VERSION "dbc-export 1 2026.26.6.5"

NS_ :

BS_:

BU_: ADSP APB APP APS APSB BB BMS CC CMP CMPD CP DAS DI DIF DIR DPB EPAS3P EPAS3S EPASTP EPASTS EPBL EPBR ESP EVSE FC GTW HCML HCMR HVP IBST ICR IDB LS OCS1P PARK PCS PCS2 PM PMF PMR PNCD PTC RADC RCM RCM2 RCM3 RCU SCCM SCM SCS SDCR TAS TCU TCU2 TPMS TRCM UI UIS UMC USM V2G VC VCBATT VCBATT0 VCBATT1 VCBATT2 VCCC VCFRONT VCFRONT1 VCFRONT2 VCLEFT VCRIGHT VCSEAT2L VCSEAT2R VCSEC VEH

BO_ 789 DIR_temperature: 8 DIR
 SG_ DIR_tempIndex M : 0|3@1+ (1,0) [0|7] "" Vector__XXX
 SG_ DIR_inverterTQF m0 : 3|2@1+ (1,0) [0|3] "" Vector__XXX
 SG_ DIR_pcbT m0 : 8|8@1+ (1,-40) [-40|215] "DegC" Vector__XXX
 SG_ DIR_inverterT m0 : 16|8@1+ (1,-40) [-40|215] "DegC" Vector__XXX
 SG_ DIR_statorT m0 : 24|8@1+ (1,-40) [-40|215] "DegC" Vector__XXX
 SG_ DIR_dcCapT m0 : 32|8@1+ (1,-40) [-40|215] "DegC" Vector__XXX
 SG_ DIR_heatsinkT m0 : 40|8@1+ (1,-40) [-40|215] "DegC" Vector__XXX
 SG_ DIR_inverterTpct m0 : 48|8@1+ (0.4,0) [0|100] "%" Vector__XXX
 SG_ DIR_statorTpct m0 : 56|8@1+ (0.4,0) [0|100] "%" Vector__XXX
 SG_ DIR_fluidInTemp m2 : 8|8@1+ (1,-40) [-40|215] "DegC" Vector__XXX
 SG_ DIR_normalFetBurnIn m2 : 16|16@1+ (0.00763,0) [0|500] "Hours" Vector__XXX
 SG_ DIR_additionalFetBurnIn m2 : 32|16@1+ (0.00763,0) [0|500] "Hours" Vector__XXX
 SG_ DIR_currentWeibullMiles m3 : 3|16@1+ (8,0) [0|500000] "miles" Vector__XXX
 SG_ DIR_endOfServiceWeibullMiles m3 : 19|16@1+ (8,0) [0|500000] "miles" Vector__XXX
 SG_ DIR_burnInDamageRatio m3 : 35|9@1+ (0.01,0) [0|5] "1" Vector__XXX
 SG_ DIR_inverterSensorEst m3 : 44|8@1+ (1,-40) [-40|120] "C" Vector__XXX
 SG_ DIR_inverterHS1Est m3 : 52|8@1+ (1,-40) [-40|120] "C" Vector__XXX
 SG_ DIR_initialBurnInVehicleOdometer m4 : 8|32@1+ (0.001,0) [0|4294967.294] "km" Vector__XXX
 SG_ DIR_inverterHS2Est m4 : 40|8@1+ (1,-40) [-40|120] "C" Vector__XXX
 SG_ DIR_inverterInletEst m4 : 48|8@1+ (1,-40) [-40|120] "C" Vector__XXX
 SG_ DIR_statorHousingTemp m4 : 56|8@1+ (1,-40) [-40|215] "DegC" Vector__XXX

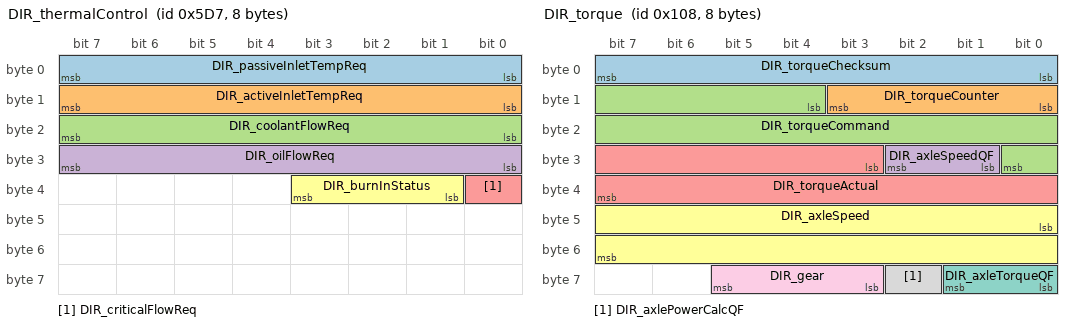
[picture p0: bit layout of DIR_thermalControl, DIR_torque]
BO_ 1495 DIR_thermalControl: 8 DIR
 SG_ DIR_passiveInletTempReq : 0|8@1+ (1,-40) [-40|215] "DegC" Vector__XXX
 SG_ DIR_activeInletTempReq : 8|8@1+ (1,-40) [-40|215] "DegC" Vector__XXX
 SG_ DIR_coolantFlowReq : 16|8@1+ (0.2,0) [0|50] "LPM" Vector__XXX
 SG_ DIR_oilFlowReq : 24|8@1+ (0.1,0) [0|25.4] "LPM" Vector__XXX
 SG_ DIR_criticalFlowReq : 32|1@1+ (1,0) [0|1] "" Vector__XXX
 SG_ DIR_burnInStatus : 33|3@1+ (1,0) [0|7] "" Vector__XXX

BO_ 264 DIR_torque: 8 DIR
 SG_ DIR_torqueChecksum : 0|8@1+ (1,0) [0|255] "" Vector__XXX
 SG_ DIR_torqueCounter : 8|4@1+ (1,0) [0|15] "" Vector__XXX
 SG_ DIR_torqueCommand : 12|13@1- (2,0) [-7500|7500] "Nm" Vector__XXX
 SG_ DIR_axleSpeedQF : 25|2@1+ (1,0) [0|3] "" Vector__XXX
 SG_ DIR_torqueActual : 27|13@1- (2,0) [-7500|7500] "Nm" Vector__XXX
 SG_ DIR_axleSpeed : 40|16@1- (0.1,0) [-2750|2750] "RPM" Vector__XXX
 SG_ DIR_axleTorqueQF : 56|2@1+ (1,0) [0|3] "" Vector__XXX
 SG_ DIR_axlePowerCalcQF : 58|1@1+ (1,0) [0|1] "" Vector__XXX
 SG_ DIR_gear : 59|3@1+ (1,0) [0|7] "" Vector__XXX

BO_ 1319 DI_alertLog: 8 DI
 SG_ DI_alertID M : 0|8@1+ (1,0) [0|255] "" Vector__XXX
 SG_ DI_alertState : 15|1@1+ (1,0) [0|1] "" Vector__XXX
 SG_ DI_a004_unavailableReason m4 : 16|5@1+ (1,0) [0|31] "" Vector__XXX
 SG_ DI_a007_button m7 : 16|2@1+ (1,0) [0|3] "" Vector__XXX
 SG_ DI_a007_buttonStuckTime m7 : 24|15@1+ (0.25,0) [0|8191.75] "" Vector__XXX
 SG_ DI_a010_sccReset m10 : 16|1@1+ (1,0) [0|1] "" Vector__XXX
 SG_ DI_a010_hibernate m10 : 17|1@1+ (1,0) [0|1] "" Vector__XXX
 SG_ DI_a010_hwBist m10 : 18|1@1+ (1,0) [0|1] "" Vector__XXX
 SG_ DI_a010_nmiWatchdog m10 : 19|1@1+ (1,0) [0|1] "" Vector__XXX
 SG_ DI_a010_watchdog m10 : 20|1@1+ (1,0) [0|1] "" Vector__XXX
 SG_ DI_a010_clockFailNmi m10 : 21|1@1+ (1,0) [0|1] "" Vector__XXX
 SG_ DI_a010_ramUncErrorNmi m10 : 22|1@1+ (1,0) [0|1] "" Vector__XXX
 SG_ DI_a010_flashUncErrorNmi m10 : 23|1@1+ (1,0) [0|1] "" Vector__XXX
 SG_ DI_a010_cpu1signMismatchNmi m10 : 24|1@1+ (1,0) [0|1] "" Vector__XXX
 SG_ DI_a010_cpu2signMismatchNmi m10 : 25|1@1+ (1,0) [0|1] "" Vector__XXX
 SG_ DI_a010_pieVectErrorNmi m10 : 26|1@1+ (1,0) [0|1] "" Vector__XXX
 SG_ DI_a010_sysDbgNmi m10 : 27|1@1+ (1,0) [0|1] "" Vector__XXX
 SG_ DI_a010_rlNmi m10 : 28|1@1+ (1,0) [0|1] "" Vector__XXX
 SG_ DI_a010_ovfNmi m10 : 29|1@1+ (1,0) [0|1] "" Vector__XXX
 SG_ DI_a010_wdtFlags m10 : 32|16@1+ (1,0) [0|65535] "" Vector__XXX
 SG_ DI_a012_accel1SupplyV m12 : 16|16@1+ (0.001,0) [0|65.535] "" Vector__XXX
 SG_ DI_a012_accel2SupplyV m12 : 32|16@1+ (0.001,0) [0|65.535] "" Vector__XXX
 SG_ DI_a013_address m13 : 16|32@1+ (1,0) [0|4294967295] "" Vector__XXX
 SG_ DI_a013_errorType m13 : 48|4@1+ (1,0) [0|15] "" Vector__XXX
 SG_ DI_a015_reason m15 : 16|1@1+ (1,0) [0|1] "" Vector__XXX
 SG_ DI_a020_difHvilStatus m20 : 16|2@1+ (1,0) [0|3] "" Vector__XXX
 SG_ DI_a020_difStatusValid m20 : 18|1@1+ (1,0) [0|1] "" Vector__XXX
 SG_ DI_a020_dirHvilStatus m20 : 19|2@1+ (1,0) [0|3] "" Vector__XXX
 SG_ DI_a020_dirStatusValid m20 : 21|1@1+ (1,0) [0|1] "" Vector__XXX
 SG_ DI_a020_vehiclePowerState m20 : 22|2@1+ (1,0) [0|3] "" Vector__XXX
 SG_ DI_a020_hvilSystemStatus m20 : 24|2@1+ (1,0) [0|3] "" Vector__XXX
 SG_ DI_a021_packVoltage m21 : 16|16@1+ (0.1,0) [0|6553.5] "" Vector__XXX
 SG_ DI_a021_maxBusVoltage m21 : 32|16@1+ (0.1,0) [0|6553.5] "" Vector__XXX
 SG_ DI_a024_pedalPos m24 : 16|8@1+ (0.4,0) [0|102] "" Vector__XXX
 SG_ DI_a024_brakePressed m24 : 24|1@1+ (1,0) [0|1] "" Vector__XXX
 SG_ DI_a024_currentGear m24 : 25|3@1+ (1,0) [0|7] "" Vector__XXX
 SG_ DI_a025_backfillState m25 : 16|2@1+ (1,0) [0|3] "" Vector__XXX
 SG_ DI_a025_bfillUnavailableReason m25 : 18|5@1+ (1,0) [0|31] "" Vector__XXX
 SG_ DI_a036_numFaultedUnits m36 : 16|4@1+ (1,0) [0|15] "" Vector__XXX
 SG_ DI_a036_numAvailableUnits m36 : 20|4@1+ (1,0) [0|15] "" Vector__XXX
 SG_ DI_a040_torque m40 : 16|1@1+ (1,0) [0|1] "" Vector__XXX
 SG_ DI_a040_capability m40 : 17|1@1+ (1,0) [0|1] "" Vector__XXX
 SG_ DI_a040_power m40 : 18|1@1+ (1,0) [0|1] "" Vector__XXX
 SG_ DI_a040_status m40 : 19|1@1+ (1,0) [0|1] "" Vector__XXX
 SG_ DI_a040_capability2 m40 : 20|1@1+ (1,0) [0|1] "" Vector__XXX
 SG_ DI_a040_hvStatus m40 : 21|1@1+ (1,0) [0|1] "" Vector__XXX
 SG_ DI_a040_temperature m40 : 22|1@1+ (1,0) [0|1] "" Vector__XXX
 SG_ DI_a042_state4 m42 : 16|1@1+ (1,0) [0|1] "" Vector__XXX
 SG_ DI_a043_state4 m43 : 16|1@1+ (1,0) [0|1] "" Vector__XXX
 SG_ DI_a051_dcCableCurrentEst m51 : 16|16@1- (0.1,0) [-3276.8|3276.7] "" Vector__XXX
 SG_ DI_a051_packCurrent m51 : 32|16@1- (0.1,0) [-3276.8|3276.7] "" Vector__XXX
 SG_ DI_a052_torque m52 : 16|1@1+ (1,0) [0|1] "" Vector__XXX
 SG_ DI_a052_capability m52 : 17|1@1+ (1,0) [0|1] "" Vector__XXX
 SG_ DI_a052_power m52 : 18|1@1+ (1,0) [0|1] "" Vector__XXX
 SG_ DI_a052_status m52 : 19|1@1+ (1,0) [0|1] "" Vector__XXX
 SG_ DI_a052_capability2 m52 : 20|1@1+ (1,0) [0|1] "" Vector__XXX
 SG_ DI_a052_hvStatus m52 : 21|1@1+ (1,0) [0|1] "" Vector__XXX
 SG_ DI_a052_temperature m52 : 22|1@1+ (1,0) [0|1] "" Vector__XXX
 SG_ DI_a062_limpReason m62 : 16|6@1+ (1,0) [0|63] "" Vector__XXX
 SG_ DI_a063_gpoReason m63 : 16|4@1+ (1,0) [0|15] "" Vector__XXX
 SG_ DI_a064_hvState m64 : 16|3@1+ (1,0) [0|7] "" Vector__XXX
 SG_ DI_a064_vehiclePowerState m64 : 19|2@1+ (1,0) [0|3] "" Vector__XXX
 SG_ DI_a064_vehicleSpeed m64 : 24|12@1+ (0.08,-40) [-40|287.6] "" Vector__XXX
 SG_ DI_a074_recoveredGear m74 : 16|3@1+ (1,0) [0|7] "" Vector__XXX
 SG_ DI_a074_vehicleSpeed m74 : 19|12@1+ (0.08,-40) [-40|287.6] "" Vector__XXX
 SG_ DI_a074_attemptCount m74 : 32|4@1+ (1,0) [0|15] "" Vector__XXX
 SG_ DI_a074_unit0Gear m74 : 36|3@1+ (1,0) [0|7] "" Vector__XXX
 SG_ DI_a074_unit1Gear m74 : 40|3@1+ (1,0) [0|7] "" Vector__XXX
 SG_ DI_a074_unit2Gear m74 : 43|3@1+ (1,0) [0|7] "" Vector__XXX
 SG_ DI_a074_failureReason m74 : 48|4@1+ (1,0) [0|15] "" Vector__XXX
 SG_ DI_a074_epbSystemStatus m74 : 52|4@1+ (1,0) [0|15] "" Vector__XXX
 SG_ DI_a076_lvSupplyV m76 : 16|16@1+ (0.001,0) [0|65.535] "" Vector__XXX
 SG_ DI_a077_lvSupplyV m77 : 16|16@1+ (0.001,0) [0|65.535] "" Vector__XXX
 SG_ DI_a078_adcRefChan m78 : 16|4@1+ (1,0) [0|15] "" Vector__XXX
 SG_ DI_a078_adcRefLowAvg m78 : 24|16@1+ (1,0) [0|65535] "" Vector__XXX
 SG_ DI_a079_adcRefChan m79 : 16|4@1+ (1,0) [0|15] "" Vector__XXX
 SG_ DI_a079_adcRefHighAvg m79 : 24|16@1+ (1,0) [0|65535] "" Vector__XXX
 SG_ DI_a083_brakeSwitchNO m83 : 16|1@1+ (1,0) [0|1] "" Vector__XXX
 SG_ DI_a083_brakeSwitchNC m83 : 17|1@1+ (1,0) [0|1] "" Vector__XXX
 SG_ DI_a083_brakeSwitchIrrationalNO m83 : 18|1@1+ (1,0) [0|1] "" Vector__XXX
 SG_ DI_a083_brakeSwitchIrrationalNC m83 : 19|1@1+ (1,0) [0|1] "" Vector__XXX
 SG_ DI_a086_DPB_actuator3 m86 : 16|1@1+ (1,0) [0|1] "" Vector__XXX
 SG_ DI_a086_DPB_redundantBrakingStat m86 : 17|1@1+ (1,0) [0|1] "" Vector__XXX
 SG_ DI_a087_gtwCarConfig m87 : 16|1@1+ (1,0) [0|1] "" Vector__XXX
 SG_ DI_a087_gtwTime m87 : 17|1@1+ (1,0) [0|1] "" Vector__XXX
 SG_ DI_a087_gtwUpdateStatus m87 : 18|1@1+ (1,0) [0|1] "" Vector__XXX
 SG_ DI_a087_gearControl m87 : 19|1@1+ (1,0) [0|1] "" Vector__XXX
 SG_ DI_a087_carState m87 : 20|1@1+ (1,0) [0|1] "" Vector__XXX
 SG_ DI_a089_SCCM_rightStalk m89 : 16|1@1+ (1,0) [0|1] "" Vector__XXX
 SG_ DI_a090_reason m90 : 16|1@1+ (1,0) [0|1] "" Vector__XXX
 SG_ DI_a090_systemState m90 : 17|1@1+ (1,0) [0|1] "" Vector__XXX
 SG_ DI_a090_state m90 : 18|1@1+ (1,0) [0|1] "" Vector__XXX
 SG_ DI_a090_locState m90 : 19|1@1+ (1,0) [0|1] "" Vector__XXX
 SG_ DI_a090_state2 m90 : 20|1@1+ (1,0) [0|1] "" Vector__XXX
 SG_ DI_a090_state4 m90 : 21|1@1+ (1,0) [0|1] "" Vector__XXX
 SG_ DI_a091_ESP_brakeTorque m91 : 16|1@1+ (1,0) [0|1] "" Vector__XXX
 SG_ DI_a091_ESP_wheelSpeeds m91 : 17|1@1+ (1,0) [0|1] "" Vector__XXX
 SG_ DI_a091_ESP_wheelRotation m91 : 18|1@1+ (1,0) [0|1] "" Vector__XXX
 SG_ DI_a091_ESP_motorLimits m91 : 19|1@1+ (1,0) [0|1] "" Vector__XXX
 SG_ DI_a091_ESP_offsets m91 : 20|1@1+ (1,0) [0|1] "" Vector__XXX
 SG_ DI_a091_ESP_status m91 : 21|1@1+ (1,0) [0|1] "" Vector__XXX
 SG_ DI_a091_ESP_party3 m91 : 22|1@1+ (1,0) [0|1] "" Vector__XXX
 SG_ DI_a091_ESP_redundantBrakingStat m91 : 23|1@1+ (1,0) [0|1] "" Vector__XXX
 SG_ DI_a092_bmsStatus m92 : 16|1@1+ (1,0) [0|1] "" Vector__XXX
 SG_ DI_a092_bmsDriveLimits m92 : 17|1@1+ (1,0) [0|1] "" Vector__XXX
 SG_ DI_a092_bmsHvBusStatus m92 : 18|1@1+ (1,0) [0|1] "" Vector__XXX
 SG_ DI_a092_bmsPowerAvailable m92 : 19|1@1+ (1,0) [0|1] "" Vector__XXX
 SG_ DI_a092_bmsBmbMinMax m92 : 20|1@1+ (1,0) [0|1] "" Vector__XXX
 SG_ DI_a092_bmsSocStatus m92 : 21|1@1+ (1,0) [0|1] "" Vector__XXX
 SG_ DI_a092_bmsThermalStatus m92 : 22|1@1+ (1,0) [0|1] "" Vector__XXX
 SG_ DI_a092_bmsCtrStatus m92 : 23|1@1+ (1,0) [0|1] "" Vector__XXX
 SG_ DI_a092_bmsVoltageRegGain m92 : 24|1@1+ (1,0) [0|1] "" Vector__XXX
 SG_ DI_a092_bmsPackConfig m92 : 25|1@1+ (1,0) [0|1] "" Vector__XXX
 SG_ DI_a092_bmsSystemStatus m92 : 26|1@1+ (1,0) [0|1] "" Vector__XXX
 SG_ DI_a096_const_fast m96 : 16|1@1+ (1,0) [0|1] "" Vector__XXX
 SG_ DI_a096_text_fast m96 : 17|1@1+ (1,0) [0|1] "" Vector__XXX
 SG_ DI_a096_text_flash m96 : 18|1@1+ (1,0) [0|1] "" Vector__XXX
 SG_ DI_a096_mem_data m96 : 19|1@1+ (1,0) [0|1] "" Vector__XXX
 SG_ DI_a096_mem_regs m96 : 20|1@1+ (1,0) [0|1] "" Vector__XXX
 SG_ DI_a096_boot_flash m96 : 21|1@1+ (1,0) [0|1] "" Vector__XXX
 SG_ DI_a096_word1 m96 : 24|16@1+ (1,0) [0|65535] "" Vector__XXX
 SG_ DI_a096_word2 m96 : 40|16@1+ (1,0) [0|65535] "" Vector__XXX
 SG_ DI_a097_errorType m97 : 16|3@1+ (1,0) [0|7] "" Vector__XXX
 SG_ DI_a097_lineNumber m97 : 24|16@1+ (1,0) [0|65535] "" Vector__XXX
 SG_ DI_a097_argument m97 : 40|16@1+ (1,0) [0|65535] "" Vector__XXX
 SG_ DI_a098_page0Counter m98 : 16|8@1+ (1,0) [0|255] "" Vector__XXX
 SG_ DI_a098_page1Counter m98 : 24|8@1+ (1,0) [0|255] "" Vector__XXX
 SG_ DI_a098_page2Counter m98 : 32|8@1+ (1,0) [0|255] "" Vector__XXX
 SG_ DI_a098_pageID m98 : 40|2@1+ (1,0) [0|3] "" Vector__XXX
 SG_ DI_a098_recordID m98 : 42|4@1+ (1,0) [0|15] "" Vector__XXX
 SG_ DI_a098_errorCode m98 : 48|4@1+ (1,0) [0|15] "" Vector__XXX
 SG_ DI_a103_BB_status m103 : 16|1@1+ (1,0) [0|1] "" Vector__XXX
 SG_ DI_a103_BB_brakeActuation m103 : 17|1@1+ (1,0) [0|1] "" Vector__XXX
 SG_ DI_a104_proxIrrationalReason m104 : 16|1@1+ (1,0) [0|1] "" Vector__XXX
 SG_ DI_a105_cpStatus m105 : 16|1@1+ (1,0) [0|1] "" Vector__XXX
 SG_ DI_a110_EPBL_status m110 : 16|1@1+ (1,0) [0|1] "" Vector__XXX
 SG_ DI_a110_EPBR_status m110 : 17|1@1+ (1,0) [0|1] "" Vector__XXX
 SG_ DI_a110_EPBL_autonomyHealth m110 : 18|1@1+ (1,0) [0|1] "" Vector__XXX
 SG_ DI_a110_EPBR_autonomyHealth m110 : 19|1@1+ (1,0) [0|1] "" Vector__XXX
 SG_ DI_a120_blendingState m120 : 16|2@1+ (1,0) [0|3] "" Vector__XXX
 SG_ DI_a120_blendingUnavailableReaso m120 : 18|5@1+ (1,0) [0|31] "" Vector__XXX
 SG_ DI_a124_undrivenWheelMPH m124 : 16|16@1+ (0.1,0) [0|6553.5] "" Vector__XXX
 SG_ DI_a124_cruiseFaultReason m124 : 32|5@1+ (1,0) [0|31] "" Vector__XXX
 SG_ DI_a124_cruiseFaultStack m124 : 37|3@1+ (1,0) [0|7] "" Vector__XXX
 SG_ DI_a125_maxDischargeCurrent m125 : 16|16@1- (0.1,0) [-3276.8|3276.7] "" Vector__XXX
 SG_ DI_a125_maxChargeCurrent m125 : 32|16@1- (0.1,0) [-3276.8|3276.7] "" Vector__XXX
 SG_ DI_a125_minBusVoltage m125 : 48|16@1+ (0.1,0) [0|6553.5] "" Vector__XXX
 SG_ DI_a130_aebFaultReason m130 : 16|4@1+ (1,0) [0|15] "" Vector__XXX
 SG_ DI_a130_aebSmState m130 : 20|3@1+ (1,0) [0|7] "" Vector__XXX
 SG_ DI_a130_dasAebEvent m130 : 24|2@1+ (1,0) [0|3] "" Vector__XXX
 SG_ DI_a130_aebBrakeTorqueCommand m130 : 26|13@1+ (3,0) [0|24573] "" Vector__XXX
 SG_ DI_a131_totalTimeRemaining m131 : 16|16@1+ (1,0) [0|65535] "" Vector__XXX
 SG_ DI_a131_warnSpeedLimit m131 : 32|16@1+ (1,0) [0|65535] "" Vector__XXX
 SG_ DI_a131_warnTimeRemaining m131 : 48|16@1+ (1,0) [0|65535] "" Vector__XXX
 SG_ DI_a133_vhldSmState m133 : 16|4@1+ (1,0) [0|15] "" Vector__XXX
 SG_ DI_a133_reverseGear m133 : 20|1@1+ (1,0) [0|1] "" Vector__XXX
 SG_ DI_a133_vhldGrade m133 : 24|8@1+ (0.01,-1) [-1|1.55] "" Vector__XXX
 SG_ DI_a134_wheelSpeedDiffFrL m134 : 16|12@1- (0.0625,0) [-128|127.9375] "" Vector__XXX
 SG_ DI_a134_wheelSpeedDiffFrR m134 : 28|12@1- (0.0625,0) [-128|127.9375] "" Vector__XXX
 SG_ DI_a134_wheelSpeedDiffReL m134 : 40|12@1- (0.0625,0) [-128|127.9375] "" Vector__XXX
 SG_ DI_a134_wheelSpeedDiffReR m134 : 52|12@1- (0.0625,0) [-128|127.9375] "" Vector__XXX
 SG_ DI_a135_vhldFaultReason m135 : 16|4@1+ (1,0) [0|15] "" Vector__XXX
 SG_ DI_a135_vhldSmState m135 : 20|4@1+ (1,0) [0|15] "" Vector__XXX
 SG_ DI_a135_vhldBrakeApply m135 : 24|1@1+ (1,0) [0|1] "" Vector__XXX
 SG_ DI_a135_vhldBrakeTorqueCommand m135 : 25|10@1+ (10,0) [0|10230] "" Vector__XXX
 SG_ DI_a135_vhldTotalBrakeTorque m135 : 35|10@1+ (10,0) [0|10230] "" Vector__XXX
 SG_ DI_a135_vhldPropulsiveTorque m135 : 45|10@1- (1,0) [-512|511] "" Vector__XXX
 SG_ DI_a135_vhldGrade m135 : 56|8@1+ (0.01,-1) [-1|1.55] "" Vector__XXX
 SG_ DI_a140_PTC_feedbackStatus m140 : 16|1@1+ (1,0) [0|1] "" Vector__XXX
 SG_ DI_a141_DAS_control m141 : 16|1@1+ (1,0) [0|1] "" Vector__XXX
 SG_ DI_a141_DAS_pmmControl m141 : 17|1@1+ (1,0) [0|1] "" Vector__XXX
 SG_ DI_a141_DAS_status m141 : 18|1@1+ (1,0) [0|1] "" Vector__XXX
 SG_ DI_a141_DAS_status2 m141 : 19|1@1+ (1,0) [0|1] "" Vector__XXX
 SG_ DI_a141_DAS_smartShift m141 : 20|1@1+ (1,0) [0|1] "" Vector__XXX
 SG_ DI_a141_DAS_longControl m141 : 21|1@1+ (1,0) [0|1] "" Vector__XXX
 SG_ DI_a141_DAS_longControlTuningPar m141 : 22|1@1+ (1,0) [0|1] "" Vector__XXX
 SG_ DI_a141_DAS_autonomyControl m141 : 23|1@1+ (1,0) [0|1] "" Vector__XXX
 SG_ DI_a141_DAS_redundantBrakingCont m141 : 24|1@1+ (1,0) [0|1] "" Vector__XXX
 SG_ DI_a143_mechPowerLimit m143 : 16|1@1+ (1,0) [0|1] "" Vector__XXX
 SG_ DI_a143_systemTorqueLimit m143 : 17|1@1+ (1,0) [0|1] "" Vector__XXX
 SG_ DI_a144_autopilot m144 : 16|1@1+ (1,0) [0|1] "" Vector__XXX
 SG_ DI_a144_chassisType m144 : 17|1@1+ (1,0) [0|1] "" Vector__XXX
 SG_ DI_a144_drivetrainType m144 : 18|1@1+ (1,0) [0|1] "" Vector__XXX
 SG_ DI_a144_packEnergy m144 : 19|1@1+ (1,0) [0|1] "" Vector__XXX
 SG_ DI_a144_packPerformanceDeviation m144 : 20|1@1+ (1,0) [0|1] "" Vector__XXX
 SG_ DI_a144_performancePackage m144 : 21|1@1+ (1,0) [0|1] "" Vector__XXX
 SG_ DI_a144_vdcType m144 : 22|1@1+ (1,0) [0|1] "" Vector__XXX
 SG_ DI_a144_brakeHWType m144 : 23|1@1+ (1,0) [0|1] "" Vector__XXX
 SG_ DI_a144_inverterHardware m144 : 24|1@1+ (1,0) [0|1] "" Vector__XXX
 SG_ DI_a144_cabinPTCHeaterType m144 : 25|1@1+ (1,0) [0|1] "" Vector__XXX
 SG_ DI_a144_frunkLatchType m144 : 26|1@1+ (1,0) [0|1] "" Vector__XXX
 SG_ DI_a144_platformMaxBusVoltage m144 : 27|1@1+ (1,0) [0|1] "" Vector__XXX
 SG_ DI_a144_oilPump1HwType m144 : 28|1@1+ (1,0) [0|1] "" Vector__XXX
 SG_ DI_a144_oilPump2HwType m144 : 29|1@1+ (1,0) [0|1] "" Vector__XXX
 SG_ DI_a144_heatsinkType m144 : 30|1@1+ (1,0) [0|1] "" Vector__XXX
 SG_ DI_a144_softPerformanceLimit m144 : 31|1@1+ (1,0) [0|1] "" Vector__XXX
 SG_ DI_a144_brakeActuationType m144 : 32|1@1+ (1,0) [0|1] "" Vector__XXX
 SG_ DI_a144_dasHw m144 : 33|1@1+ (1,0) [0|1] "" Vector__XXX
 SG_ DI_a144_powerLiftgateType m144 : 34|1@1+ (1,0) [0|1] "" Vector__XXX
 SG_ DI_a144_chassisSubType m144 : 35|1@1+ (1,0) [0|1] "" Vector__XXX
 SG_ DI_a144_autonomyFeatureType m144 : 36|1@1+ (1,0) [0|1] "" Vector__XXX
 SG_ DI_a146_panicReason m146 : 16|3@1+ (1,0) [0|7] "" Vector__XXX
 SG_ DI_a155_sensors m155 : 16|1@1+ (1,0) [0|1] "" Vector__XXX
 SG_ DI_a155_coolant m155 : 17|1@1+ (1,0) [0|1] "" Vector__XXX
 SG_ DI_a155_LVPowerState m155 : 18|1@1+ (1,0) [0|1] "" Vector__XXX
 SG_ DI_a155_vehicleStatus m155 : 19|1@1+ (1,0) [0|1] "" Vector__XXX
 SG_ DI_a155_status m155 : 20|1@1+ (1,0) [0|1] "" Vector__XXX
 SG_ DI_a155_leftDoorStatus m155 : 21|1@1+ (1,0) [0|1] "" Vector__XXX
 SG_ DI_a155_rightDoorStatus m155 : 22|1@1+ (1,0) [0|1] "" Vector__XXX
 SG_ DI_a155_vcleftSwitchStatus m155 : 23|1@1+ (1,0) [0|1] "" Vector__XXX
 SG_ DI_a155_restraintStatus m155 : 24|1@1+ (1,0) [0|1] "" Vector__XXX
 SG_ DI_a155_systemStatus m155 : 25|1@1+ (1,0) [0|1] "" Vector__XXX
 SG_ DI_a155_prndStatus m155 : 26|1@1+ (1,0) [0|1] "" Vector__XXX
 SG_ DI_a155_liftgateStatus m155 : 27|1@1+ (1,0) [0|1] "" Vector__XXX
 SG_ DI_a157_RCM_inertial1 m157 : 16|1@1+ (1,0) [0|1] "" Vector__XXX
 SG_ DI_a157_RCM_inertial2 m157 : 17|1@1+ (1,0) [0|1] "" Vector__XXX
 SG_ DI_a158_IBST_party1 m158 : 16|1@1+ (1,0) [0|1] "" Vector__XXX
 SG_ DI_a158_BUS1_IBST_status m158 : 17|1@1+ (1,0) [0|1] "" Vector__XXX
 SG_ DI_a158_BUS2_IBST_status m158 : 18|1@1+ (1,0) [0|1] "" Vector__XXX
 SG_ DI_a158_IBST_redundantBrakingSta m158 : 19|1@1+ (1,0) [0|1] "" Vector__XXX
 SG_ DI_a160_kTire m160 : 16|7@1+ (0.001,0.008) [0.008|0.135] "" Vector__XXX
 SG_ DI_a160_tireFitment m160 : 24|2@1+ (1,0) [0|3] "" Vector__XXX
 SG_ DI_a160_wearFactorFrL m160 : 26|6@1+ (0.00125,0.96) [0.96|1.03875] "" Vector__XXX
 SG_ DI_a160_wearFactorFrR m160 : 32|6@1+ (0.00125,0.96) [0.96|1.03875] "" Vector__XXX
 SG_ DI_a160_wearFactorReL m160 : 40|6@1+ (0.00125,0.96) [0.96|1.03875] "" Vector__XXX
 SG_ DI_a160_distanceSinceLastTireCon m160 : 48|12@1+ (0.01,0) [0|40.95] "" Vector__XXX
 SG_ DI_a161_EPAS3P_sysStatus m161 : 16|1@1+ (1,0) [0|1] "" Vector__XXX
 SG_ DI_a161_EPAS3P_angleCalib m161 : 17|1@1+ (1,0) [0|1] "" Vector__XXX
 SG_ DI_a162_shiftDeniedReason m162 : 16|4@1+ (1,0) [0|15] "" Vector__XXX
 SG_ DI_a162_motorSpeed m162 : 20|10@1- (0.2,0) [-102.4|102.2] "" Vector__XXX
 SG_ DI_a162_essContClosed m162 : 30|1@1+ (1,0) [0|1] "" Vector__XXX
 SG_ DI_a162_autonomyBehavior m162 : 31|2@1+ (1,0) [0|3] "" Vector__XXX
 SG_ DI_a162_pedalPos m162 : 33|7@1+ (0.8,0) [0|101.6] "" Vector__XXX
 SG_ DI_a162_currentGear m162 : 40|3@1+ (1,0) [0|7] "" Vector__XXX
 SG_ DI_a162_requestedGear m162 : 43|3@1+ (1,0) [0|7] "" Vector__XXX
 SG_ DI_a162_requestSource m162 : 46|4@1+ (1,0) [0|15] "" Vector__XXX
 SG_ DI_a162_timeSinceCruiseCancel m162 : 50|7@1+ (0.5,0) [0|63.5] "" Vector__XXX
 SG_ DI_a162_chargeCableConnected m162 : 57|1@1+ (1,0) [0|1] "" Vector__XXX
 SG_ DI_a162_frunkOpen m162 : 58|1@1+ (1,0) [0|1] "" Vector__XXX
 SG_ DI_a162_sysStateExitCondition m162 : 59|5@1+ (1,0) [0|31] "" Vector__XXX
 SG_ DI_a163_motorSpeed m163 : 16|16@1- (0.01,0) [-327.68|327.67] "" Vector__XXX
 SG_ DI_a163_currentGear m163 : 32|3@1+ (1,0) [0|7] "" Vector__XXX
 SG_ DI_a163_requestedGear m163 : 35|3@1+ (1,0) [0|7] "" Vector__XXX
 SG_ DI_a163_requestSource m163 : 40|4@1+ (1,0) [0|15] "" Vector__XXX
 SG_ DI_a164_motorSpeed m164 : 16|16@1- (0.01,0) [-327.68|327.67] "" Vector__XXX
 SG_ DI_a164_pedalPos m164 : 32|8@1+ (0.4,0) [0|102] "" Vector__XXX
 SG_ DI_a164_torqueDriver m164 : 40|14@1- (0.2,0) [-1638.4|1638.2] "" Vector__XXX
 SG_ DI_a170_tireSeasonSelected m170 : 16|1@1+ (1,0) [0|1] "" Vector__XXX
 SG_ DI_a170_kTire m170 : 17|7@1+ (0.001,0.008) [0.008|0.135] "" Vector__XXX
 SG_ DI_a170_tireFitment m170 : 24|2@1+ (1,0) [0|3] "" Vector__XXX
 SG_ DI_a170_wearFactorFrL m170 : 26|6@1+ (0.00125,0.96) [0.96|1.03875] "" Vector__XXX
 SG_ DI_a170_wearFactorFrR m170 : 32|6@1+ (0.00125,0.96) [0.96|1.03875] "" Vector__XXX
 SG_ DI_a170_wearFactorReL m170 : 38|6@1+ (0.00125,0.96) [0.96|1.03875] "" Vector__XXX
 SG_ DI_a170_odometer m170 : 44|12@1+ (500,0) [0|2047500] "" Vector__XXX
 SG_ DI_a170_distanceSinceLastTireCon m170 : 56|6@1+ (500,0) [0|31500] "" Vector__XXX
 SG_ DI_a170_treadDepthAlertSet m170 : 62|1@1+ (1,0) [0|1] "" Vector__XXX
 SG_ DI_a172_motorSpeed m172 : 16|16@1- (0.01,0) [-327.68|327.67] "" Vector__XXX
 SG_ DI_a172_pedalPos m172 : 32|8@1+ (0.4,0) [0|102] "" Vector__XXX
 SG_ DI_a172_currentGear m172 : 40|3@1+ (1,0) [0|7] "" Vector__XXX
 SG_ DI_a172_timeSinceCruiseCancel m172 : 48|7@1+ (0.5,0) [0|63.5] "" Vector__XXX
 SG_ DI_a173_brakeApply m173 : 16|16@1- (0.01,0) [-327.68|327.67] "" Vector__XXX
 SG_ DI_a173_pedalPos m173 : 32|8@1+ (0.4,0) [0|102] "" Vector__XXX
 SG_ DI_a175_crsNotAvailableReason m175 : 16|6@1+ (1,0) [0|63] "" Vector__XXX
 SG_ DI_a175_crsNotAvailableStack m175 : 24|3@1+ (1,0) [0|7] "" Vector__XXX
 SG_ DI_a177_newFitment m177 : 16|2@1+ (1,0) [0|3] "" Vector__XXX
 SG_ DI_a178_offsetValue m178 : 16|8@1- (0.16,0) [-20.48|20.32] "" Vector__XXX
 SG_ DI_a180_crsNotAvailableReason m180 : 16|6@1+ (1,0) [0|63] "" Vector__XXX
 SG_ DI_a184_apcCancelReason m184 : 16|5@1+ (1,0) [0|31] "" Vector__XXX
 SG_ DI_a184_apcUnavailableReason m184 : 24|4@1+ (1,0) [0|15] "" Vector__XXX
 SG_ DI_a184_autoparkInternalState m184 : 32|5@1+ (1,0) [0|31] "" Vector__XXX
 SG_ DI_a185_summonActive m185 : 16|1@1+ (1,0) [0|1] "" Vector__XXX
 SG_ DI_a185_apcCancelReason m185 : 17|5@1+ (1,0) [0|31] "" Vector__XXX
 SG_ DI_a185_apcUnavailableReason m185 : 24|4@1+ (1,0) [0|15] "" Vector__XXX
 SG_ DI_a185_crsNotAvailableReason m185 : 32|6@1+ (1,0) [0|63] "" Vector__XXX
 SG_ DI_a185_crsFaultReason m185 : 40|5@1+ (1,0) [0|31] "" Vector__XXX
 SG_ DI_a185_autoparkInternalState m185 : 48|5@1+ (1,0) [0|31] "" Vector__XXX
 SG_ DI_a187_filteredAccel m187 : 16|16@1- (0.01,0) [-327.68|327.67] "" Vector__XXX
 SG_ DI_a187_rawPedal m187 : 32|8@1+ (0.4,0) [0|102] "" Vector__XXX
 SG_ DI_a187_systemTorqueCommand m187 : 40|16@1- (1,0) [-32768|32767] "" Vector__XXX
 SG_ DI_a189_accelPedal m189 : 16|5@1+ (3.125,0) [0|96.875] "" Vector__XXX
 SG_ DI_a189_grade m189 : 24|4@1- (4,0) [-32|28] "" Vector__XXX
 SG_ DI_a189_brakePressed m189 : 28|1@1+ (1,0) [0|1] "" Vector__XXX
 SG_ DI_a189_systemTorque m189 : 32|8@1- (10,0) [-1280|1270] "" Vector__XXX
 SG_ DI_a189_motorSpeed m189 : 40|5@1- (0.5,0) [-8|7.5] "" Vector__XXX
 SG_ DI_a190_relativeTireTreadDepth m190 : 16|6@1+ (0.2,0) [0|12.6] "" Vector__XXX
 SG_ DI_a190_treadWearFactorFrL m190 : 24|6@1+ (0.001,0.969) [0.969|1.032] "" Vector__XXX
 SG_ DI_a190_treadWearFactorFrR m190 : 32|6@1+ (0.001,0.969) [0.969|1.032] "" Vector__XXX
 SG_ DI_a190_treadWearFactorReL m190 : 40|6@1+ (0.001,0.969) [0.969|1.032] "" Vector__XXX
 SG_ DI_a190_treadWearFactorAvgConfid m190 : 48|5@1+ (0.05,0) [0|1.55] "" Vector__XXX
 SG_ DI_a190_tireFitment m190 : 53|2@1+ (1,0) [0|3] "" Vector__XXX
 SG_ DI_a191_motorSpeed m191 : 16|16@1- (0.01,0) [-327.68|327.67] "" Vector__XXX
 SG_ DI_a191_reverseDeniedAfterCruise m191 : 32|1@1+ (1,0) [0|1] "" Vector__XXX
 SG_ DI_a191_currentGear m191 : 33|3@1+ (1,0) [0|7] "" Vector__XXX
 SG_ DI_a191_requestedGear m191 : 36|3@1+ (1,0) [0|7] "" Vector__XXX
 SG_ DI_a191_requestSource m191 : 40|4@1+ (1,0) [0|15] "" Vector__XXX
 SG_ DI_a191_timeSinceCruiseCancel m191 : 48|7@1+ (0.5,0) [0|63.5] "" Vector__XXX
 SG_ DI_a193_brakeTorqueFrL m193 : 16|3@1+ (1,0) [0|7] "" Vector__XXX
 SG_ DI_a193_brakeTorqueFrLLastVal m193 : 19|10@1+ (12,0) [0|12276] "" Vector__XXX
 SG_ DI_a193_brakeTorqueFrLCurrVal m193 : 29|10@1+ (12,0) [0|12276] "" Vector__XXX
 SG_ DI_a193_brakeTorqueFrR m193 : 40|3@1+ (1,0) [0|7] "" Vector__XXX
 SG_ DI_a193_brakeTorqueFrRLastVal m193 : 43|10@1+ (12,0) [0|12276] "" Vector__XXX
 SG_ DI_a193_brakeTorqueFrRCurrVal m193 : 53|10@1+ (12,0) [0|12276] "" Vector__XXX
 SG_ DI_a194_brakeTorqueReL m194 : 16|3@1+ (1,0) [0|7] "" Vector__XXX
 SG_ DI_a194_brakeTorqueReLLastVal m194 : 19|10@1+ (12,0) [0|12276] "" Vector__XXX
 SG_ DI_a194_brakeTorqueReLCurrVal m194 : 29|10@1+ (12,0) [0|12276] "" Vector__XXX
 SG_ DI_a194_brakeTorqueReR m194 : 40|3@1+ (1,0) [0|7] "" Vector__XXX
 SG_ DI_a194_brakeTorqueReRLastVal m194 : 43|10@1+ (12,0) [0|12276] "" Vector__XXX
 SG_ DI_a194_brakeTorqueReRCurrVal m194 : 53|10@1+ (12,0) [0|12276] "" Vector__XXX
 SG_ DI_a198_MCPressure m198 : 16|3@1+ (1,0) [0|7] "" Vector__XXX
 SG_ DI_a198_MCPressureLastValue m198 : 19|10@1- (0.3,123.6) [-30|276.9] "" Vector__XXX
 SG_ DI_a198_MCPressCurrValue m198 : 29|10@1- (0.3,123.6) [-30|276.9] "" Vector__XXX
 SG_ DI_a198_steeringAngle m198 : 40|3@1+ (1,0) [0|7] "" Vector__XXX
 SG_ DI_a198_steeringAngleLastVal m198 : 43|10@1- (1.6,0) [-819.2|817.6] "" Vector__XXX
 SG_ DI_a198_steeringAngleCurrVal m198 : 53|10@1- (1.6,0) [-819.2|817.6] "" Vector__XXX
 SG_ DI_a199_muVehicleLearnDown m199 : 16|5@1+ (0.05,0) [0|1.55] "" Vector__XXX
 SG_ DI_a199_muVehicleDecFilt m199 : 21|5@1+ (0.05,0) [0|1.55] "" Vector__XXX
 SG_ DI_a199_bankAngle m199 : 26|6@1- (0.016,0) [-0.512|0.496] "" Vector__XXX
 SG_ DI_a199_lateralAccelFilt m199 : 32|6@1- (0.5,0) [-16|15.5] "" Vector__XXX
 SG_ DI_a199_driverIntendedYawRate m199 : 38|7@1- (0.024,0) [-1.536|1.512] "" Vector__XXX
 SG_ DI_a199_vehicleVelocity m199 : 45|5@1+ (2,0) [0|62] "" Vector__XXX
 SG_ DI_a199_sensorYawRate m199 : 50|7@1- (0.024,0) [-1.536|1.512] "" Vector__XXX
 SG_ DI_a199_preControlActive m199 : 57|1@1+ (1,0) [0|1] "" Vector__XXX
 SG_ DI_a199_oversteerdMzActive m199 : 58|1@1+ (1,0) [0|1] "" Vector__XXX
 SG_ DI_a199_decelControlActive m199 : 59|1@1+ (1,0) [0|1] "" Vector__XXX
 SG_ DI_a199_understeerdMzActive m199 : 60|1@1+ (1,0) [0|1] "" Vector__XXX
 SG_ DI_a199_vdcMode m199 : 61|2@1+ (1,0) [0|3] "" Vector__XXX
 SG_ DI_a200_MBPCheckStatus m200 : 16|1@1+ (1,0) [0|1] "" Vector__XXX
 SG_ DI_a200_MBPFailedCase m200 : 17|6@1+ (1,0) [0|63] "" Vector__XXX
 SG_ DI_a200_MBPFaultProbability m200 : 24|10@1+ (0.008,0) [0|8.184] "" Vector__XXX
 SG_ DI_a202_reason m202 : 16|4@1+ (1,0) [0|15] "" Vector__XXX
 SG_ DI_a202_movement m202 : 20|9@1+ (0.005,0) [0|2.555] "" Vector__XXX
 SG_ DI_a202_sysStateExitCondition m202 : 32|5@1+ (1,0) [0|31] "" Vector__XXX
 SG_ DI_a203_ptcStateLocal m203 : 16|3@1+ (1,0) [0|7] "" Vector__XXX
 SG_ DI_a203_btcState m203 : 19|1@1+ (1,0) [0|1] "" Vector__XXX
 SG_ DI_a204_longAccel m204 : 16|3@1+ (1,0) [0|7] "" Vector__XXX
 SG_ DI_a204_longAccelLastVal m204 : 19|10@1- (0.08,0) [-40.96|40.88] "" Vector__XXX
 SG_ DI_a204_longAccelCurrVal m204 : 29|10@1- (0.08,0) [-40.96|40.88] "" Vector__XXX
 SG_ DI_a204_rollRate m204 : 40|3@1+ (1,0) [0|7] "" Vector__XXX
 SG_ DI_a204_rollRateLastVal m204 : 43|10@1- (0.006,0) [-3.072|3.066] "" Vector__XXX
 SG_ DI_a204_rollRateCurrVal m204 : 53|10@1- (0.006,0) [-3.072|3.066] "" Vector__XXX
 SG_ DI_a205_latAccel m205 : 16|3@1+ (1,0) [0|7] "" Vector__XXX
 SG_ DI_a205_latAccelLastVal m205 : 19|10@1- (0.08,0) [-40.96|40.88] "" Vector__XXX
 SG_ DI_a205_latAccelCurrVal m205 : 29|10@1- (0.08,0) [-40.96|40.88] "" Vector__XXX
 SG_ DI_a205_pitchRate m205 : 40|3@1+ (1,0) [0|7] "" Vector__XXX
 SG_ DI_a205_pitchRateLastVal m205 : 43|10@1- (0.006,0) [-3.072|3.066] "" Vector__XXX
 SG_ DI_a205_pitchRateCurrVal m205 : 53|10@1- (0.006,0) [-3.072|3.066] "" Vector__XXX
 SG_ DI_a206_verticalAccel m206 : 16|3@1+ (1,0) [0|7] "" Vector__XXX
 SG_ DI_a206_verticalAccelLastVal m206 : 19|10@1- (0.08,0) [-40.96|40.88] "" Vector__XXX
 SG_ DI_a206_verticalAccelCurrVal m206 : 29|10@1- (0.08,0) [-40.96|40.88] "" Vector__XXX
 SG_ DI_a206_yawRate m206 : 40|3@1+ (1,0) [0|7] "" Vector__XXX
 SG_ DI_a206_yawRateLastVal m206 : 43|10@1- (0.006,0) [-3.072|3.066] "" Vector__XXX
 SG_ DI_a206_yawRateCurrVal m206 : 53|10@1- (0.006,0) [-3.072|3.066] "" Vector__XXX
 SG_ DI_a210_ptcStateGlobal m210 : 16|2@1+ (1,0) [0|3] "" Vector__XXX
 SG_ DI_a210_espActuatorState m210 : 18|2@1+ (1,0) [0|3] "" Vector__XXX
 SG_ DI_a210_brakeTmpEstStateFaulted m210 : 20|1@1+ (1,0) [0|1] "" Vector__XXX
 SG_ DI_a210_secondaryBrakeActuatorIs m210 : 21|1@1+ (1,0) [0|1] "" Vector__XXX
 SG_ DI_a223_ptcStateLocal m223 : 16|3@1+ (1,0) [0|7] "" Vector__XXX
 SG_ DI_a223_btcState m223 : 19|1@1+ (1,0) [0|1] "" Vector__XXX
 SG_ DI_a223_velocityEstimatorState m223 : 20|3@1+ (1,0) [0|7] "" Vector__XXX
 SG_ DI_a223_addState_dir m223 : 24|2@1+ (1,0) [0|3] "" Vector__XXX
 SG_ DI_a223_addState_dif m223 : 26|2@1+ (1,0) [0|3] "" Vector__XXX
 SG_ DI_a223_DI_tractionControlMode m223 : 28|3@1+ (1,0) [0|7] "" Vector__XXX
 SG_ DI_a223_UI_tractionControlMode m223 : 32|3@1+ (1,0) [0|7] "" Vector__XXX
 SG_ DI_a223_vehicleVelocity m223 : 40|7@1- (1,48) [-16|111] "" Vector__XXX
 SG_ DI_a223_musurf m223 : 48|4@1+ (0.1,0) [0|1.5] "" Vector__XXX
 SG_ DI_a223_musurfHigh m223 : 52|4@1+ (0.1,0) [0|1.5] "" Vector__XXX
 SG_ DI_a223_driveTCActive m223 : 56|1@1+ (1,0) [0|1] "" Vector__XXX
 SG_ DI_a223_regenTCActive m223 : 57|1@1+ (1,0) [0|1] "" Vector__XXX
 SG_ DI_a223_surfaceUtility m223 : 58|3@1+ (15,0) [0|105] "" Vector__XXX
 SG_ DI_a224_brakeFLTemp m224 : 16|10@1- (1,300) [-212|811] "" Vector__XXX
 SG_ DI_a224_brakeFRTemp m224 : 26|10@1- (1,300) [-212|811] "" Vector__XXX
 SG_ DI_a224_brakeRLTemp m224 : 36|10@1- (1,300) [-212|811] "" Vector__XXX
 SG_ DI_a224_brakeRRTemp m224 : 46|10@1- (1,300) [-212|811] "" Vector__XXX
 SG_ DI_a227_hvState m227 : 16|3@1+ (1,0) [0|7] "" Vector__XXX
 SG_ DI_a227_vehiclePowerState m227 : 19|2@1+ (1,0) [0|3] "" Vector__XXX
 SG_ DI_a230_CMP_HVStatus m230 : 16|1@1+ (1,0) [0|1] "" Vector__XXX
 SG_ DI_a230_CMPD_state m230 : 17|1@1+ (1,0) [0|1] "" Vector__XXX
 SG_ DI_a232_velocityEstimatorState m232 : 16|3@1+ (1,0) [0|7] "" Vector__XXX
 SG_ DI_a232_UI_tractionControlMode m232 : 19|3@1+ (1,0) [0|7] "" Vector__XXX
 SG_ DI_a232_vehicleVelocity m232 : 24|6@1+ (1,0) [0|63] "" Vector__XXX
 SG_ DI_a232_musurf m232 : 32|3@1+ (0.15,0.15) [0.15|1.2] "" Vector__XXX
 SG_ DI_a232_musurfHigh m232 : 35|3@1+ (0.15,0.15) [0.15|1.2] "" Vector__XXX
 SG_ DI_a232_allWhlSpeedRotationAvail m232 : 38|1@1+ (1,0) [0|1] "" Vector__XXX
 SG_ DI_a232_BrakeMasterCylPressValid m232 : 39|1@1+ (1,0) [0|1] "" Vector__XXX
 SG_ DI_a232_WheelBrakeTorquesValid m232 : 40|1@1+ (1,0) [0|1] "" Vector__XXX
 SG_ DI_a232_AbsBrakeEventActiveValid m232 : 41|1@1+ (1,0) [0|1] "" Vector__XXX
 SG_ DI_a232_UndersteerActiveValid m232 : 42|1@1+ (1,0) [0|1] "" Vector__XXX
 SG_ DI_a232_OversteerActiveValid m232 : 43|1@1+ (1,0) [0|1] "" Vector__XXX
 SG_ DI_a232_allMotorTorquesValid m232 : 44|1@1+ (1,0) [0|1] "" Vector__XXX
 SG_ DI_a232_lateralAccelValid m232 : 45|1@1+ (1,0) [0|1] "" Vector__XXX
 SG_ DI_a232_longitudinalAccelValid m232 : 46|1@1+ (1,0) [0|1] "" Vector__XXX
 SG_ DI_a232_yawRateValid m232 : 47|1@1+ (1,0) [0|1] "" Vector__XXX
 SG_ DI_a232_steerAngleValid m232 : 48|1@1+ (1,0) [0|1] "" Vector__XXX
 SG_ DI_a236_states m236 : 16|1@1+ (1,0) [0|1] "" Vector__XXX
 SG_ DI_a237_lateralAccel m237 : 16|8@1- (0.25,0) [-32|31.75] "" Vector__XXX
 SG_ DI_a237_verticalAccel m237 : 24|8@1- (0.25,0) [-32|31.75] "" Vector__XXX
 SG_ DI_a237_longitudinalAccel m237 : 32|8@1- (0.25,0) [-32|31.75] "" Vector__XXX
 SG_ DI_a237_vehicleSpeed m237 : 40|6@1+ (1,0) [0|63] "" Vector__XXX
 SG_ DI_a239_numRequests m239 : 16|16@1+ (1,0) [0|65535] "" Vector__XXX
 SG_ DI_a243_RCU_status m243 : 16|1@1+ (1,0) [0|1] "" Vector__XXX
 SG_ DI_a243_RCU_actuation m243 : 17|1@1+ (1,0) [0|1] "" Vector__XXX
 SG_ DI_a245_ebrStatus m245 : 16|2@1+ (1,0) [0|3] "" Vector__XXX
 SG_ DI_a245_vehicleHoldState m245 : 18|3@1+ (1,0) [0|7] "" Vector__XXX
 SG_ DI_a246_onePedalDrivingState m246 : 16|4@1+ (1,0) [0|15] "" Vector__XXX
 SG_ DI_a246_opdUnavailableReason m246 : 24|5@1+ (1,0) [0|31] "" Vector__XXX
 SG_ DI_a249_learning_DIF m249 : 16|1@1+ (1,0) [0|1] "" Vector__XXX
 SG_ DI_a249_learning_DIR m249 : 17|1@1+ (1,0) [0|1] "" Vector__XXX
 SG_ DI_a250_tasRequest m250 : 16|1@1+ (1,0) [0|1] "" Vector__XXX
 SG_ DI_a250_tasMIA m250 : 17|1@1+ (1,0) [0|1] "" Vector__XXX

BO_ 871 DI_alertMatrix: 8 DI
 SG_ DI_matrixIndex M : 0|4@1+ (1,0) [0|15] "" Vector__XXX
 SG_ DI_a001_frunkSpeedLimitActive m0 : 4|1@1+ (1,0) [0|1] "" Vector__XXX
 SG_ DI_a002_parkButtonDuringStalkReq m0 : 5|1@1+ (1,0) [0|1] "" Vector__XXX
 SG_ DI_a003_suggestedGearOverride m0 : 6|1@1+ (1,0) [0|1] "" Vector__XXX
 SG_ DI_a004_smartShiftUnavailable m0 : 7|1@1+ (1,0) [0|1] "" Vector__XXX
 SG_ DI_a005_stalkPanicked m0 : 8|1@1+ (1,0) [0|1] "" Vector__XXX
 SG_ DI_a006_shifterUnavailable m0 : 9|1@1+ (1,0) [0|1] "" Vector__XXX
 SG_ DI_a007_secGearSelButtonStuck m0 : 10|1@1+ (1,0) [0|1] "" Vector__XXX
 SG_ DI_a010_unintendedReset m0 : 13|1@1+ (1,0) [0|1] "" Vector__XXX
 SG_ DI_a012_accel5VSupply m0 : 15|1@1+ (1,0) [0|1] "" Vector__XXX
 SG_ DI_a013_eccError m0 : 16|1@1+ (1,0) [0|1] "" Vector__XXX
 SG_ DI_a014_secGearSelActivated m0 : 17|1@1+ (1,0) [0|1] "" Vector__XXX
 SG_ DI_a015_immobilizer m0 : 18|1@1+ (1,0) [0|1] "" Vector__XXX
 SG_ DI_a016_parkRequestByPM m0 : 19|1@1+ (1,0) [0|1] "" Vector__XXX
 SG_ DI_a017_hwPedalMonitor m0 : 20|1@1+ (1,0) [0|1] "" Vector__XXX
 SG_ DI_a018_hwLVSupplyUV m0 : 21|1@1+ (1,0) [0|1] "" Vector__XXX
 SG_ DI_a019_hwAccelPedalPower m0 : 22|1@1+ (1,0) [0|1] "" Vector__XXX
 SG_ DI_a020_systemHvilNotClosed m0 : 23|1@1+ (1,0) [0|1] "" Vector__XXX
 SG_ DI_a021_packOvervoltage m0 : 24|1@1+ (1,0) [0|1] "" Vector__XXX
 SG_ DI_a022_hw5vSupplyUV m0 : 25|1@1+ (1,0) [0|1] "" Vector__XXX
 SG_ DI_a023_carNotParked m0 : 26|1@1+ (1,0) [0|1] "" Vector__XXX
 SG_ DI_a024_holdNForNeutral m0 : 27|1@1+ (1,0) [0|1] "" Vector__XXX
 SG_ DI_a025_regenBackfillUnavailable m0 : 28|1@1+ (1,0) [0|1] "" Vector__XXX
 SG_ DI_a026_parkPressedWithHighAPeda m0 : 29|1@1+ (1,0) [0|1] "" Vector__XXX
 SG_ DI_a027_steeringAngleOffsetServi m0 : 30|1@1+ (1,0) [0|1] "" Vector__XXX
 SG_ DI_a028_secondaryShifterMuted m0 : 31|1@1+ (1,0) [0|1] "" Vector__XXX
 SG_ DI_a031_closureAccelerationLimit m0 : 34|1@1+ (1,0) [0|1] "" Vector__XXX
 SG_ DI_a036_sysStandbyUnitLimitedWai m0 : 39|1@1+ (1,0) [0|1] "" Vector__XXX
 SG_ DI_a039_exceptionUndefinedInstru m0 : 42|1@1+ (1,0) [0|1] "" Vector__XXX
 SG_ DI_a040_difMIA m0 : 43|1@1+ (1,0) [0|1] "" Vector__XXX
 SG_ DI_a041_driverBrakeApplyStuck m0 : 44|1@1+ (1,0) [0|1] "" Vector__XXX
 SG_ DI_a042_pmfMIA m0 : 45|1@1+ (1,0) [0|1] "" Vector__XXX
 SG_ DI_a043_pmrMIA m0 : 46|1@1+ (1,0) [0|1] "" Vector__XXX
 SG_ DI_d047_interfacePowerSupplyIssu m0 : 50|1@1+ (1,0) [0|1] "" Vector__XXX
 SG_ DI_a048_ecuLogAvailable m0 : 51|1@1+ (1,0) [0|1] "" Vector__XXX
 SG_ DI_d049_invalidOdometerReading m0 : 52|1@1+ (1,0) [0|1] "" Vector__XXX
 SG_ DI_d050_interfaceUnitCommunicati m0 : 53|1@1+ (1,0) [0|1] "" Vector__XXX
 SG_ DI_a051_batteryOvercurrent m0 : 54|1@1+ (1,0) [0|1] "" Vector__XXX
 SG_ DI_a052_dirMIA m0 : 55|1@1+ (1,0) [0|1] "" Vector__XXX
 SG_ DI_a053_canDataBusC m0 : 56|1@1+ (1,0) [0|1] "" Vector__XXX
 SG_ DI_a054_canOverrunBusC m0 : 57|1@1+ (1,0) [0|1] "" Vector__XXX
 SG_ DI_a055_canHardwareBusC m0 : 58|1@1+ (1,0) [0|1] "" Vector__XXX
 SG_ DI_a056_canDataBusD m0 : 59|1@1+ (1,0) [0|1] "" Vector__XXX
 SG_ DI_a057_canOverrunBusD m0 : 60|1@1+ (1,0) [0|1] "" Vector__XXX
 SG_ DI_a058_canHardwareBusD m0 : 61|1@1+ (1,0) [0|1] "" Vector__XXX
 SG_ DI_a059_canDataBusE m0 : 62|1@1+ (1,0) [0|1] "" Vector__XXX
 SG_ DI_a060_canOverrunBusE m0 : 63|1@1+ (1,0) [0|1] "" Vector__XXX
 SG_ DI_a061_canHardwareBusE m1 : 4|1@1+ (1,0) [0|1] "" Vector__XXX
 SG_ DI_a062_systemLimpMode m1 : 5|1@1+ (1,0) [0|1] "" Vector__XXX
 SG_ DI_a063_systemGracefulPowerOff m1 : 6|1@1+ (1,0) [0|1] "" Vector__XXX
 SG_ DI_a064_pmsrmUnitMiaWithHvDown m1 : 7|1@1+ (1,0) [0|1] "" Vector__XXX
 SG_ DI_a065_canHardwareBusB m1 : 8|1@1+ (1,0) [0|1] "" Vector__XXX
 SG_ DI_a066_canDataBusB m1 : 9|1@1+ (1,0) [0|1] "" Vector__XXX
 SG_ DI_a067_canOverrunBusB m1 : 10|1@1+ (1,0) [0|1] "" Vector__XXX
 SG_ DI_a068_secondaryWheelSpeedIrrat m1 : 11|1@1+ (1,0) [0|1] "" Vector__XXX
 SG_ DI_a070_udsTransactionInitiated m1 : 13|1@1+ (1,0) [0|1] "" Vector__XXX
 SG_ DI_d072_accelPedalSensorIssue m1 : 15|1@1+ (1,0) [0|1] "" Vector__XXX
 SG_ DI_d073_accelPedalVoltSupplyIssu m1 : 16|1@1+ (1,0) [0|1] "" Vector__XXX
 SG_ DI_a074_unintendedResetAutoshift m1 : 17|1@1+ (1,0) [0|1] "" Vector__XXX
 SG_ DI_d075_incorrectImmobilizerKey m1 : 18|1@1+ (1,0) [0|1] "" Vector__XXX
 SG_ DI_a076_lvSupplyOV m1 : 19|1@1+ (1,0) [0|1] "" Vector__XXX
 SG_ DI_a077_lvSupplyUV m1 : 20|1@1+ (1,0) [0|1] "" Vector__XXX
 SG_ DI_a078_adcRefLow m1 : 21|1@1+ (1,0) [0|1] "" Vector__XXX
 SG_ DI_a079_adcRefHigh m1 : 22|1@1+ (1,0) [0|1] "" Vector__XXX
 SG_ DI_a080_accelSynch m1 : 23|1@1+ (1,0) [0|1] "" Vector__XXX
 SG_ DI_a081_accelTrack1 m1 : 24|1@1+ (1,0) [0|1] "" Vector__XXX
 SG_ DI_a082_accelTrack2 m1 : 25|1@1+ (1,0) [0|1] "" Vector__XXX
 SG_ DI_a083_brakePedalSensor m1 : 26|1@1+ (1,0) [0|1] "" Vector__XXX
 SG_ DI_a084_eccTestData0 m1 : 27|1@1+ (1,0) [0|1] "" Vector__XXX
 SG_ DI_a085_proximityInEnable m1 : 28|1@1+ (1,0) [0|1] "" Vector__XXX
 SG_ DI_a086_dpbMIA m1 : 29|1@1+ (1,0) [0|1] "" Vector__XXX
 SG_ DI_a087_gtwMIA m1 : 30|1@1+ (1,0) [0|1] "" Vector__XXX
 SG_ DI_a088_uiMIA m1 : 31|1@1+ (1,0) [0|1] "" Vector__XXX
 SG_ DI_a089_sccmMIA m1 : 32|1@1+ (1,0) [0|1] "" Vector__XXX
 SG_ DI_a090_pmMIA m1 : 33|1@1+ (1,0) [0|1] "" Vector__XXX
 SG_ DI_a091_espMIA m1 : 34|1@1+ (1,0) [0|1] "" Vector__XXX
 SG_ DI_a092_bmsMIA m1 : 35|1@1+ (1,0) [0|1] "" Vector__XXX
 SG_ DI_a093_canHardwareBusA m1 : 36|1@1+ (1,0) [0|1] "" Vector__XXX
 SG_ DI_a094_canDataBusA m1 : 37|1@1+ (1,0) [0|1] "" Vector__XXX
 SG_ DI_a095_canOverrunBusA m1 : 38|1@1+ (1,0) [0|1] "" Vector__XXX
 SG_ DI_a096_memoryError m1 : 39|1@1+ (1,0) [0|1] "" Vector__XXX
 SG_ DI_a097_eepromError m1 : 40|1@1+ (1,0) [0|1] "" Vector__XXX
 SG_ DI_a098_eepromManagerError m1 : 41|1@1+ (1,0) [0|1] "" Vector__XXX
 SG_ DI_a099_threadOverrun m1 : 42|1@1+ (1,0) [0|1] "" Vector__XXX
 SG_ DI_a100_nvramError m1 : 43|1@1+ (1,0) [0|1] "" Vector__XXX
 SG_ DI_a101_eccTestData1 m1 : 44|1@1+ (1,0) [0|1] "" Vector__XXX
 SG_ DI_a102_exceptionPrefetchAbort m1 : 45|1@1+ (1,0) [0|1] "" Vector__XXX
 SG_ DI_a103_bbMIA m1 : 46|1@1+ (1,0) [0|1] "" Vector__XXX
 SG_ DI_a104_proximityIrrational m1 : 47|1@1+ (1,0) [0|1] "" Vector__XXX
 SG_ DI_a105_cpMIA m1 : 48|1@1+ (1,0) [0|1] "" Vector__XXX
 SG_ DI_a106_idleTaskStarving m1 : 49|1@1+ (1,0) [0|1] "" Vector__XXX
 SG_ DI_a107_idbBrakeCircuitPressureO m1 : 50|1@1+ (1,0) [0|1] "" Vector__XXX
 SG_ DI_a108_appMIA m1 : 51|1@1+ (1,0) [0|1] "" Vector__XXX
 SG_ DI_a109_ahbWriteError m1 : 52|1@1+ (1,0) [0|1] "" Vector__XXX
 SG_ DI_a110_brakeMIA m1 : 53|1@1+ (1,0) [0|1] "" Vector__XXX
 SG_ DI_a111_idbMIA m1 : 54|1@1+ (1,0) [0|1] "" Vector__XXX
 SG_ DI_a112_accelTrack1Incons m1 : 55|1@1+ (1,0) [0|1] "" Vector__XXX
 SG_ DI_a113_lowBrakeMCPressure m1 : 56|1@1+ (1,0) [0|1] "" Vector__XXX
 SG_ DI_a114_exceptionDataAbort m1 : 57|1@1+ (1,0) [0|1] "" Vector__XXX
 SG_ DI_a115_exceptionDataAbort2 m1 : 58|1@1+ (1,0) [0|1] "" Vector__XXX
 SG_ DI_a116_motorRecovered m1 : 59|1@1+ (1,0) [0|1] "" Vector__XXX
 SG_ DI_a117_latentFaultCheckTripped m1 : 60|1@1+ (1,0) [0|1] "" Vector__XXX
 SG_ DI_a118_diImmobilizedForFactoryF m1 : 61|1@1+ (1,0) [0|1] "" Vector__XXX
 SG_ DI_a119_latentFaultCheckFailedOn m1 : 62|1@1+ (1,0) [0|1] "" Vector__XXX
 SG_ DI_a120_regenBlendingUnavailable m1 : 63|1@1+ (1,0) [0|1] "" Vector__XXX
 SG_ DI_a121_qualifiedBrakeEventMitig m2 : 4|1@1+ (1,0) [0|1] "" Vector__XXX
 SG_ DI_a122_highStackUsage m2 : 5|1@1+ (1,0) [0|1] "" Vector__XXX
 SG_ DI_a124_cruiseFault m2 : 7|1@1+ (1,0) [0|1] "" Vector__XXX
 SG_ DI_a125_noBatteryPower m2 : 8|1@1+ (1,0) [0|1] "" Vector__XXX
 SG_ DI_a129_epbNotApplied m2 : 12|1@1+ (1,0) [0|1] "" Vector__XXX
 SG_ DI_a130_aebFault m2 : 13|1@1+ (1,0) [0|1] "" Vector__XXX
 SG_ DI_a131_highSpeedWearLimit m2 : 14|1@1+ (1,0) [0|1] "" Vector__XXX
 SG_ DI_a133_vehicleHoldTimedOut m2 : 16|1@1+ (1,0) [0|1] "" Vector__XXX
 SG_ DI_a134_wheelSpeedIrrational m2 : 17|1@1+ (1,0) [0|1] "" Vector__XXX
 SG_ DI_a135_vehicleHoldFault m2 : 18|1@1+ (1,0) [0|1] "" Vector__XXX
 SG_ DI_a137_noCapableDriveUnits m2 : 20|1@1+ (1,0) [0|1] "" Vector__XXX
 SG_ DI_a138_frontUnitDisabled m2 : 21|1@1+ (1,0) [0|1] "" Vector__XXX
 SG_ DI_a139_rearUnitDisabled m2 : 22|1@1+ (1,0) [0|1] "" Vector__XXX
 SG_ DI_a140_ptcMIA m2 : 23|1@1+ (1,0) [0|1] "" Vector__XXX
 SG_ DI_a141_dasMIA m2 : 24|1@1+ (1,0) [0|1] "" Vector__XXX
 SG_ DI_a142_potholeDetected m2 : 25|1@1+ (1,0) [0|1] "" Vector__XXX
 SG_ DI_a143_mcuLimitActive m2 : 26|1@1+ (1,0) [0|1] "" Vector__XXX
 SG_ DI_a144_configMismatch m2 : 27|1@1+ (1,0) [0|1] "" Vector__XXX
 SG_ DI_a146_pbrkPanicEpbFault m2 : 29|1@1+ (1,0) [0|1] "" Vector__XXX
 SG_ DI_a154_vdcRearSteering m2 : 37|1@1+ (1,0) [0|1] "" Vector__XXX
 SG_ DI_a155_vcfrontMIA m2 : 38|1@1+ (1,0) [0|1] "" Vector__XXX
 SG_ DI_a157_rcmMIA m2 : 40|1@1+ (1,0) [0|1] "" Vector__XXX
 SG_ DI_a158_ibstMIA m2 : 41|1@1+ (1,0) [0|1] "" Vector__XXX
 SG_ DI_a159_cruiseSelfCheck m2 : 42|1@1+ (1,0) [0|1] "" Vector__XXX
 SG_ DI_a160_fastLearnComplete m2 : 43|1@1+ (1,0) [0|1] "" Vector__XXX
 SG_ DI_a161_epas3pMIA m2 : 44|1@1+ (1,0) [0|1] "" Vector__XXX
 SG_ DI_a162_shiftDenied m2 : 45|1@1+ (1,0) [0|1] "" Vector__XXX
 SG_ DI_a163_shiftMotorSpeed m2 : 46|1@1+ (1,0) [0|1] "" Vector__XXX
 SG_ DI_a164_brakeOverride m2 : 47|1@1+ (1,0) [0|1] "" Vector__XXX
 SG_ DI_a165_cruiseCancelled m2 : 48|1@1+ (1,0) [0|1] "" Vector__XXX
 SG_ DI_a166_driverLeft m2 : 49|1@1+ (1,0) [0|1] "" Vector__XXX
 SG_ DI_a167_keyNotAuthenticated m2 : 50|1@1+ (1,0) [0|1] "" Vector__XXX
 SG_ DI_a168_proximityDriveDenial m2 : 51|1@1+ (1,0) [0|1] "" Vector__XXX
 SG_ DI_a169_regenOffOverride m2 : 52|1@1+ (1,0) [0|1] "" Vector__XXX
 SG_ DI_a170_tireConfigUpdated m2 : 53|1@1+ (1,0) [0|1] "" Vector__XXX
 SG_ DI_a171_driveRailNotRequested m2 : 54|1@1+ (1,0) [0|1] "" Vector__XXX
 SG_ DI_a172_accelPressedInNP m2 : 55|1@1+ (1,0) [0|1] "" Vector__XXX
 SG_ DI_a173_bothPedalsPressed m2 : 56|1@1+ (1,0) [0|1] "" Vector__XXX
 SG_ DI_a174_notOkToStartDrive m2 : 57|1@1+ (1,0) [0|1] "" Vector__XXX
 SG_ DI_a175_crsNotAvailable m2 : 58|1@1+ (1,0) [0|1] "" Vector__XXX
 SG_ DI_a176_EBRreleased m2 : 59|1@1+ (1,0) [0|1] "" Vector__XXX
 SG_ DI_a177_tireFitmentChanged m2 : 60|1@1+ (1,0) [0|1] "" Vector__XXX
 SG_ DI_a178_steeringAngleOffsetFault m2 : 61|1@1+ (1,0) [0|1] "" Vector__XXX
 SG_ DI_a179_steeringAngleOffsetWarni m2 : 62|1@1+ (1,0) [0|1] "" Vector__XXX
 SG_ DI_a180_crsSeatbeltUnbuckled m2 : 63|1@1+ (1,0) [0|1] "" Vector__XXX
 SG_ DI_a181_rearMotorMode m3 : 4|1@1+ (1,0) [0|1] "" Vector__XXX
 SG_ DI_a182_frontMotorMode m3 : 5|1@1+ (1,0) [0|1] "" Vector__XXX
 SG_ DI_a183_holdReleaseRqrd m3 : 6|1@1+ (1,0) [0|1] "" Vector__XXX
 SG_ DI_a184_autoparkCanceled m3 : 7|1@1+ (1,0) [0|1] "" Vector__XXX
 SG_ DI_a185_autoparkAborted m3 : 8|1@1+ (1,0) [0|1] "" Vector__XXX
 SG_ DI_a186_brakeStand m3 : 9|1@1+ (1,0) [0|1] "" Vector__XXX
 SG_ DI_a187_pedalMisapplication m3 : 10|1@1+ (1,0) [0|1] "" Vector__XXX
 SG_ DI_a188_tireRotationRecommendedG m3 : 11|1@1+ (1,0) [0|1] "" Vector__XXX
 SG_ DI_a189_garageShiftWithPedal m3 : 12|1@1+ (1,0) [0|1] "" Vector__XXX
 SG_ DI_a190_tireRotationRecommended m3 : 13|1@1+ (1,0) [0|1] "" Vector__XXX
 SG_ DI_a191_brakeShiftReq m3 : 14|1@1+ (1,0) [0|1] "" Vector__XXX
 SG_ DI_a192_invalidOdometer m3 : 15|1@1+ (1,0) [0|1] "" Vector__XXX
 SG_ DI_a193_vdcBrakeTorqueFr m3 : 16|1@1+ (1,0) [0|1] "" Vector__XXX
 SG_ DI_a194_vdcBrakeTorqueRe m3 : 17|1@1+ (1,0) [0|1] "" Vector__XXX
 SG_ DI_a195_vdcEspSlipFr m3 : 18|1@1+ (1,0) [0|1] "" Vector__XXX
 SG_ DI_a196_vdcEspSlipRe m3 : 19|1@1+ (1,0) [0|1] "" Vector__XXX
 SG_ DI_a197_vdcEspWheelSaturations m3 : 20|1@1+ (1,0) [0|1] "" Vector__XXX
 SG_ DI_a198_vdcEspMCPressAndSteering m3 : 21|1@1+ (1,0) [0|1] "" Vector__XXX
 SG_ DI_a199_vdcFaulted m3 : 22|1@1+ (1,0) [0|1] "" Vector__XXX
 SG_ DI_a200_vdcModelBasedPlausibilit m3 : 23|1@1+ (1,0) [0|1] "" Vector__XXX
 SG_ DI_a201_decelTorqueLimited m3 : 24|1@1+ (1,0) [0|1] "" Vector__XXX
 SG_ DI_a202_excessHeatUnavailable m3 : 25|1@1+ (1,0) [0|1] "" Vector__XXX
 SG_ DI_a203_TCReducedByADD m3 : 26|1@1+ (1,0) [0|1] "" Vector__XXX
 SG_ DI_a204_vdcRcmLongitudinal m3 : 27|1@1+ (1,0) [0|1] "" Vector__XXX
 SG_ DI_a205_vdcRcmLateral m3 : 28|1@1+ (1,0) [0|1] "" Vector__XXX
 SG_ DI_a206_vdcRcmVertical m3 : 29|1@1+ (1,0) [0|1] "" Vector__XXX
 SG_ DI_a207_vdcPowertrainTorque_dif m3 : 30|1@1+ (1,0) [0|1] "" Vector__XXX
 SG_ DI_a208_vdcPowertrainTorque_dir m3 : 31|1@1+ (1,0) [0|1] "" Vector__XXX
 SG_ DI_a210_vdcOtherControllerStates m3 : 33|1@1+ (1,0) [0|1] "" Vector__XXX
 SG_ DI_a211_vdcMotorSpeed_dif m3 : 34|1@1+ (1,0) [0|1] "" Vector__XXX
 SG_ DI_a212_vdcWheelRotations m3 : 35|1@1+ (1,0) [0|1] "" Vector__XXX
 SG_ DI_a213_lowMuProbabilityChange m3 : 36|1@1+ (1,0) [0|1] "" Vector__XXX
 SG_ DI_a214_vdcWheelSpeedFr m3 : 37|1@1+ (1,0) [0|1] "" Vector__XXX
 SG_ DI_a215_vdcWheelSpeedRe m3 : 38|1@1+ (1,0) [0|1] "" Vector__XXX
 SG_ DI_a216_vdcMBPAlmostTripped m3 : 39|1@1+ (1,0) [0|1] "" Vector__XXX
 SG_ DI_a217_vdcOutputIrrational m3 : 40|1@1+ (1,0) [0|1] "" Vector__XXX
 SG_ DI_a218_vdcOSPreControlActive m3 : 41|1@1+ (1,0) [0|1] "" Vector__XXX
 SG_ DI_a219_vdcOversteerdMzActive m3 : 42|1@1+ (1,0) [0|1] "" Vector__XXX
 SG_ DI_a220_vdcUndersteerDecelActive m3 : 43|1@1+ (1,0) [0|1] "" Vector__XXX
 SG_ DI_a221_vdcUndersteerdMzActive m3 : 44|1@1+ (1,0) [0|1] "" Vector__XXX
 SG_ DI_a222_vdcDisabled m3 : 45|1@1+ (1,0) [0|1] "" Vector__XXX
 SG_ DI_a223_tractionControlDisabled m3 : 46|1@1+ (1,0) [0|1] "" Vector__XXX
 SG_ DI_a224_brakeOverTemp m3 : 47|1@1+ (1,0) [0|1] "" Vector__XXX
 SG_ DI_a225_vyEstimatorDegradedDebug m3 : 48|1@1+ (1,0) [0|1] "" Vector__XXX
 SG_ DI_a226_sysStartConditionNotMet m3 : 49|1@1+ (1,0) [0|1] "" Vector__XXX
 SG_ DI_a227_contactorsNotClosed m3 : 50|1@1+ (1,0) [0|1] "" Vector__XXX
 SG_ DI_a228_brakeTempEstUnavailable m3 : 51|1@1+ (1,0) [0|1] "" Vector__XXX
 SG_ DI_a230_cmpMIA m3 : 53|1@1+ (1,0) [0|1] "" Vector__XXX
 SG_ DI_a231_softSystemLimpMode m3 : 54|1@1+ (1,0) [0|1] "" Vector__XXX
 SG_ DI_a232_velocityEstimatorDegrade m3 : 55|1@1+ (1,0) [0|1] "" Vector__XXX
 SG_ DI_a233_frontWheelImpactDetected m3 : 56|1@1+ (1,0) [0|1] "" Vector__XXX
 SG_ DI_a235_trackModeActive m3 : 58|1@1+ (1,0) [0|1] "" Vector__XXX
 SG_ DI_a236_tasMIA m3 : 59|1@1+ (1,0) [0|1] "" Vector__XXX
 SG_ DI_a237_undersideAbuse m3 : 60|1@1+ (1,0) [0|1] "" Vector__XXX
 SG_ DI_a238_secondaryCollisionMitiga m3 : 61|1@1+ (1,0) [0|1] "" Vector__XXX
 SG_ DI_a239_neutralRequestByPM m3 : 62|1@1+ (1,0) [0|1] "" Vector__XXX
 SG_ DI_a240_torqueSplitStuck m3 : 63|1@1+ (1,0) [0|1] "" Vector__XXX
 SG_ DI_a241_vdcMotorSpeed_dir m4 : 4|1@1+ (1,0) [0|1] "" Vector__XXX
 SG_ DI_a242_vdcTrailerSwayDetected m4 : 5|1@1+ (1,0) [0|1] "" Vector__XXX
 SG_ DI_a243_rcuMIA m4 : 6|1@1+ (1,0) [0|1] "" Vector__XXX
 SG_ DI_a244_vseRLSMassMismatch m4 : 7|1@1+ (1,0) [0|1] "" Vector__XXX
 SG_ DI_a245_opdReducedWithoutEbr m4 : 8|1@1+ (1,0) [0|1] "" Vector__XXX
 SG_ DI_a246_opdUnavailable m4 : 9|1@1+ (1,0) [0|1] "" Vector__XXX
 SG_ DI_a248_vdcPreControlHighDynamic m4 : 11|1@1+ (1,0) [0|1] "" Vector__XXX
 SG_ DI_a249_spinDownLearningInProgre m4 : 12|1@1+ (1,0) [0|1] "" Vector__XXX
 SG_ DI_a250_tasSpeedLimitActive m4 : 13|1@1+ (1,0) [0|1] "" Vector__XXX
 SG_ DI_a251_diPowerOnStateMismatch m4 : 14|1@1+ (1,0) [0|1] "" Vector__XXX
 SG_ DI_a253_accelSynchWarn m4 : 16|1@1+ (1,0) [0|1] "" Vector__XXX
 SG_ DI_a254_vehicleStuckDetected m4 : 17|1@1+ (1,0) [0|1] "" Vector__XXX
 SG_ DI_a255_manualRecoveryMode m4 : 18|1@1+ (1,0) [0|1] "" Vector__XXX

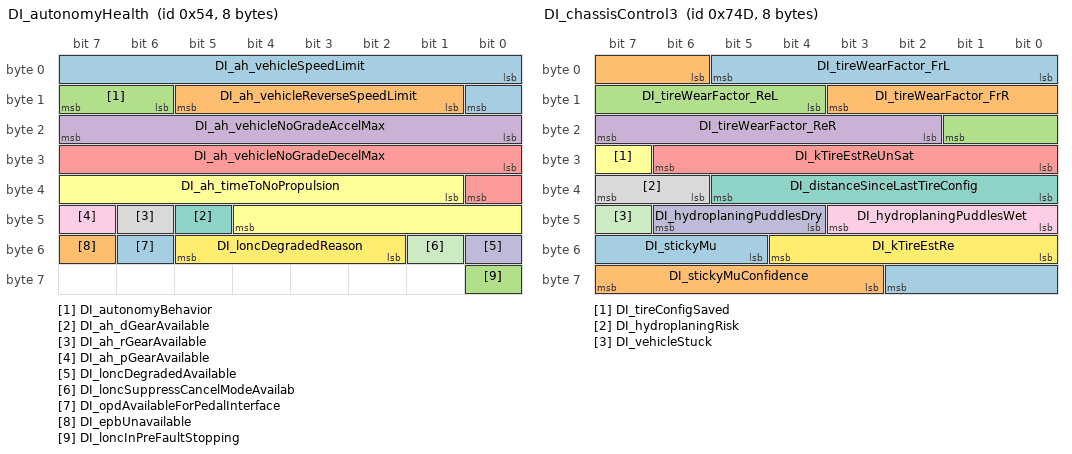
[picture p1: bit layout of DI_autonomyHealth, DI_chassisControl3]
BO_ 84 DI_autonomyHealth: 8 DI
 SG_ DI_ah_vehicleSpeedLimit : 0|9@1+ (1,0) [0|300] "kph" Vector__XXX
 SG_ DI_ah_vehicleReverseSpeedLimit : 9|5@1+ (1,0) [0|31] "kph" Vector__XXX
 SG_ DI_autonomyBehavior : 14|2@1+ (1,0) [0|3] "" Vector__XXX
 SG_ DI_ah_vehicleNoGradeAccelMax : 16|8@1+ (0.04,0) [0|10] "m/s^2" Vector__XXX
 SG_ DI_ah_vehicleNoGradeDecelMax : 24|9@1+ (0.04,0) [0|15] "m/s^2" Vector__XXX
 SG_ DI_ah_timeToNoPropulsion : 33|12@1+ (1,0) [0|4094] "s" Vector__XXX
 SG_ DI_ah_dGearAvailable : 45|1@1+ (1,0) [0|1] "" Vector__XXX
 SG_ DI_ah_rGearAvailable : 46|1@1+ (1,0) [0|1] "" Vector__XXX
 SG_ DI_ah_pGearAvailable : 47|1@1+ (1,0) [0|1] "" Vector__XXX
 SG_ DI_loncDegradedAvailable : 48|1@1+ (1,0) [0|1] "" Vector__XXX
 SG_ DI_loncSuppressCancelModeAvailab : 49|1@1+ (1,0) [0|1] "" Vector__XXX
 SG_ DI_loncDegradedReason : 50|4@1+ (1,0) [0|15] "" Vector__XXX
 SG_ DI_opdAvailableForPedalInterface : 54|1@1+ (1,0) [0|1] "" Vector__XXX
 SG_ DI_epbUnavailable : 55|1@1+ (1,0) [0|1] "" Vector__XXX
 SG_ DI_loncInPreFaultStopping : 56|1@1+ (1,0) [0|1] "" Vector__XXX

BO_ 328 DI_chassisControl: 8 DI
 SG_ DI_chassisControlChecksum : 0|8@1+ (1,0) [0|255] "" Vector__XXX
 SG_ DI_chassisControlCounter : 8|4@1+ (1,0) [0|15] "" Vector__XXX
 SG_ DI_imuOffsetLearnRequest : 12|2@1+ (1,0) [0|3] "" Vector__XXX
 SG_ DI_brakeCommandType : 14|1@1+ (1,0) [0|1] "" Vector__XXX
 SG_ DI_brakeTorqueRequestActive : 15|1@1+ (1,0) [0|1] "" Vector__XXX
 SG_ DI_brakeTorqueCommand : 16|13@1+ (3,0) [0|24573] "Nm" Vector__XXX
 SG_ DI_ptcStateGlobal : 29|2@1+ (1,0) [0|3] "" Vector__XXX
 SG_ DI_ptcActive : 31|1@1+ (1,0) [0|1] "" Vector__XXX
 SG_ DI_vdcState : 32|2@1+ (1,0) [0|3] "" Vector__XXX
 SG_ DI_isAnyVdcControlActive : 34|2@1+ (1,0) [0|3] "" Vector__XXX
 SG_ DI_vdcMode : 36|2@1+ (1,0) [0|3] "" Vector__XXX
 SG_ DI_pedalAssistCurveSelect : 38|4@1+ (1,0) [0|15] "" Vector__XXX
 SG_ DI_isAnyTcActive : 42|1@1+ (1,0) [0|1] "" Vector__XXX
 SG_ DI_VehicleMuConfidence : 43|6@1+ (0.02,0) [0|1.26] "-" Vector__XXX
 SG_ DI_VehicleMu : 49|6@1+ (0.024,0) [0|1.512] "-" Vector__XXX
 SG_ DI_trailerSwayIndex : 55|5@1+ (0.035,0) [0|1] "-" Vector__XXX
 SG_ DI_vdcControlActive : 60|3@1+ (1,0) [0|7] "" Vector__XXX
 SG_ DI_treadDepthAlertSet : 63|1@1+ (1,0) [0|1] "" Vector__XXX

BO_ 1861 DI_chassisControl2: 8 DI
 SG_ DI_gradeAngle : 0|6@1- (0.01,0) [-0.3125|0.31] "rad" Vector__XXX
 SG_ DI_bankAngle : 6|6@1- (0.01,0) [-0.3125|0.31] "rad" Vector__XXX
 SG_ DI_chassisControlVideoRequest : 12|4@1+ (1,0) [0|15] "" Vector__XXX
 SG_ DI_eepDeliveryBitStatus : 16|1@1+ (1,0) [0|1] "" Vector__XXX
 SG_ DI_tireUtilizationRatioFrL : 17|5@1+ (0.0625,0) [0|1.9375] "-" Vector__XXX
 SG_ DI_tireUtilizationRatioFrR : 22|5@1+ (0.0625,0) [0|1.9375] "-" Vector__XXX
 SG_ DI_tireUtilizationRatioReL : 27|5@1+ (0.0625,0) [0|1.9375] "-" Vector__XXX
 SG_ DI_tireUtilizationRatioReR : 32|5@1+ (0.0625,0) [0|1.9375] "-" Vector__XXX
 SG_ DI_counterSteerTarget : 37|2@1+ (1,0) [0|3] "" Vector__XXX
 SG_ DI_splitMuProbability : 39|2@1+ (0.334,0) [0|1] "-" Vector__XXX
 SG_ DI_mzError : 41|2@1+ (1667,0) [0|5000] "Nm" Vector__XXX
 SG_ DI_slipDifferenceFrontRear : 43|3@1- (0.133,0) [-0.52|0.399] "rad" Vector__XXX
 SG_ DI_highFreqYawRate : 46|2@1+ (0.334,0) [0|1] "-" Vector__XXX
 SG_ DI_turnDirection : 48|1@1+ (1,0) [0|1] "" Vector__XXX
 SG_ DI_absolutePreControlRequest : 49|2@1+ (5000,0) [0|15000] "Nm" Vector__XXX
 SG_ DI_oppositeBuildDirFrontAxle : 51|1@1+ (1,0) [0|1] "" Vector__XXX
 SG_ DI_oppositeBuildDirRearAxle : 52|1@1+ (1,0) [0|1] "" Vector__XXX
 SG_ DI_saturatedEffectiveness : 53|1@1+ (1,0) [0|1] "" Vector__XXX
 SG_ DI_driverPanicIndex : 54|2@1+ (0.334,0) [0|1] "-" Vector__XXX
 SG_ DI_learnDownMu : 56|2@1+ (0.334,0) [0|1] "mu" Vector__XXX
 SG_ DI_preControlOpposingTurnDir : 58|1@1+ (1,0) [0|1] "" Vector__XXX
 SG_ DI_driverFxError : 59|2@1+ (1000,0) [0|3000] "N" Vector__XXX
 SG_ DI_targetSaturation : 61|3@1+ (0.572,0) [0|4] "G" Vector__XXX

BO_ 1869 DI_chassisControl3: 8 DI
 SG_ DI_tireWearFactor_FrL : 0|6@1+ (0.00125,0.96) [0.96|1.03875] "ratio" Vector__XXX
 SG_ DI_tireWearFactor_FrR : 6|6@1+ (0.00125,0.96) [0.96|1.03875] "ratio" Vector__XXX
 SG_ DI_tireWearFactor_ReL : 12|6@1+ (0.00125,0.96) [0.96|1.03875] "ratio" Vector__XXX
 SG_ DI_tireWearFactor_ReR : 18|6@1+ (0.00125,0.96) [0.96|1.03875] "ratio" Vector__XXX
 SG_ DI_kTireEstReUnSat : 24|7@1+ (0.001,0.008) [0.008|0.075] "-" Vector__XXX
 SG_ DI_tireConfigSaved : 31|1@1+ (1,0) [0|1] "" Vector__XXX
 SG_ DI_distanceSinceLastTireConfig : 32|6@1+ (500,0) [0|31000] "km" Vector__XXX
 SG_ DI_hydroplaningRisk : 38|2@1+ (0.333333343267,0) [0|1] "-" Vector__XXX
 SG_ DI_hydroplaningPuddlesWet : 40|4@1+ (1,0) [0|15] "-" Vector__XXX
 SG_ DI_hydroplaningPuddlesDry : 44|3@1+ (1,0) [0|7] "-" Vector__XXX
 SG_ DI_vehicleStuck : 47|1@1+ (1,0) [0|1] "" Vector__XXX
 SG_ DI_kTireEstRe : 48|5@1+ (0.001,0.03) [0.03|0.06] "-" Vector__XXX
 SG_ DI_stickyMu : 53|6@1+ (0.025,0) [0|1.575] "-" Vector__XXX
 SG_ DI_stickyMuConfidence : 59|5@1+ (0.1,0) [0|3] "probability" Vector__XXX

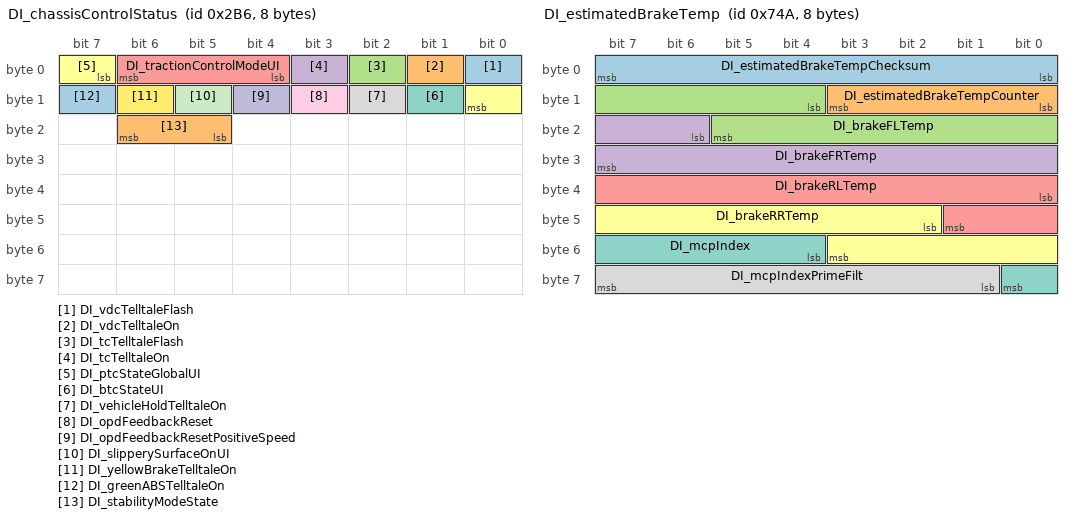
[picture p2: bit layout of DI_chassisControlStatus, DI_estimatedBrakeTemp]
BO_ 694 DI_chassisControlStatus: 8 DI
 SG_ DI_vdcTelltaleFlash : 0|1@1+ (1,0) [0|1] "" Vector__XXX
 SG_ DI_vdcTelltaleOn : 1|1@1+ (1,0) [0|1] "" Vector__XXX
 SG_ DI_tcTelltaleFlash : 2|1@1+ (1,0) [0|1] "" Vector__XXX
 SG_ DI_tcTelltaleOn : 3|1@1+ (1,0) [0|1] "" Vector__XXX
 SG_ DI_tractionControlModeUI : 4|3@1+ (1,0) [0|7] "" Vector__XXX
 SG_ DI_ptcStateGlobalUI : 7|2@1+ (1,0) [0|3] "" Vector__XXX
 SG_ DI_btcStateUI : 9|1@1+ (1,0) [0|1] "" Vector__XXX
 SG_ DI_vehicleHoldTelltaleOn : 10|1@1+ (1,0) [0|1] "" Vector__XXX
 SG_ DI_opdFeedbackReset : 11|1@1+ (1,0) [0|1] "" Vector__XXX
 SG_ DI_opdFeedbackResetPositiveSpeed : 12|1@1+ (1,0) [0|1] "" Vector__XXX
 SG_ DI_slipperySurfaceOnUI : 13|1@1+ (1,0) [0|1] "" Vector__XXX
 SG_ DI_yellowBrakeTelltaleOn : 14|1@1+ (1,0) [0|1] "" Vector__XXX
 SG_ DI_greenABSTelltaleOn : 15|1@1+ (1,0) [0|1] "" Vector__XXX
 SG_ DI_stabilityModeState : 21|2@1+ (1,0) [0|3] "" Vector__XXX

BO_ 2007 DI_debug: 8 DI
 SG_ DI_debugSelector M : 0|8@1+ (1,0) [0|255] "" Vector__XXX
 SG_ DI_regenBackfillCmd m39 : 8|13@1+ (2,0) [0|16382] "Nm" Vector__XXX
 SG_ DI_regenBackfillUnavailableReaso m39 : 21|5@1+ (1,0) [0|31] "" Vector__XXX
 SG_ DI_regenBackfillAbsSatState m39 : 26|2@1+ (1,0) [0|3] "" Vector__XXX
 SG_ DI_sysHeatPowerOptimal m50 : 8|8@1+ (0.08,0) [0|20] "kW" Vector__XXX
 SG_ DI_sysPostPedalMinTorque m53 : 8|15@1+ (0.5,-13000) [-13000|0] "Nm" Vector__XXX
 SG_ DI_sysPostPedalMaxTorque m53 : 24|15@1+ (0.5,0) [0|13000] "Nm" Vector__XXX
 SG_ DI_systemTorqueCommand m53 : 40|16@1- (0.5,0) [-13000|13000] "Nm" Vector__XXX

BO_ 1866 DI_estimatedBrakeTemp: 8 DI
 SG_ DI_estimatedBrakeTempChecksum : 0|8@1+ (1,0) [0|255] "" Vector__XXX
 SG_ DI_estimatedBrakeTempCounter : 8|4@1+ (1,0) [0|15] "" Vector__XXX
 SG_ DI_brakeFLTemp : 12|10@1+ (1,-40) [-40|982] "DegC" Vector__XXX
 SG_ DI_brakeFRTemp : 22|10@1+ (1,-40) [-40|982] "DegC" Vector__XXX
 SG_ DI_brakeRLTemp : 32|10@1+ (1,-40) [-40|982] "DegC" Vector__XXX
 SG_ DI_brakeRRTemp : 42|10@1+ (1,-40) [-40|982] "DegC" Vector__XXX
 SG_ DI_mcpIndex : 52|5@1- (0.05,0.75) [-0.05|1.5] "ratio" Vector__XXX
 SG_ DI_mcpIndexPrimeFilt : 57|7@1- (0.015,0.9) [-0.05|1.84] "ratio" Vector__XXX

BO_ 1623 DI_info: 8 DI
 SG_ DI_infoIndex M : 0|8@1+ (1,0) [0|255] "" Vector__XXX
 SG_ DI_buildType m10 : 8|3@1+ (1,0) [0|7] "" Vector__XXX
 SG_ DI_buildConfigurationId m10 : 16|16@1+ (1,0) [0|65535] "" Vector__XXX
 SG_ DI_hardwareId m10 : 32|8@1+ (1,0) [0|252] "" Vector__XXX
 SG_ DI_componentId m10 : 48|16@1+ (1,0) [0|65535] "" Vector__XXX
 SG_ DI_pcbaId m11 : 16|8@1+ (1,0) [0|255] "" Vector__XXX
 SG_ DI_assemblyId m11 : 24|8@1+ (1,0) [0|255] "" Vector__XXX
 SG_ DI_usageId m11 : 32|16@1+ (1,0) [0|65535] "" Vector__XXX
 SG_ DI_subUsageId m11 : 48|16@1+ (1,0) [0|65535] "" Vector__XXX
 SG_ DI_applicationCrc m13 : 32|32@1+ (1,0) [0|4294967295] "" Vector__XXX
 SG_ DI_appGitHash m17 : 8|56@1+ (1,0) [0|7.20575940379e+16] "" Vector__XXX
 SG_ DI_bootGitHash m18 : 8|56@1+ (1,0) [0|7.20575940379e+16] "" Vector__XXX

BO_ 646 DI_locStatus: 8 DI
 SG_ DI_locStatusChecksum : 0|8@1+ (1,0) [0|255] "" Vector__XXX
 SG_ DI_locStatusCounter : 8|4@1+ (1,0) [0|15] "" Vector__XXX
 SG_ DI_cruiseState : 12|3@1+ (1,0) [0|7] "" Vector__XXX
 SG_ DI_cruiseSetSpeed : 15|9@1+ (0.5,0) [0|255.5] "speed" Vector__XXX
 SG_ DI_cruiseSetSpeedUnits : 24|1@1+ (1,0) [0|1] "" Vector__XXX
 SG_ DI_autoparkState : 25|4@1+ (1,0) [0|15] "" Vector__XXX
 SG_ DI_parkBrakeState : 29|4@1+ (1,0) [0|15] "" Vector__XXX
 SG_ DI_aebState : 33|3@1+ (1,0) [0|7] "" Vector__XXX
 SG_ DI_loncDeactivationReason : 36|2@1+ (1,0) [0|3] "" Vector__XXX
 SG_ DI_vehicleHoldState : 38|3@1+ (1,0) [0|7] "" Vector__XXX
 SG_ DI_summonInPanic : 41|1@1+ (1,0) [0|1] "" Vector__XXX
 SG_ DI_onePedalDrivingState : 42|4@1+ (1,0) [0|15] "" Vector__XXX
 SG_ DI_brakeStandActive : 46|1@1+ (1,0) [0|1] "" Vector__XXX
 SG_ DI_regenBackfillState : 47|2@1+ (1,0) [0|3] "" Vector__XXX
 SG_ DI_cruiseNotAvailableReason : 49|6@1+ (1,0) [0|63] "" Vector__XXX
 SG_ DI_cruiseFaultReason : 55|5@1+ (1,0) [0|31] "" Vector__XXX
 SG_ DI_cruiseCancelReason : 60|4@1+ (1,0) [0|15] "" Vector__XXX

BO_ 1270 DI_locStatus2: 8 DI
 SG_ DI_locStatus2Checksum : 0|8@1+ (1,0) [0|255] "" Vector__XXX
 SG_ DI_locStatus2Counter : 8|4@1+ (1,0) [0|15] "" Vector__XXX
 SG_ DI_doublePedalState : 12|4@1+ (1,0) [0|15] "" Vector__XXX
 SG_ DI_autopilotRequest : 16|1@1+ (1,0) [0|1] "" Vector__XXX
 SG_ DI_rollPreventionState : 17|3@1+ (1,0) [0|7] "" Vector__XXX
 SG_ DI_locIntegratorSaturated : 20|1@1+ (1,0) [0|1] "" Vector__XXX
 SG_ DI_temporaryOpdActiveAfterLoncCa : 21|1@1+ (1,0) [0|1] "" Vector__XXX
 SG_ DI_reapplyOnParkRequest : 22|1@1+ (1,0) [0|1] "" Vector__XXX
 SG_ DI_veDegradedAtStandstill : 23|1@1+ (1,0) [0|1] "" Vector__XXX
 SG_ DI_brakeCpScale : 25|11@1+ (0.005,0) [0|10] "N/N" Vector__XXX
 SG_ DI_rollbackDistance : 36|8@1+ (0.005,0) [0|1.275] "m" Vector__XXX
 SG_ DI_lowMuProbabilityConfidence : 44|4@1+ (0.06666667,0) [0|1] "-" Vector__XXX
 SG_ DI_pedalAssistCurveSelectForSX : 48|4@1+ (1,0) [0|15] "" Vector__XXX
 SG_ DI_longitudinalControlStack : 52|3@1+ (1,0) [0|7] "" Vector__XXX
 SG_ DI_useDasFallbackBrakeCommands : 55|1@1+ (1,0) [0|1] "" Vector__XXX
 SG_ DI_regenBlendingState : 56|2@1+ (1,0) [0|3] "" Vector__XXX
 SG_ DI_executeBatLocStatus2 : 58|1@1+ (1,0) [0|1] "" Vector__XXX

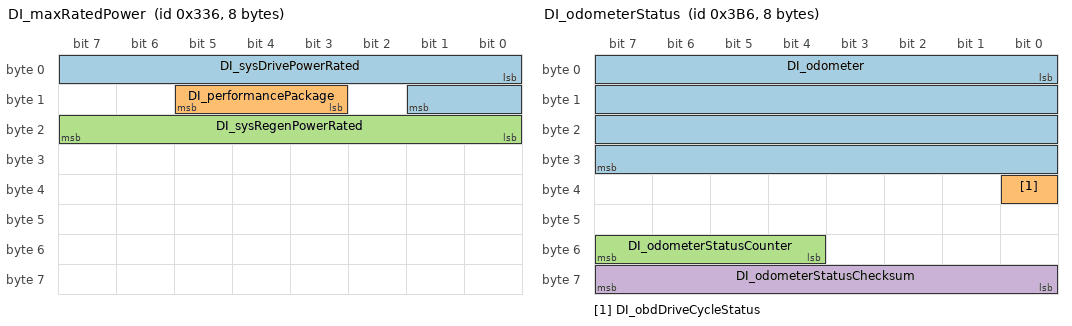
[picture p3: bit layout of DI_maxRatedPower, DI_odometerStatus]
BO_ 822 DI_maxRatedPower: 8 DI
 SG_ DI_sysDrivePowerRated : 0|10@1+ (1,0) [0|1023] "kW" Vector__XXX
 SG_ DI_performancePackage : 11|3@1+ (1,0) [0|7] "" Vector__XXX
 SG_ DI_sysRegenPowerRated : 16|8@1+ (1,-100) [-100|0] "kW" Vector__XXX

BO_ 950 DI_odometerStatus: 8 DI
 SG_ DI_odometer : 0|32@1+ (0.001,0) [0|4294967.294] "km" Vector__XXX
 SG_ DI_obdDriveCycleStatus : 32|1@1+ (1,0) [0|1] "" Vector__XXX
 SG_ DI_odometerStatusCounter : 52|4@1+ (1,0) [0|15] "" Vector__XXX
 SG_ DI_odometerStatusChecksum : 56|8@1+ (1,0) [0|255] "" Vector__XXX

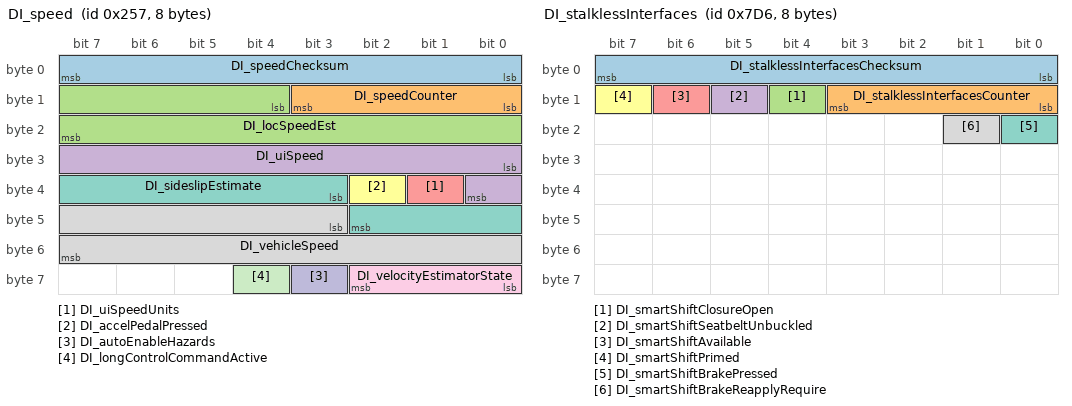
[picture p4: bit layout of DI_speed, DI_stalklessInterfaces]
BO_ 599 DI_speed: 8 DI
 SG_ DI_speedChecksum : 0|8@1+ (1,0) [0|255] "" Vector__XXX
 SG_ DI_speedCounter : 8|4@1+ (1,0) [0|15] "" Vector__XXX
 SG_ DI_locSpeedEst : 12|12@1+ (0.08,-40) [-40|285] "kph" Vector__XXX
 SG_ DI_uiSpeed : 24|9@1+ (1,0) [0|510] "" Vector__XXX
 SG_ DI_uiSpeedUnits : 33|1@1+ (1,0) [0|1] "" Vector__XXX
 SG_ DI_accelPedalPressed : 34|1@1+ (1,0) [0|1] "" Vector__XXX
 SG_ DI_sideslipEstimate : 35|8@1- (0.0025,0) [-0.32|0.3175] "rad" Vector__XXX
 SG_ DI_vehicleSpeed : 43|13@1+ (0.08,-40) [-40|480] "kph" Vector__XXX
 SG_ DI_velocityEstimatorState : 56|3@1+ (1,0) [0|7] "" Vector__XXX
 SG_ DI_autoEnableHazards : 59|1@1+ (1,0) [0|1] "" Vector__XXX
 SG_ DI_longControlCommandActive : 60|1@1+ (1,0) [0|1] "" Vector__XXX

BO_ 2006 DI_stalklessInterfaces: 8 DI
 SG_ DI_stalklessInterfacesChecksum : 0|8@1+ (1,0) [0|255] "" Vector__XXX
 SG_ DI_stalklessInterfacesCounter : 8|4@1+ (1,0) [0|15] "" Vector__XXX
 SG_ DI_smartShiftClosureOpen : 12|1@1+ (1,0) [0|1] "" Vector__XXX
 SG_ DI_smartShiftSeatbeltUnbuckled : 13|1@1+ (1,0) [0|1] "" Vector__XXX
 SG_ DI_smartShiftAvailable : 14|1@1+ (1,0) [0|1] "" Vector__XXX
 SG_ DI_smartShiftPrimed : 15|1@1+ (1,0) [0|1] "" Vector__XXX
 SG_ DI_smartShiftBrakePressed : 16|1@1+ (1,0) [0|1] "" Vector__XXX
 SG_ DI_smartShiftBrakeReapplyRequire : 17|1@1+ (1,0) [0|1] "" Vector__XXX

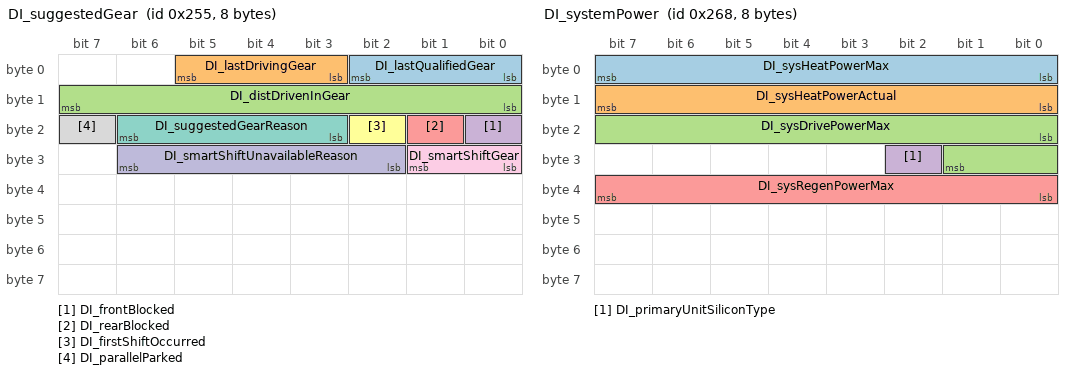
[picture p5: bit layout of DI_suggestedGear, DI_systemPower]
BO_ 597 DI_suggestedGear: 8 DI
 SG_ DI_lastQualifiedGear : 0|3@1+ (1,0) [0|7] "" Vector__XXX
 SG_ DI_lastDrivingGear : 3|3@1+ (1,0) [0|7] "" Vector__XXX
 SG_ DI_distDrivenInGear : 8|8@1+ (0.0235294122249,0) [0|6] "m" Vector__XXX
 SG_ DI_frontBlocked : 16|1@1+ (1,0) [0|1] "" Vector__XXX
 SG_ DI_rearBlocked : 17|1@1+ (1,0) [0|1] "" Vector__XXX
 SG_ DI_firstShiftOccurred : 18|1@1+ (1,0) [0|1] "" Vector__XXX
 SG_ DI_suggestedGearReason : 19|4@1+ (1,0) [0|15] "" Vector__XXX
 SG_ DI_parallelParked : 23|1@1+ (1,0) [0|1] "" Vector__XXX
 SG_ DI_smartShiftGear : 24|2@1+ (1,0) [0|3] "" Vector__XXX
 SG_ DI_smartShiftUnavailableReason : 26|5@1+ (1,0) [0|31] "" Vector__XXX

BO_ 296 DI_systemLimits: 8 DI
 SG_ DI_limitRegenPower : 0|1@1+ (1,0) [0|1] "" Vector__XXX
 SG_ DI_limitIBat : 1|1@1+ (1,0) [0|1] "" Vector__XXX
 SG_ DI_limitVBatLow : 2|1@1+ (1,0) [0|1] "" Vector__XXX
 SG_ DI_limitVBatHigh : 3|1@1+ (1,0) [0|1] "" Vector__XXX
 SG_ DI_limitObstacleDetection : 4|1@1+ (1,0) [0|1] "" Vector__XXX
 SG_ DI_limitSystemLimp : 5|1@1+ (1,0) [0|1] "" Vector__XXX
 SG_ DI_limitSystemGPO : 6|1@1+ (1,0) [0|1] "" Vector__XXX
 SG_ DI_limitShift : 7|1@1+ (1,0) [0|1] "" Vector__XXX
 SG_ DI_limitDriveTorque : 8|1@1+ (1,0) [0|1] "" Vector__XXX
 SG_ DI_limitRegenTorque : 9|1@1+ (1,0) [0|1] "" Vector__XXX
 SG_ DI_limitVehicleSpeed : 10|1@1+ (1,0) [0|1] "" Vector__XXX
 SG_ DI_limitBmsMiaFreeze : 11|1@1+ (1,0) [0|1] "" Vector__XXX
 SG_ DI_limitSystemSpinDownLearning : 12|1@1+ (1,0) [0|1] "" Vector__XXX
 SG_ DI_limitCdp : 13|1@1+ (1,0) [0|1] "" Vector__XXX
 SG_ DI_vehicleSpeedLimitType : 14|2@1+ (1,0) [0|3] "" Vector__XXX
 SG_ DI_vehicleSpeedLimit : 16|9@1+ (1,0) [0|510] "kph" Vector__XXX
 SG_ DI_vehicleSpeedLimitReason : 25|5@1+ (1,0) [0|31] "" Vector__XXX
 SG_ DI_proximity : 30|1@1+ (1,0) [0|1] "" Vector__XXX
 SG_ DI_limitClosureNotClosed : 31|1@1+ (1,0) [0|1] "" Vector__XXX
 SG_ DI_undersideAbuse : 32|1@1+ (1,0) [0|1] "" Vector__XXX
 SG_ DI_immobilizerAuthLevel : 33|2@1+ (1,0) [0|3] "" Vector__XXX
 SG_ DI_manualRecoveryDistanceRemaini : 40|7@1+ (5,0) [0|500] "m" Vector__XXX
 SG_ DI_restrictedDrivingMode : 47|1@1+ (1,0) [0|1] "" Vector__XXX

BO_ 616 DI_systemPower: 8 DI
 SG_ DI_sysHeatPowerMax : 0|8@1+ (0.08,0) [0|20] "kW" Vector__XXX
 SG_ DI_sysHeatPowerActual : 8|8@1+ (0.08,0) [0|20] "kW" Vector__XXX
 SG_ DI_sysDrivePowerMax : 16|10@1+ (1,0) [0|1023] "kW" Vector__XXX
 SG_ DI_primaryUnitSiliconType : 26|1@1+ (1,0) [0|1] "" Vector__XXX
 SG_ DI_sysRegenPowerMax : 32|8@1+ (1,-100) [-100|0] "kW" Vector__XXX

BO_ 280 DI_systemStatus: 8 DI
 SG_ DI_systemStatusChecksum : 0|8@1+ (1,0) [0|255] "" Vector__XXX
 SG_ DI_systemStatusCounter : 8|4@1+ (1,0) [0|15] "" Vector__XXX
 SG_ DI_secondaryGearControlStatus : 12|1@1+ (1,0) [0|1] "" Vector__XXX
 SG_ DI_immobilizerState : 13|3@1+ (1,0) [0|7] "" Vector__XXX
 SG_ DI_systemState : 16|3@1+ (1,0) [0|7] "" Vector__XXX
 SG_ DI_brakePedalState : 19|2@1+ (1,0) [0|3] "" Vector__XXX
 SG_ DI_gear : 21|3@1+ (1,0) [0|7] "" Vector__XXX
 SG_ DI_driveBlocked : 24|3@1+ (1,0) [0|7] "" Vector__XXX
 SG_ DI_hvilSystemStatus : 27|2@1+ (1,0) [0|3] "" Vector__XXX
 SG_ DI_driveModeState : 29|1@1+ (1,0) [0|1] "" Vector__XXX
 SG_ DI_shiftRequestType : 30|2@1+ (1,0) [0|3] "" Vector__XXX
 SG_ DI_accelPedalPos : 32|8@1+ (0.4,0) [0|100] "%" Vector__XXX
 SG_ DI_tractionControlMode : 40|3@1+ (1,0) [0|7] "" Vector__XXX
 SG_ DI_dynoModeAvailable : 43|1@1+ (1,0) [0|1] "" Vector__XXX
 SG_ DI_epbRequest : 44|2@1+ (1,0) [0|3] "" Vector__XXX
 SG_ DI_brakeSource : 46|1@1+ (1,0) [0|1] "" Vector__XXX
 SG_ DI_keepDrivePowerStateRequest : 47|1@1+ (1,0) [0|1] "" Vector__XXX
 SG_ DI_trackModeState : 48|2@1+ (1,0) [0|3] "" Vector__XXX
 SG_ DI_autonomyControlActive : 50|1@1+ (1,0) [0|1] "" Vector__XXX
 SG_ DI_regenLight : 51|1@1+ (1,0) [0|1] "" Vector__XXX
 SG_ DI_vehicleAcceleration : 52|12@1- (0.01,0) [-20.47|20.47] "m/s^2" Vector__XXX

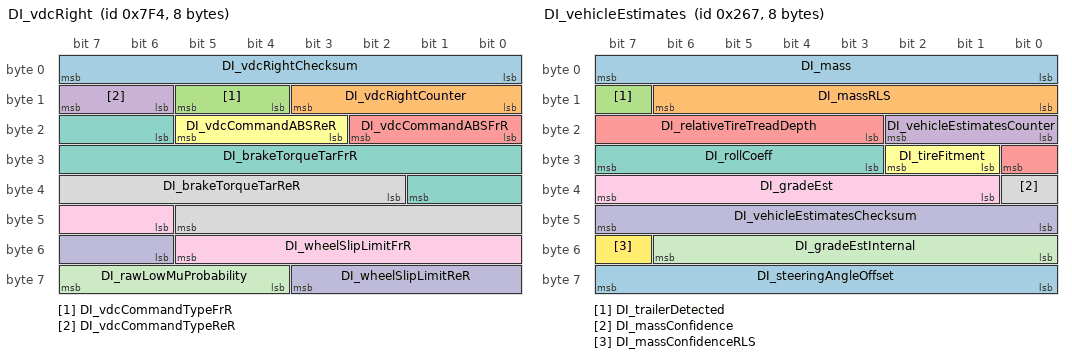
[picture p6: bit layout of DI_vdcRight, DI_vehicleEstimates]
BO_ 2036 DI_vdcRight: 8 DI
 SG_ DI_vdcRightChecksum : 0|8@1+ (1,0) [0|255] "" Vector__XXX
 SG_ DI_vdcRightCounter : 8|4@1+ (1,0) [0|15] "" Vector__XXX
 SG_ DI_vdcCommandTypeFrR : 12|2@1+ (1,0) [0|3] "" Vector__XXX
 SG_ DI_vdcCommandTypeReR : 14|2@1+ (1,0) [0|3] "" Vector__XXX
 SG_ DI_vdcCommandABSFrR : 16|3@1+ (1,0) [0|7] "" Vector__XXX
 SG_ DI_vdcCommandABSReR : 19|3@1+ (1,0) [0|7] "" Vector__XXX
 SG_ DI_brakeTorqueTarFrR : 22|12@1+ (3,-3) [-3|12282] "Nm" Vector__XXX
 SG_ DI_brakeTorqueTarReR : 34|12@1+ (3,-3) [-3|12282] "Nm" Vector__XXX
 SG_ DI_wheelSlipLimitFrR : 46|8@1+ (0.004,-0.004) [-0.004|1] "1" Vector__XXX
 SG_ DI_wheelSlipLimitReR : 54|6@1+ (0.004,-0.004) [-0.004|0.248] "1" Vector__XXX
 SG_ DI_rawLowMuProbability : 60|4@1+ (0.06666667,0) [0|1] "-" Vector__XXX

BO_ 615 DI_vehicleEstimates: 8 DI
 SG_ DI_mass : 0|8@1+ (25,1500) [1500|7850] "kg" Vector__XXX
 SG_ DI_massRLS : 8|7@1+ (45,1500) [1500|7170] "kg" Vector__XXX
 SG_ DI_trailerDetected : 15|1@1+ (1,0) [0|1] "" Vector__XXX
 SG_ DI_vehicleEstimatesCounter : 16|3@1+ (1,0) [0|7] "" Vector__XXX
 SG_ DI_relativeTireTreadDepth : 19|6@1- (0.4,0) [-12.4|12.4] "mm" Vector__XXX
 SG_ DI_tireFitment : 25|2@1+ (1,0) [0|3] "" Vector__XXX
 SG_ DI_rollCoeff : 27|5@1+ (0.001,0) [0|0.03] "g" Vector__XXX
 SG_ DI_massConfidence : 32|1@1+ (1,0) [0|1] "" Vector__XXX
 SG_ DI_gradeEst : 33|7@1- (1,0) [-40|40] "%" Vector__XXX
 SG_ DI_vehicleEstimatesChecksum : 40|8@1+ (1,0) [0|255] "" Vector__XXX
 SG_ DI_gradeEstInternal : 48|7@1- (1,0) [-40|40] "%" Vector__XXX
 SG_ DI_massConfidenceRLS : 55|1@1+ (1,0) [0|1] "" Vector__XXX
 SG_ DI_steeringAngleOffset : 56|8@1- (0.2,0) [-25.6|25.4] "Deg" Vector__XXX

BO_ 1237 DPB_alertLog: 8 DPB
 SG_ DPB_alertID : 0|9@1+ (1,0) [0|511] "" Vector__XXX
 SG_ DPB_alertState : 15|1@1+ (1,0) [0|1] "" Vector__XXX

CM_ BO_ 789 "Rear drive inverter message: temperature";
CM_ SG_ 789 DIR_tempIndex "Rear drive inverter: temp index";
CM_ SG_ 789 DIR_inverterTQF "Detects the Drive Inverter (DI) outlet temperature qualifier.";
CM_ SG_ 789 DIR_pcbT "Rear drive inverter: pcb t";
CM_ SG_ 789 DIR_inverterT "Drive Inverter measured outlet temperature";
CM_ SG_ 789 DIR_statorT "Drive Inverter measured stator temperature.";
CM_ SG_ 789 DIR_dcCapT "Rear drive inverter: dc cap t";
CM_ SG_ 789 DIR_heatsinkT "Drive Inverter measured heatsink temperature";
CM_ SG_ 789 DIR_inverterTpct "Rear drive inverter: inverter tpct";
CM_ SG_ 789 DIR_statorTpct "Rear drive inverter: stator tpct";
CM_ SG_ 789 DIR_fluidInTemp "Inlet fluid temperature";
CM_ SG_ 789 DIR_normalFetBurnIn "Rear drive inverter: normal fet burn in";
CM_ SG_ 789 DIR_additionalFetBurnIn "Rear drive inverter: additional fet burn in";
CM_ SG_ 789 DIR_currentWeibullMiles "Rear drive inverter: current weibull miles";
CM_ SG_ 789 DIR_endOfServiceWeibullMiles "Rear drive inverter: end of service weibull miles";
CM_ SG_ 789 DIR_burnInDamageRatio "Rear drive inverter: burn in damage ratio";
CM_ SG_ 789 DIR_inverterSensorEst "Rear drive inverter: inverter sensor est";
CM_ SG_ 789 DIR_inverterHS1Est "Rear drive inverter: inverter HS1 est";
CM_ SG_ 789 DIR_initialBurnInVehicleOdometer "Rear drive inverter: initial burn in vehicle odometer";
CM_ SG_ 789 DIR_inverterHS2Est "Rear drive inverter: inverter HS2 est";
CM_ SG_ 789 DIR_inverterInletEst "Rear drive inverter: inverter inlet est";
CM_ SG_ 789 DIR_statorHousingTemp "Rear drive inverter: stator housing temp";
CM_ BO_ 1495 "Rear drive inverter message: thermal control";
CM_ SG_ 1495 DIR_passiveInletTempReq "Rear drive inverter: passive inlet temp req";
CM_ SG_ 1495 DIR_activeInletTempReq "Rear drive inverter: active inlet temp req";
CM_ SG_ 1495 DIR_coolantFlowReq "Coolant flow requested";
CM_ SG_ 1495 DIR_oilFlowReq "Rear drive inverter: oil flow req";
CM_ SG_ 1495 DIR_criticalFlowReq "Rear drive inverter: critical flow req";
CM_ SG_ 1495 DIR_burnInStatus "Rear drive inverter: burn in status";
CM_ BO_ 264 "Rear drive inverter message: torque";
CM_ SG_ 264 DIR_torqueChecksum "Rear drive inverter: torque checksum";
CM_ SG_ 264 DIR_torqueCounter "Rear drive inverter: torque counter";
CM_ SG_ 264 DIR_torqueCommand "Torque commanded to the drive unit, referred to the axle/wheel";
CM_ SG_ 264 DIR_axleSpeedQF "Rear drive inverter: axle speed QF";
CM_ SG_ 264 DIR_torqueActual "Actual torque the drive unit is controlling to referred to the axle/wheel";
CM_ SG_ 264 DIR_axleSpeed "Drive Inverter motor speed normalized at axle level";
CM_ SG_ 264 DIR_axleTorqueQF "Rear drive inverter: axle torque QF";
CM_ SG_ 264 DIR_axlePowerCalcQF "Rear drive inverter: axle power calc QF";
CM_ SG_ 264 DIR_gear "Rear drive inverter: gear";
CM_ BO_ 1319 "Drive inverter message: alert log";
CM_ SG_ 1319 DI_alertID "Drive inverter: alert ID";
CM_ SG_ 1319 DI_alertState "Drive inverter: alert state";
CM_ SG_ 1319 DI_a004_unavailableReason "Drive inverter: a004 unavailable reason";
CM_ SG_ 1319 DI_a007_button "Drive inverter: a007 button";
CM_ SG_ 1319 DI_a007_buttonStuckTime "Drive inverter: a007 button stuck time";
CM_ SG_ 1319 DI_a010_sccReset "Drive inverter: a010 scc reset";
CM_ SG_ 1319 DI_a010_hibernate "Drive inverter: a010 hibernate";
CM_ SG_ 1319 DI_a010_hwBist "Drive inverter: a010 hw bist";
CM_ SG_ 1319 DI_a010_nmiWatchdog "Drive inverter: a010 nmi watchdog";
CM_ SG_ 1319 DI_a010_watchdog "Drive inverter: a010 watchdog";
CM_ SG_ 1319 DI_a010_clockFailNmi "Drive inverter: a010 clock fail nmi";
CM_ SG_ 1319 DI_a010_ramUncErrorNmi "Drive inverter: a010 ram unc error nmi";
CM_ SG_ 1319 DI_a010_flashUncErrorNmi "Drive inverter: a010 flash unc error nmi";
CM_ SG_ 1319 DI_a010_cpu1signMismatchNmi "Drive inverter: a010 cpu1sign mismatch nmi";
CM_ SG_ 1319 DI_a010_cpu2signMismatchNmi "Drive inverter: a010 cpu2sign mismatch nmi";
CM_ SG_ 1319 DI_a010_pieVectErrorNmi "Drive inverter: a010 pie vect error nmi";
CM_ SG_ 1319 DI_a010_sysDbgNmi "Drive inverter: a010 sys dbg nmi";
CM_ SG_ 1319 DI_a010_rlNmi "Drive inverter: a010 rl nmi";
CM_ SG_ 1319 DI_a010_ovfNmi "Drive inverter: a010 ovf nmi";
CM_ SG_ 1319 DI_a010_wdtFlags "Drive inverter: a010 wdt flags";
CM_ SG_ 1319 DI_a012_accel1SupplyV "Drive inverter: a012 accel1 supply v";
CM_ SG_ 1319 DI_a012_accel2SupplyV "Drive inverter: a012 accel2 supply v";
CM_ SG_ 1319 DI_a013_address "Drive inverter: a013 address";
CM_ SG_ 1319 DI_a013_errorType "Drive inverter: a013 error type";
CM_ SG_ 1319 DI_a015_reason "Drive inverter: a015 reason";
CM_ SG_ 1319 DI_a020_difHvilStatus "Drive inverter: a020 dif hvil status";
CM_ SG_ 1319 DI_a020_difStatusValid "Drive inverter: a020 dif status valid";
CM_ SG_ 1319 DI_a020_dirHvilStatus "Drive inverter: a020 dir hvil status";
CM_ SG_ 1319 DI_a020_dirStatusValid "Drive inverter: a020 dir status valid";
CM_ SG_ 1319 DI_a020_vehiclePowerState "Drive inverter: a020 vehicle power state";
CM_ SG_ 1319 DI_a020_hvilSystemStatus "Drive inverter: a020 hvil system status";
CM_ SG_ 1319 DI_a021_packVoltage "Drive inverter: a021 pack voltage";
CM_ SG_ 1319 DI_a021_maxBusVoltage "Drive inverter: a021 max bus voltage";
CM_ SG_ 1319 DI_a024_pedalPos "Drive inverter: a024 pedal pos";
CM_ SG_ 1319 DI_a024_brakePressed "Drive inverter: a024 brake pressed";
CM_ SG_ 1319 DI_a024_currentGear "Drive inverter: a024 current gear";
CM_ SG_ 1319 DI_a025_backfillState "Drive inverter: a025 backfill state";
CM_ SG_ 1319 DI_a025_bfillUnavailableReason "Drive inverter: a025 bfill unavailable reason";
CM_ SG_ 1319 DI_a036_numFaultedUnits "Drive inverter: a036 num faulted units";
CM_ SG_ 1319 DI_a036_numAvailableUnits "Drive inverter: a036 num available units";
CM_ SG_ 1319 DI_a040_torque "Drive inverter: a040 torque";
CM_ SG_ 1319 DI_a040_capability "Drive inverter: a040 capability";
CM_ SG_ 1319 DI_a040_power "Drive inverter: a040 power";
CM_ SG_ 1319 DI_a040_status "Drive inverter: a040 status";
CM_ SG_ 1319 DI_a040_capability2 "Drive inverter: a040 capability2";
CM_ SG_ 1319 DI_a040_hvStatus "Drive inverter: a040 hv status";
CM_ SG_ 1319 DI_a040_temperature "Drive inverter: a040 temperature";
CM_ SG_ 1319 DI_a042_state4 "Drive inverter: a042 state4";
CM_ SG_ 1319 DI_a043_state4 "Drive inverter: a043 state4";
CM_ SG_ 1319 DI_a051_dcCableCurrentEst "Drive inverter: a051 dc cable current est";
CM_ SG_ 1319 DI_a051_packCurrent "Drive inverter: a051 pack current";
CM_ SG_ 1319 DI_a052_torque "Drive inverter: a052 torque";
CM_ SG_ 1319 DI_a052_capability "Drive inverter: a052 capability";
CM_ SG_ 1319 DI_a052_power "Drive inverter: a052 power";
CM_ SG_ 1319 DI_a052_status "Drive inverter: a052 status";
CM_ SG_ 1319 DI_a052_capability2 "Drive inverter: a052 capability2";
CM_ SG_ 1319 DI_a052_hvStatus "Drive inverter: a052 hv status";
CM_ SG_ 1319 DI_a052_temperature "Drive inverter: a052 temperature";
CM_ SG_ 1319 DI_a062_limpReason "Drive inverter: a062 limp reason";
CM_ SG_ 1319 DI_a063_gpoReason "Drive inverter: a063 gpo reason";
CM_ SG_ 1319 DI_a064_hvState "Drive inverter: a064 hv state";
CM_ SG_ 1319 DI_a064_vehiclePowerState "Drive inverter: a064 vehicle power state";
CM_ SG_ 1319 DI_a064_vehicleSpeed "Drive inverter: a064 vehicle speed";
CM_ SG_ 1319 DI_a074_recoveredGear "Drive inverter: a074 recovered gear";
CM_ SG_ 1319 DI_a074_vehicleSpeed "Drive inverter: a074 vehicle speed";
CM_ SG_ 1319 DI_a074_attemptCount "Drive inverter: a074 attempt count";
CM_ SG_ 1319 DI_a074_unit0Gear "Drive inverter: a074 unit0 gear";
CM_ SG_ 1319 DI_a074_unit1Gear "Drive inverter: a074 unit1 gear";
CM_ SG_ 1319 DI_a074_unit2Gear "Drive inverter: a074 unit2 gear";
CM_ SG_ 1319 DI_a074_failureReason "Drive inverter: a074 failure reason";
CM_ SG_ 1319 DI_a074_epbSystemStatus "Drive inverter: a074 epb system status";
CM_ SG_ 1319 DI_a076_lvSupplyV "Drive inverter: a076 lv supply v";
CM_ SG_ 1319 DI_a077_lvSupplyV "Drive inverter: a077 lv supply v";
CM_ SG_ 1319 DI_a078_adcRefChan "Drive inverter: a078 adc ref chan";
CM_ SG_ 1319 DI_a078_adcRefLowAvg "Drive inverter: a078 adc ref low avg";
CM_ SG_ 1319 DI_a079_adcRefChan "Drive inverter: a079 adc ref chan";
CM_ SG_ 1319 DI_a079_adcRefHighAvg "Drive inverter: a079 adc ref high avg";
CM_ SG_ 1319 DI_a083_brakeSwitchNO "Drive inverter: a083 brake switch NO";
CM_ SG_ 1319 DI_a083_brakeSwitchNC "Drive inverter: a083 brake switch NC";
CM_ SG_ 1319 DI_a083_brakeSwitchIrrationalNO "Drive inverter: a083 brake switch irrational NO";
CM_ SG_ 1319 DI_a083_brakeSwitchIrrationalNC "Drive inverter: a083 brake switch irrational NC";
CM_ SG_ 1319 DI_a086_DPB_actuator3 "Drive inverter: a086 DPB actuator3";
CM_ SG_ 1319 DI_a086_DPB_redundantBrakingStat "Drive inverter: a086 DPB redundant braking status";
CM_ SG_ 1319 DI_a087_gtwCarConfig "Drive inverter: a087 gtw car config";
CM_ SG_ 1319 DI_a087_gtwTime "Drive inverter: a087 gtw time";
CM_ SG_ 1319 DI_a087_gtwUpdateStatus "Drive inverter: a087 gtw update status";
CM_ SG_ 1319 DI_a087_gearControl "Drive inverter: a087 gear control";
CM_ SG_ 1319 DI_a087_carState "Drive inverter: a087 car state";
CM_ SG_ 1319 DI_a089_SCCM_rightStalk "Drive inverter: a089 SCCM right stalk";
CM_ SG_ 1319 DI_a090_reason "Drive inverter: a090 reason";
CM_ SG_ 1319 DI_a090_systemState "Drive inverter: a090 system state";
CM_ SG_ 1319 DI_a090_state "Drive inverter: a090 state";
CM_ SG_ 1319 DI_a090_locState "Drive inverter: a090 loc state";
CM_ SG_ 1319 DI_a090_state2 "Drive inverter: a090 state2";
CM_ SG_ 1319 DI_a090_state4 "Drive inverter: a090 state4";
CM_ SG_ 1319 DI_a091_ESP_brakeTorque "Drive inverter: a091 ESP brake torque";
CM_ SG_ 1319 DI_a091_ESP_wheelSpeeds "Drive inverter: a091 ESP wheel speeds";
CM_ SG_ 1319 DI_a091_ESP_wheelRotation "Drive inverter: a091 ESP wheel rotation";
CM_ SG_ 1319 DI_a091_ESP_motorLimits "Drive inverter: a091 ESP motor limits";
CM_ SG_ 1319 DI_a091_ESP_offsets "Drive inverter: a091 ESP offsets";
CM_ SG_ 1319 DI_a091_ESP_status "Drive inverter: a091 ESP status";
CM_ SG_ 1319 DI_a091_ESP_party3 "Drive inverter: a091 ESP party3";
CM_ SG_ 1319 DI_a091_ESP_redundantBrakingStat "Drive inverter: a091 ESP redundant braking status";
CM_ SG_ 1319 DI_a092_bmsStatus "Drive inverter: a092 bms status";
CM_ SG_ 1319 DI_a092_bmsDriveLimits "Drive inverter: a092 bms drive limits";
CM_ SG_ 1319 DI_a092_bmsHvBusStatus "Drive inverter: a092 bms hv bus status";
CM_ SG_ 1319 DI_a092_bmsPowerAvailable "Drive inverter: a092 bms power available";
CM_ SG_ 1319 DI_a092_bmsBmbMinMax "Drive inverter: a092 bms bmb min max";
CM_ SG_ 1319 DI_a092_bmsSocStatus "Drive inverter: a092 bms soc status";
CM_ SG_ 1319 DI_a092_bmsThermalStatus "Drive inverter: a092 bms thermal status";
CM_ SG_ 1319 DI_a092_bmsCtrStatus "Drive inverter: a092 bms ctr status";
CM_ SG_ 1319 DI_a092_bmsVoltageRegGain "Drive inverter: a092 bms voltage reg gain";
CM_ SG_ 1319 DI_a092_bmsPackConfig "Drive inverter: a092 bms pack config";
CM_ SG_ 1319 DI_a092_bmsSystemStatus "Drive inverter: a092 bms system status";
CM_ SG_ 1319 DI_a096_const_fast "Drive inverter: a096 const fast";
CM_ SG_ 1319 DI_a096_text_fast "Drive inverter: a096 text fast";
CM_ SG_ 1319 DI_a096_text_flash "Drive inverter: a096 text flash";
CM_ SG_ 1319 DI_a096_mem_data "Drive inverter: a096 mem data";
CM_ SG_ 1319 DI_a096_mem_regs "Drive inverter: a096 mem regs";
CM_ SG_ 1319 DI_a096_boot_flash "Drive inverter: a096 boot flash";
CM_ SG_ 1319 DI_a096_word1 "Drive inverter: a096 word1";
CM_ SG_ 1319 DI_a096_word2 "Drive inverter: a096 word2";
CM_ SG_ 1319 DI_a097_errorType "Drive inverter: a097 error type";
CM_ SG_ 1319 DI_a097_lineNumber "Drive inverter: a097 line number";
CM_ SG_ 1319 DI_a097_argument "Drive inverter: a097 argument";
CM_ SG_ 1319 DI_a098_page0Counter "Drive inverter: a098 page0 counter";
CM_ SG_ 1319 DI_a098_page1Counter "Drive inverter: a098 page1 counter";
CM_ SG_ 1319 DI_a098_page2Counter "Drive inverter: a098 page2 counter";
CM_ SG_ 1319 DI_a098_pageID "Drive inverter: a098 page ID";
CM_ SG_ 1319 DI_a098_recordID "Drive inverter: a098 record ID";
CM_ SG_ 1319 DI_a098_errorCode "Drive inverter: a098 error code";
CM_ SG_ 1319 DI_a103_BB_status "Drive inverter: a103 BB status";
CM_ SG_ 1319 DI_a103_BB_brakeActuation "Drive inverter: a103 BB brake actuation";
CM_ SG_ 1319 DI_a104_proxIrrationalReason "Drive inverter: a104 prox irrational reason";
CM_ SG_ 1319 DI_a105_cpStatus "Drive inverter: a105 cp status";
CM_ SG_ 1319 DI_a110_EPBL_status "Drive inverter: a110 EPBL status";
CM_ SG_ 1319 DI_a110_EPBR_status "Drive inverter: a110 EPBR status";
CM_ SG_ 1319 DI_a110_EPBL_autonomyHealth "Drive inverter: a110 EPBL autonomy health";
CM_ SG_ 1319 DI_a110_EPBR_autonomyHealth "Drive inverter: a110 EPBR autonomy health";
CM_ SG_ 1319 DI_a120_blendingState "Drive inverter: a120 blending state";
CM_ SG_ 1319 DI_a120_blendingUnavailableReaso "Drive inverter: a120 blending unavailable reason";
CM_ SG_ 1319 DI_a124_undrivenWheelMPH "Drive inverter: a124 undriven wheel MPH";
CM_ SG_ 1319 DI_a124_cruiseFaultReason "Drive inverter: a124 cruise fault reason";
CM_ SG_ 1319 DI_a124_cruiseFaultStack "Drive inverter: a124 cruise fault stack";
CM_ SG_ 1319 DI_a125_maxDischargeCurrent "Drive inverter: a125 max discharge current";
CM_ SG_ 1319 DI_a125_maxChargeCurrent "Drive inverter: a125 max charge current";
CM_ SG_ 1319 DI_a125_minBusVoltage "Drive inverter: a125 min bus voltage";
CM_ SG_ 1319 DI_a130_aebFaultReason "Drive inverter: a130 aeb fault reason";
CM_ SG_ 1319 DI_a130_aebSmState "Drive inverter: a130 aeb sm state";
CM_ SG_ 1319 DI_a130_dasAebEvent "Drive inverter: a130 das aeb event";
CM_ SG_ 1319 DI_a130_aebBrakeTorqueCommand "Drive inverter: a130 aeb brake torque command";
CM_ SG_ 1319 DI_a131_totalTimeRemaining "Drive inverter: a131 total time remaining";
CM_ SG_ 1319 DI_a131_warnSpeedLimit "Drive inverter: a131 warn speed limit";
CM_ SG_ 1319 DI_a131_warnTimeRemaining "Drive inverter: a131 warn time remaining";
CM_ SG_ 1319 DI_a133_vhldSmState "Drive inverter: a133 vhld sm state";
CM_ SG_ 1319 DI_a133_reverseGear "Drive inverter: a133 reverse gear";
CM_ SG_ 1319 DI_a133_vhldGrade "Drive inverter: a133 vhld grade";
CM_ SG_ 1319 DI_a134_wheelSpeedDiffFrL "Drive inverter: a134 wheel speed diff fr l";
CM_ SG_ 1319 DI_a134_wheelSpeedDiffFrR "Drive inverter: a134 wheel speed diff fr r";
CM_ SG_ 1319 DI_a134_wheelSpeedDiffReL "Drive inverter: a134 wheel speed diff re l";
CM_ SG_ 1319 DI_a134_wheelSpeedDiffReR "Drive inverter: a134 wheel speed diff re r";
CM_ SG_ 1319 DI_a135_vhldFaultReason "Drive inverter: a135 vhld fault reason";
CM_ SG_ 1319 DI_a135_vhldSmState "Drive inverter: a135 vhld sm state";
CM_ SG_ 1319 DI_a135_vhldBrakeApply "Drive inverter: a135 vhld brake apply";
CM_ SG_ 1319 DI_a135_vhldBrakeTorqueCommand "Drive inverter: a135 vhld brake torque command";
CM_ SG_ 1319 DI_a135_vhldTotalBrakeTorque "Drive inverter: a135 vhld total brake torque";
CM_ SG_ 1319 DI_a135_vhldPropulsiveTorque "Drive inverter: a135 vhld propulsive torque";
CM_ SG_ 1319 DI_a135_vhldGrade "Drive inverter: a135 vhld grade";
CM_ SG_ 1319 DI_a140_PTC_feedbackStatus "Drive inverter: a140 PTC feedback status";
CM_ SG_ 1319 DI_a141_DAS_control "Drive inverter: a141 DAS control";
CM_ SG_ 1319 DI_a141_DAS_pmmControl "Drive inverter: a141 DAS pmm control";
CM_ SG_ 1319 DI_a141_DAS_status "Drive inverter: a141 DAS status";
CM_ SG_ 1319 DI_a141_DAS_status2 "Drive inverter: a141 DAS status2";
CM_ SG_ 1319 DI_a141_DAS_smartShift "Drive inverter: a141 DAS smart shift";
CM_ SG_ 1319 DI_a141_DAS_longControl "Drive inverter: a141 DAS long control";
CM_ SG_ 1319 DI_a141_DAS_longControlTuningPar "Drive inverter: a141 DAS long control tuning parameters";
CM_ SG_ 1319 DI_a141_DAS_autonomyControl "Drive inverter: a141 DAS autonomy control";
CM_ SG_ 1319 DI_a141_DAS_redundantBrakingCont "Drive inverter: a141 DAS redundant braking control";
CM_ SG_ 1319 DI_a143_mechPowerLimit "Drive inverter: a143 mech power limit";
CM_ SG_ 1319 DI_a143_systemTorqueLimit "Drive inverter: a143 system torque limit";
CM_ SG_ 1319 DI_a144_autopilot "Drive inverter: a144 autopilot";
CM_ SG_ 1319 DI_a144_chassisType "Drive inverter: a144 chassis type";
CM_ SG_ 1319 DI_a144_drivetrainType "Drive inverter: a144 drivetrain type";
CM_ SG_ 1319 DI_a144_packEnergy "Drive inverter: a144 pack energy";
CM_ SG_ 1319 DI_a144_packPerformanceDeviation "Drive inverter: a144 pack performance deviation";
CM_ SG_ 1319 DI_a144_performancePackage "Drive inverter: a144 performance package";
CM_ SG_ 1319 DI_a144_vdcType "Drive inverter: a144 vdc type";
CM_ SG_ 1319 DI_a144_brakeHWType "Drive inverter: a144 brake HW type";
CM_ SG_ 1319 DI_a144_inverterHardware "Drive inverter: a144 inverter hardware";
CM_ SG_ 1319 DI_a144_cabinPTCHeaterType "Drive inverter: a144 cabin PTC heater type";
CM_ SG_ 1319 DI_a144_frunkLatchType "Drive inverter: a144 frunk latch type";
CM_ SG_ 1319 DI_a144_platformMaxBusVoltage "Drive inverter: a144 platform max bus voltage";
CM_ SG_ 1319 DI_a144_oilPump1HwType "Drive inverter: a144 oil pump1 hw type";
CM_ SG_ 1319 DI_a144_oilPump2HwType "Drive inverter: a144 oil pump2 hw type";
CM_ SG_ 1319 DI_a144_heatsinkType "Drive inverter: a144 heatsink type";
CM_ SG_ 1319 DI_a144_softPerformanceLimit "Drive inverter: a144 soft performance limit";
CM_ SG_ 1319 DI_a144_brakeActuationType "Drive inverter: a144 brake actuation type";
CM_ SG_ 1319 DI_a144_dasHw "Drive inverter: a144 das hw";
CM_ SG_ 1319 DI_a144_powerLiftgateType "Drive inverter: a144 power liftgate type";
CM_ SG_ 1319 DI_a144_chassisSubType "Drive inverter: a144 chassis sub type";
CM_ SG_ 1319 DI_a144_autonomyFeatureType "Drive inverter: a144 autonomy feature type";
CM_ SG_ 1319 DI_a146_panicReason "Drive inverter: a146 panic reason";
CM_ SG_ 1319 DI_a155_sensors "Drive inverter: a155 sensors";
CM_ SG_ 1319 DI_a155_coolant "Drive inverter: a155 coolant";
CM_ SG_ 1319 DI_a155_LVPowerState "Drive inverter: a155 LV power state";
CM_ SG_ 1319 DI_a155_vehicleStatus "Drive inverter: a155 vehicle status";
CM_ SG_ 1319 DI_a155_status "Drive inverter: a155 status";
CM_ SG_ 1319 DI_a155_leftDoorStatus "Drive inverter: a155 left door status";
CM_ SG_ 1319 DI_a155_rightDoorStatus "Drive inverter: a155 right door status";
CM_ SG_ 1319 DI_a155_vcleftSwitchStatus "Drive inverter: a155 vcleft switch status";
CM_ SG_ 1319 DI_a155_restraintStatus "Drive inverter: a155 restraint status";
CM_ SG_ 1319 DI_a155_systemStatus "Drive inverter: a155 system status";
CM_ SG_ 1319 DI_a155_prndStatus "Drive inverter: a155 prnd status";
CM_ SG_ 1319 DI_a155_liftgateStatus "Drive inverter: a155 liftgate status";
CM_ SG_ 1319 DI_a157_RCM_inertial1 "Drive inverter: a157 RCM inertial1";
CM_ SG_ 1319 DI_a157_RCM_inertial2 "Drive inverter: a157 RCM inertial2";
CM_ SG_ 1319 DI_a158_IBST_party1 "Drive inverter: a158 IBST party1";
CM_ SG_ 1319 DI_a158_BUS1_IBST_status "Drive inverter: a158 BUS1 IBST status";
CM_ SG_ 1319 DI_a158_BUS2_IBST_status "Drive inverter: a158 BUS2 IBST status";
CM_ SG_ 1319 DI_a158_IBST_redundantBrakingSta "Drive inverter: a158 IBST redundant braking status";
CM_ SG_ 1319 DI_a160_kTire "Drive inverter: a160 k tire";
CM_ SG_ 1319 DI_a160_tireFitment "Drive inverter: a160 tire fitment";
CM_ SG_ 1319 DI_a160_wearFactorFrL "Drive inverter: a160 wear factor fr l";
CM_ SG_ 1319 DI_a160_wearFactorFrR "Drive inverter: a160 wear factor fr r";
CM_ SG_ 1319 DI_a160_wearFactorReL "Drive inverter: a160 wear factor re l";
CM_ SG_ 1319 DI_a160_distanceSinceLastTireCon "Drive inverter: a160 distance since last tire config";
CM_ SG_ 1319 DI_a161_EPAS3P_sysStatus "Drive inverter: a161 EPAS3 p sys status";
CM_ SG_ 1319 DI_a161_EPAS3P_angleCalib "Drive inverter: a161 EPAS3 p angle calib";
CM_ SG_ 1319 DI_a162_shiftDeniedReason "Drive inverter: a162 shift denied reason";
CM_ SG_ 1319 DI_a162_motorSpeed "Drive inverter: a162 motor speed";
CM_ SG_ 1319 DI_a162_essContClosed "Drive inverter: a162 ess cont closed";
CM_ SG_ 1319 DI_a162_autonomyBehavior "Drive inverter: a162 autonomy behavior";
CM_ SG_ 1319 DI_a162_pedalPos "Drive inverter: a162 pedal pos";
CM_ SG_ 1319 DI_a162_currentGear "Drive inverter: a162 current gear";
CM_ SG_ 1319 DI_a162_requestedGear "Drive inverter: a162 requested gear";
CM_ SG_ 1319 DI_a162_requestSource "Drive inverter: a162 request source";
CM_ SG_ 1319 DI_a162_timeSinceCruiseCancel "Drive inverter: a162 time since cruise cancel";
CM_ SG_ 1319 DI_a162_chargeCableConnected "Drive inverter: a162 charge cable connected";
CM_ SG_ 1319 DI_a162_frunkOpen "Drive inverter: a162 frunk open";
CM_ SG_ 1319 DI_a162_sysStateExitCondition "Drive inverter: a162 sys state exit condition";
CM_ SG_ 1319 DI_a163_motorSpeed "Drive inverter: a163 motor speed";
CM_ SG_ 1319 DI_a163_currentGear "Drive inverter: a163 current gear";
CM_ SG_ 1319 DI_a163_requestedGear "Drive inverter: a163 requested gear";
CM_ SG_ 1319 DI_a163_requestSource "Drive inverter: a163 request source";
CM_ SG_ 1319 DI_a164_motorSpeed "Drive inverter: a164 motor speed";
CM_ SG_ 1319 DI_a164_pedalPos "Drive inverter: a164 pedal pos";
CM_ SG_ 1319 DI_a164_torqueDriver "Drive inverter: a164 torque driver";
CM_ SG_ 1319 DI_a170_tireSeasonSelected "Drive inverter: a170 tire season selected";
CM_ SG_ 1319 DI_a170_kTire "Drive inverter: a170 k tire";
CM_ SG_ 1319 DI_a170_tireFitment "Drive inverter: a170 tire fitment";
CM_ SG_ 1319 DI_a170_wearFactorFrL "Drive inverter: a170 wear factor fr l";
CM_ SG_ 1319 DI_a170_wearFactorFrR "Drive inverter: a170 wear factor fr r";
CM_ SG_ 1319 DI_a170_wearFactorReL "Drive inverter: a170 wear factor re l";
CM_ SG_ 1319 DI_a170_odometer "Drive inverter: a170 odometer";
CM_ SG_ 1319 DI_a170_distanceSinceLastTireCon "Drive inverter: a170 distance since last tire config";
CM_ SG_ 1319 DI_a170_treadDepthAlertSet "Drive inverter: a170 tread depth alert set";
CM_ SG_ 1319 DI_a172_motorSpeed "Drive inverter: a172 motor speed";
CM_ SG_ 1319 DI_a172_pedalPos "Drive inverter: a172 pedal pos";
CM_ SG_ 1319 DI_a172_currentGear "Drive inverter: a172 current gear";
CM_ SG_ 1319 DI_a172_timeSinceCruiseCancel "Drive inverter: a172 time since cruise cancel";
CM_ SG_ 1319 DI_a173_brakeApply "Drive inverter: a173 brake apply";
CM_ SG_ 1319 DI_a173_pedalPos "Drive inverter: a173 pedal pos";
CM_ SG_ 1319 DI_a175_crsNotAvailableReason "Drive inverter: a175 crs not available reason";
CM_ SG_ 1319 DI_a175_crsNotAvailableStack "Drive inverter: a175 crs not available stack";
CM_ SG_ 1319 DI_a177_newFitment "Drive inverter: a177 new fitment";
CM_ SG_ 1319 DI_a178_offsetValue "Drive inverter: a178 offset value";
CM_ SG_ 1319 DI_a180_crsNotAvailableReason "Drive inverter: a180 crs not available reason";
CM_ SG_ 1319 DI_a184_apcCancelReason "Drive inverter: a184 apc cancel reason";
CM_ SG_ 1319 DI_a184_apcUnavailableReason "Drive inverter: a184 apc unavailable reason";
CM_ SG_ 1319 DI_a184_autoparkInternalState "Drive inverter: a184 autopark internal state";
CM_ SG_ 1319 DI_a185_summonActive "Drive inverter: a185 summon active";
CM_ SG_ 1319 DI_a185_apcCancelReason "Drive inverter: a185 apc cancel reason";
CM_ SG_ 1319 DI_a185_apcUnavailableReason "Drive inverter: a185 apc unavailable reason";
CM_ SG_ 1319 DI_a185_crsNotAvailableReason "Drive inverter: a185 crs not available reason";
CM_ SG_ 1319 DI_a185_crsFaultReason "Drive inverter: a185 crs fault reason";
CM_ SG_ 1319 DI_a185_autoparkInternalState "Drive inverter: a185 autopark internal state";
CM_ SG_ 1319 DI_a187_filteredAccel "Drive inverter: a187 filtered accel";
CM_ SG_ 1319 DI_a187_rawPedal "Drive inverter: a187 raw pedal";
CM_ SG_ 1319 DI_a187_systemTorqueCommand "Drive inverter: a187 system torque command";
CM_ SG_ 1319 DI_a189_accelPedal "Drive inverter: a189 accel pedal";
CM_ SG_ 1319 DI_a189_grade "Drive inverter: a189 grade";
CM_ SG_ 1319 DI_a189_brakePressed "Drive inverter: a189 brake pressed";
CM_ SG_ 1319 DI_a189_systemTorque "Drive inverter: a189 system torque";
CM_ SG_ 1319 DI_a189_motorSpeed "Drive inverter: a189 motor speed";
CM_ SG_ 1319 DI_a190_relativeTireTreadDepth "Drive inverter: a190 relative tire tread depth";
CM_ SG_ 1319 DI_a190_treadWearFactorFrL "Drive inverter: a190 tread wear factor fr l";
CM_ SG_ 1319 DI_a190_treadWearFactorFrR "Drive inverter: a190 tread wear factor fr r";
CM_ SG_ 1319 DI_a190_treadWearFactorReL "Drive inverter: a190 tread wear factor re l";
CM_ SG_ 1319 DI_a190_treadWearFactorAvgConfid "Drive inverter: a190 tread wear factor avg confidence";
CM_ SG_ 1319 DI_a190_tireFitment "Drive inverter: a190 tire fitment";
CM_ SG_ 1319 DI_a191_motorSpeed "Drive inverter: a191 motor speed";
CM_ SG_ 1319 DI_a191_reverseDeniedAfterCruise "Drive inverter: a191 reverse denied after cruise";
CM_ SG_ 1319 DI_a191_currentGear "Drive inverter: a191 current gear";
CM_ SG_ 1319 DI_a191_requestedGear "Drive inverter: a191 requested gear";
CM_ SG_ 1319 DI_a191_requestSource "Drive inverter: a191 request source";
CM_ SG_ 1319 DI_a191_timeSinceCruiseCancel "Drive inverter: a191 time since cruise cancel";
CM_ SG_ 1319 DI_a193_brakeTorqueFrL "Drive inverter: a193 brake torque fr l";
CM_ SG_ 1319 DI_a193_brakeTorqueFrLLastVal "Drive inverter: a193 brake torque fr l last val";
CM_ SG_ 1319 DI_a193_brakeTorqueFrLCurrVal "Drive inverter: a193 brake torque fr l curr val";
CM_ SG_ 1319 DI_a193_brakeTorqueFrR "Drive inverter: a193 brake torque fr r";
CM_ SG_ 1319 DI_a193_brakeTorqueFrRLastVal "Drive inverter: a193 brake torque fr r last val";
CM_ SG_ 1319 DI_a193_brakeTorqueFrRCurrVal "Drive inverter: a193 brake torque fr r curr val";
CM_ SG_ 1319 DI_a194_brakeTorqueReL "Drive inverter: a194 brake torque re l";
CM_ SG_ 1319 DI_a194_brakeTorqueReLLastVal "Drive inverter: a194 brake torque re l last val";
CM_ SG_ 1319 DI_a194_brakeTorqueReLCurrVal "Drive inverter: a194 brake torque re l curr val";
CM_ SG_ 1319 DI_a194_brakeTorqueReR "Drive inverter: a194 brake torque re r";
CM_ SG_ 1319 DI_a194_brakeTorqueReRLastVal "Drive inverter: a194 brake torque re r last val";
CM_ SG_ 1319 DI_a194_brakeTorqueReRCurrVal "Drive inverter: a194 brake torque re r curr val";
CM_ SG_ 1319 DI_a198_MCPressure "Drive inverter: a198 MC pressure";
CM_ SG_ 1319 DI_a198_MCPressureLastValue "Drive inverter: a198 MC pressure last value";
CM_ SG_ 1319 DI_a198_MCPressCurrValue "Drive inverter: a198 MC press curr value";
CM_ SG_ 1319 DI_a198_steeringAngle "Drive inverter: a198 steering angle";
CM_ SG_ 1319 DI_a198_steeringAngleLastVal "Drive inverter: a198 steering angle last val";
CM_ SG_ 1319 DI_a198_steeringAngleCurrVal "Drive inverter: a198 steering angle curr val";
CM_ SG_ 1319 DI_a199_muVehicleLearnDown "Drive inverter: a199 mu vehicle learn down";
CM_ SG_ 1319 DI_a199_muVehicleDecFilt "Drive inverter: a199 mu vehicle dec filt";
CM_ SG_ 1319 DI_a199_bankAngle "Drive inverter: a199 bank angle";
CM_ SG_ 1319 DI_a199_lateralAccelFilt "Drive inverter: a199 lateral accel filt";
CM_ SG_ 1319 DI_a199_driverIntendedYawRate "Drive inverter: a199 driver intended yaw rate";
CM_ SG_ 1319 DI_a199_vehicleVelocity "Drive inverter: a199 vehicle velocity";
CM_ SG_ 1319 DI_a199_sensorYawRate "Drive inverter: a199 sensor yaw rate";
CM_ SG_ 1319 DI_a199_preControlActive "Drive inverter: a199 pre control active";
CM_ SG_ 1319 DI_a199_oversteerdMzActive "Drive inverter: a199 oversteerd mz active";
CM_ SG_ 1319 DI_a199_decelControlActive "Drive inverter: a199 decel control active";
CM_ SG_ 1319 DI_a199_understeerdMzActive "Drive inverter: a199 understeerd mz active";
CM_ SG_ 1319 DI_a199_vdcMode "Drive inverter: a199 vdc mode";
CM_ SG_ 1319 DI_a200_MBPCheckStatus "Drive inverter: a200 MBP check status";
CM_ SG_ 1319 DI_a200_MBPFailedCase "Drive inverter: a200 MBP failed case";
CM_ SG_ 1319 DI_a200_MBPFaultProbability "Drive inverter: a200 MBP fault probability";
CM_ SG_ 1319 DI_a202_reason "Drive inverter: a202 reason";
CM_ SG_ 1319 DI_a202_movement "Drive inverter: a202 movement";
CM_ SG_ 1319 DI_a202_sysStateExitCondition "Drive inverter: a202 sys state exit condition";
CM_ SG_ 1319 DI_a203_ptcStateLocal "Drive inverter: a203 ptc state local";
CM_ SG_ 1319 DI_a203_btcState "Drive inverter: a203 btc state";
CM_ SG_ 1319 DI_a204_longAccel "Drive inverter: a204 long accel";
CM_ SG_ 1319 DI_a204_longAccelLastVal "Drive inverter: a204 long accel last val";
CM_ SG_ 1319 DI_a204_longAccelCurrVal "Drive inverter: a204 long accel curr val";
CM_ SG_ 1319 DI_a204_rollRate "Drive inverter: a204 roll rate";
CM_ SG_ 1319 DI_a204_rollRateLastVal "Drive inverter: a204 roll rate last val";
CM_ SG_ 1319 DI_a204_rollRateCurrVal "Drive inverter: a204 roll rate curr val";
CM_ SG_ 1319 DI_a205_latAccel "Drive inverter: a205 lat accel";
CM_ SG_ 1319 DI_a205_latAccelLastVal "Drive inverter: a205 lat accel last val";
CM_ SG_ 1319 DI_a205_latAccelCurrVal "Drive inverter: a205 lat accel curr val";
CM_ SG_ 1319 DI_a205_pitchRate "Drive inverter: a205 pitch rate";
CM_ SG_ 1319 DI_a205_pitchRateLastVal "Drive inverter: a205 pitch rate last val";
CM_ SG_ 1319 DI_a205_pitchRateCurrVal "Drive inverter: a205 pitch rate curr val";
CM_ SG_ 1319 DI_a206_verticalAccel "Drive inverter: a206 vertical accel";
CM_ SG_ 1319 DI_a206_verticalAccelLastVal "Drive inverter: a206 vertical accel last val";
CM_ SG_ 1319 DI_a206_verticalAccelCurrVal "Drive inverter: a206 vertical accel curr val";
CM_ SG_ 1319 DI_a206_yawRate "Drive inverter: a206 yaw rate";
CM_ SG_ 1319 DI_a206_yawRateLastVal "Drive inverter: a206 yaw rate last val";
CM_ SG_ 1319 DI_a206_yawRateCurrVal "Drive inverter: a206 yaw rate curr val";
CM_ SG_ 1319 DI_a210_ptcStateGlobal "Drive inverter: a210 ptc state global";
CM_ SG_ 1319 DI_a210_espActuatorState "Drive inverter: a210 esp actuator state";
CM_ SG_ 1319 DI_a210_brakeTmpEstStateFaulted "Drive inverter: a210 brake tmp est state faulted";
CM_ SG_ 1319 DI_a210_secondaryBrakeActuatorIs "Drive inverter: a210 secondary brake actuator is master";
CM_ SG_ 1319 DI_a223_ptcStateLocal "Drive inverter: a223 ptc state local";
CM_ SG_ 1319 DI_a223_btcState "Drive inverter: a223 btc state";
CM_ SG_ 1319 DI_a223_velocityEstimatorState "Drive inverter: a223 velocity estimator state";
CM_ SG_ 1319 DI_a223_addState_dir "Drive inverter: a223 add state dir";
CM_ SG_ 1319 DI_a223_addState_dif "Drive inverter: a223 add state dif";
CM_ SG_ 1319 DI_a223_DI_tractionControlMode "Drive inverter: a223 DI traction control mode";
CM_ SG_ 1319 DI_a223_UI_tractionControlMode "Drive inverter: a223 UI traction control mode";
CM_ SG_ 1319 DI_a223_vehicleVelocity "Drive inverter: a223 vehicle velocity";
CM_ SG_ 1319 DI_a223_musurf "Drive inverter: a223 musurf";
CM_ SG_ 1319 DI_a223_musurfHigh "Drive inverter: a223 musurf high";
CM_ SG_ 1319 DI_a223_driveTCActive "Drive inverter: a223 drive TC active";
CM_ SG_ 1319 DI_a223_regenTCActive "Drive inverter: a223 regen TC active";
CM_ SG_ 1319 DI_a223_surfaceUtility "Drive inverter: a223 surface utility";
CM_ SG_ 1319 DI_a224_brakeFLTemp "Drive inverter: a224 brake FL temp";
CM_ SG_ 1319 DI_a224_brakeFRTemp "Drive inverter: a224 brake FR temp";
CM_ SG_ 1319 DI_a224_brakeRLTemp "Drive inverter: a224 brake RL temp";
CM_ SG_ 1319 DI_a224_brakeRRTemp "Drive inverter: a224 brake RR temp";
CM_ SG_ 1319 DI_a227_hvState "Drive inverter: a227 hv state";
CM_ SG_ 1319 DI_a227_vehiclePowerState "Drive inverter: a227 vehicle power state";
CM_ SG_ 1319 DI_a230_CMP_HVStatus "Drive inverter: a230 CMP HV status";
CM_ SG_ 1319 DI_a230_CMPD_state "Drive inverter: a230 CMPD state";
CM_ SG_ 1319 DI_a232_velocityEstimatorState "Drive inverter: a232 velocity estimator state";
CM_ SG_ 1319 DI_a232_UI_tractionControlMode "Drive inverter: a232 UI traction control mode";
CM_ SG_ 1319 DI_a232_vehicleVelocity "Drive inverter: a232 vehicle velocity";
CM_ SG_ 1319 DI_a232_musurf "Drive inverter: a232 musurf";
CM_ SG_ 1319 DI_a232_musurfHigh "Drive inverter: a232 musurf high";
CM_ SG_ 1319 DI_a232_allWhlSpeedRotationAvail "Drive inverter: a232 all whl speed rotation avail";
CM_ SG_ 1319 DI_a232_BrakeMasterCylPressValid "Drive inverter: a232 brake master cyl press valid";
CM_ SG_ 1319 DI_a232_WheelBrakeTorquesValid "Drive inverter: a232 wheel brake torques valid";
CM_ SG_ 1319 DI_a232_AbsBrakeEventActiveValid "Drive inverter: a232 abs brake event active valid";
CM_ SG_ 1319 DI_a232_UndersteerActiveValid "Drive inverter: a232 understeer active valid";
CM_ SG_ 1319 DI_a232_OversteerActiveValid "Drive inverter: a232 oversteer active valid";
CM_ SG_ 1319 DI_a232_allMotorTorquesValid "Drive inverter: a232 all motor torques valid";
CM_ SG_ 1319 DI_a232_lateralAccelValid "Drive inverter: a232 lateral accel valid";
CM_ SG_ 1319 DI_a232_longitudinalAccelValid "Drive inverter: a232 longitudinal accel valid";
CM_ SG_ 1319 DI_a232_yawRateValid "Drive inverter: a232 yaw rate valid";
CM_ SG_ 1319 DI_a232_steerAngleValid "Drive inverter: a232 steer angle valid";
CM_ SG_ 1319 DI_a236_states "Drive inverter: a236 states";
CM_ SG_ 1319 DI_a237_lateralAccel "Drive inverter: a237 lateral accel";
CM_ SG_ 1319 DI_a237_verticalAccel "Drive inverter: a237 vertical accel";
CM_ SG_ 1319 DI_a237_longitudinalAccel "Drive inverter: a237 longitudinal accel";
CM_ SG_ 1319 DI_a237_vehicleSpeed "Drive inverter: a237 vehicle speed";
CM_ SG_ 1319 DI_a239_numRequests "Drive inverter: a239 num requests";
CM_ SG_ 1319 DI_a243_RCU_status "Drive inverter: a243 RCU status";
CM_ SG_ 1319 DI_a243_RCU_actuation "Drive inverter: a243 RCU actuation";
CM_ SG_ 1319 DI_a245_ebrStatus "Drive inverter: a245 ebr status";
CM_ SG_ 1319 DI_a245_vehicleHoldState "Drive inverter: a245 vehicle hold state";
CM_ SG_ 1319 DI_a246_onePedalDrivingState "Drive inverter: a246 one pedal driving state";
CM_ SG_ 1319 DI_a246_opdUnavailableReason "Drive inverter: a246 opd unavailable reason";
CM_ SG_ 1319 DI_a249_learning_DIF "Drive inverter: a249 learning DIF";
CM_ SG_ 1319 DI_a249_learning_DIR "Drive inverter: a249 learning DIR";
CM_ SG_ 1319 DI_a250_tasRequest "Drive inverter: a250 tas request";
CM_ SG_ 1319 DI_a250_tasMIA "Drive inverter: a250 tas MIA";
CM_ BO_ 871 "Drive inverter message: alert matrix";
CM_ SG_ 871 DI_matrixIndex "Drive inverter: matrix index";
CM_ SG_ 871 DI_a001_frunkSpeedLimitActive "Drive inverter: a001 frunk speed limit active";
CM_ SG_ 871 DI_a002_parkButtonDuringStalkReq "Drive inverter: a002 park button during stalk req";
CM_ SG_ 871 DI_a003_suggestedGearOverride "Drive inverter: a003 suggested gear override";
CM_ SG_ 871 DI_a004_smartShiftUnavailable "Drive inverter: a004 smart shift unavailable";
CM_ SG_ 871 DI_a005_stalkPanicked "Drive inverter: a005 stalk panicked";
CM_ SG_ 871 DI_a006_shifterUnavailable "Drive inverter: a006 shifter unavailable";
CM_ SG_ 871 DI_a007_secGearSelButtonStuck "Drive inverter: a007 sec gear sel button stuck";
CM_ SG_ 871 DI_a010_unintendedReset "Drive inverter: a010 unintended reset";
CM_ SG_ 871 DI_a012_accel5VSupply "Drive inverter: a012 accel5 v supply";
CM_ SG_ 871 DI_a013_eccError "Drive inverter: a013 ecc error";
CM_ SG_ 871 DI_a014_secGearSelActivated "Drive inverter: a014 sec gear sel activated";
CM_ SG_ 871 DI_a015_immobilizer "Drive inverter: a015 immobilizer";
CM_ SG_ 871 DI_a016_parkRequestByPM "Drive inverter: a016 park request by PM";
CM_ SG_ 871 DI_a017_hwPedalMonitor "Drive inverter: a017 hw pedal monitor";
CM_ SG_ 871 DI_a018_hwLVSupplyUV "Drive inverter: a018 hw LV supply UV";
CM_ SG_ 871 DI_a019_hwAccelPedalPower "Drive inverter: a019 hw accel pedal power";
CM_ SG_ 871 DI_a020_systemHvilNotClosed "Drive inverter: a020 system hvil not closed";
CM_ SG_ 871 DI_a021_packOvervoltage "Drive inverter: a021 pack overvoltage";
CM_ SG_ 871 DI_a022_hw5vSupplyUV "Drive inverter: a022 hw5v supply UV";
CM_ SG_ 871 DI_a023_carNotParked "Drive inverter: a023 car not parked";
CM_ SG_ 871 DI_a024_holdNForNeutral "Drive inverter: a024 hold n for neutral";
CM_ SG_ 871 DI_a025_regenBackfillUnavailable "Drive inverter: a025 regen backfill unavailable";
CM_ SG_ 871 DI_a026_parkPressedWithHighAPeda "Drive inverter: a026 park pressed with high a pedal";
CM_ SG_ 871 DI_a027_steeringAngleOffsetServi "Drive inverter: a027 steering angle offset service";
CM_ SG_ 871 DI_a028_secondaryShifterMuted "Drive inverter: a028 secondary shifter muted";
CM_ SG_ 871 DI_a031_closureAccelerationLimit "Drive inverter: a031 closure acceleration limit";
CM_ SG_ 871 DI_a036_sysStandbyUnitLimitedWai "Drive inverter: a036 sys standby unit limited wait";
CM_ SG_ 871 DI_a039_exceptionUndefinedInstru "Drive inverter: a039 exception undefined instruction";
CM_ SG_ 871 DI_a040_difMIA "Drive inverter: a040 dif MIA";
CM_ SG_ 871 DI_a041_driverBrakeApplyStuck "Drive inverter: a041 driver brake apply stuck";
CM_ SG_ 871 DI_a042_pmfMIA "Drive inverter: a042 pmf MIA";
CM_ SG_ 871 DI_a043_pmrMIA "Drive inverter: a043 pmr MIA";
CM_ SG_ 871 DI_d047_interfacePowerSupplyIssu "Drive inverter: d047 interface power supply issue";
CM_ SG_ 871 DI_a048_ecuLogAvailable "Drive inverter: a048 ecu log available";
CM_ SG_ 871 DI_d049_invalidOdometerReading "Drive inverter: d049 invalid odometer reading";
CM_ SG_ 871 DI_d050_interfaceUnitCommunicati "Drive inverter: d050 interface unit communication issue";
CM_ SG_ 871 DI_a051_batteryOvercurrent "Drive inverter: a051 battery overcurrent";
CM_ SG_ 871 DI_a052_dirMIA "Drive inverter: a052 dir MIA";
CM_ SG_ 871 DI_a053_canDataBusC "Drive inverter: a053 can data bus c";
CM_ SG_ 871 DI_a054_canOverrunBusC "Drive inverter: a054 can overrun bus c";
CM_ SG_ 871 DI_a055_canHardwareBusC "Drive inverter: a055 can hardware bus c";
CM_ SG_ 871 DI_a056_canDataBusD "Drive inverter: a056 can data bus d";
CM_ SG_ 871 DI_a057_canOverrunBusD "Drive inverter: a057 can overrun bus d";
CM_ SG_ 871 DI_a058_canHardwareBusD "Drive inverter: a058 can hardware bus d";
CM_ SG_ 871 DI_a059_canDataBusE "Drive inverter: a059 can data bus e";
CM_ SG_ 871 DI_a060_canOverrunBusE "Drive inverter: a060 can overrun bus e";
CM_ SG_ 871 DI_a061_canHardwareBusE "Drive inverter: a061 can hardware bus e";
CM_ SG_ 871 DI_a062_systemLimpMode "Drive inverter: a062 system limp mode";
CM_ SG_ 871 DI_a063_systemGracefulPowerOff "Drive inverter: a063 system graceful power off";
CM_ SG_ 871 DI_a064_pmsrmUnitMiaWithHvDown "Drive inverter: a064 pmsrm unit mia with hv down";
CM_ SG_ 871 DI_a065_canHardwareBusB "Drive inverter: a065 can hardware bus b";
CM_ SG_ 871 DI_a066_canDataBusB "Drive inverter: a066 can data bus b";
CM_ SG_ 871 DI_a067_canOverrunBusB "Drive inverter: a067 can overrun bus b";
CM_ SG_ 871 DI_a068_secondaryWheelSpeedIrrat "Drive inverter: a068 secondary wheel speed irrational";
CM_ SG_ 871 DI_a070_udsTransactionInitiated "Drive inverter: a070 uds transaction initiated";
CM_ SG_ 871 DI_d072_accelPedalSensorIssue "Drive inverter: d072 accel pedal sensor issue";
CM_ SG_ 871 DI_d073_accelPedalVoltSupplyIssu "Drive inverter: d073 accel pedal volt supply issue";
CM_ SG_ 871 DI_a074_unintendedResetAutoshift "Drive inverter: a074 unintended reset autoshift";
CM_ SG_ 871 DI_d075_incorrectImmobilizerKey "Drive inverter: d075 incorrect immobilizer key";
CM_ SG_ 871 DI_a076_lvSupplyOV "Drive inverter: a076 lv supply OV";
CM_ SG_ 871 DI_a077_lvSupplyUV "Drive inverter: a077 lv supply UV";
CM_ SG_ 871 DI_a078_adcRefLow "Drive inverter: a078 adc ref low";
CM_ SG_ 871 DI_a079_adcRefHigh "Drive inverter: a079 adc ref high";
CM_ SG_ 871 DI_a080_accelSynch "Drive inverter: a080 accel synch";
CM_ SG_ 871 DI_a081_accelTrack1 "Drive inverter: a081 accel track1";
CM_ SG_ 871 DI_a082_accelTrack2 "Drive inverter: a082 accel track2";
CM_ SG_ 871 DI_a083_brakePedalSensor "Drive inverter: a083 brake pedal sensor";
CM_ SG_ 871 DI_a084_eccTestData0 "Drive inverter: a084 ecc test data0";
CM_ SG_ 871 DI_a085_proximityInEnable "Drive inverter: a085 proximity in enable";
CM_ SG_ 871 DI_a086_dpbMIA "Drive inverter: a086 dpb MIA";
CM_ SG_ 871 DI_a087_gtwMIA "Drive inverter: a087 gtw MIA";
CM_ SG_ 871 DI_a088_uiMIA "Drive inverter: a088 ui MIA";
CM_ SG_ 871 DI_a089_sccmMIA "Drive inverter: a089 sccm MIA";
CM_ SG_ 871 DI_a090_pmMIA "Drive inverter: a090 pm MIA";
CM_ SG_ 871 DI_a091_espMIA "Drive inverter: a091 esp MIA";
CM_ SG_ 871 DI_a092_bmsMIA "Drive inverter: a092 bms MIA";
CM_ SG_ 871 DI_a093_canHardwareBusA "Drive inverter: a093 can hardware bus a";
CM_ SG_ 871 DI_a094_canDataBusA "Drive inverter: a094 can data bus a";
CM_ SG_ 871 DI_a095_canOverrunBusA "Drive inverter: a095 can overrun bus a";
CM_ SG_ 871 DI_a096_memoryError "Drive inverter: a096 memory error";
CM_ SG_ 871 DI_a097_eepromError "Drive inverter: a097 eeprom error";
CM_ SG_ 871 DI_a098_eepromManagerError "Drive inverter: a098 eeprom manager error";
CM_ SG_ 871 DI_a099_threadOverrun "Drive inverter: a099 thread overrun";
CM_ SG_ 871 DI_a100_nvramError "Drive inverter: a100 nvram error";
CM_ SG_ 871 DI_a101_eccTestData1 "Drive inverter: a101 ecc test data1";
CM_ SG_ 871 DI_a102_exceptionPrefetchAbort "Drive inverter: a102 exception prefetch abort";
CM_ SG_ 871 DI_a103_bbMIA "Drive inverter: a103 bb MIA";
CM_ SG_ 871 DI_a104_proximityIrrational "Drive inverter: a104 proximity irrational";
CM_ SG_ 871 DI_a105_cpMIA "Drive inverter: a105 cp MIA";
CM_ SG_ 871 DI_a106_idleTaskStarving "Drive inverter: a106 idle task starving";
CM_ SG_ 871 DI_a107_idbBrakeCircuitPressureO "Drive inverter: a107 idb brake circuit pressure offset suspect";
CM_ SG_ 871 DI_a108_appMIA "Drive inverter: a108 app MIA";
CM_ SG_ 871 DI_a109_ahbWriteError "Drive inverter: a109 ahb write error";
CM_ SG_ 871 DI_a110_brakeMIA "Drive inverter: a110 brake MIA";
CM_ SG_ 871 DI_a111_idbMIA "Drive inverter: a111 idb MIA";
CM_ SG_ 871 DI_a112_accelTrack1Incons "Drive inverter: a112 accel track1 incons";
CM_ SG_ 871 DI_a113_lowBrakeMCPressure "Drive inverter: a113 low brake MC pressure";
CM_ SG_ 871 DI_a114_exceptionDataAbort "Drive inverter: a114 exception data abort";
CM_ SG_ 871 DI_a115_exceptionDataAbort2 "Drive inverter: a115 exception data abort2";
CM_ SG_ 871 DI_a116_motorRecovered "Drive inverter: a116 motor recovered";
CM_ SG_ 871 DI_a117_latentFaultCheckTripped "Drive inverter: a117 latent fault check tripped";
CM_ SG_ 871 DI_a118_diImmobilizedForFactoryF "Drive inverter: a118 di immobilized for factory failsafe";
CM_ SG_ 871 DI_a119_latentFaultCheckFailedOn "Drive inverter: a119 latent fault check failed once";
CM_ SG_ 871 DI_a120_regenBlendingUnavailable "Drive inverter: a120 regen blending unavailable";
CM_ SG_ 871 DI_a121_qualifiedBrakeEventMitig "Drive inverter: a121 qualified brake event mitigation";
CM_ SG_ 871 DI_a122_highStackUsage "Drive inverter: a122 high stack usage";
CM_ SG_ 871 DI_a124_cruiseFault "Drive inverter: a124 cruise fault";
CM_ SG_ 871 DI_a125_noBatteryPower "Drive inverter: a125 no battery power";
CM_ SG_ 871 DI_a129_epbNotApplied "Drive inverter: a129 epb not applied";
CM_ SG_ 871 DI_a130_aebFault "Drive inverter: a130 aeb fault";
CM_ SG_ 871 DI_a131_highSpeedWearLimit "Drive inverter: a131 high speed wear limit";
CM_ SG_ 871 DI_a133_vehicleHoldTimedOut "Drive inverter: a133 vehicle hold timed out";
CM_ SG_ 871 DI_a134_wheelSpeedIrrational "Drive inverter: a134 wheel speed irrational";
CM_ SG_ 871 DI_a135_vehicleHoldFault "Drive inverter: a135 vehicle hold fault";
CM_ SG_ 871 DI_a137_noCapableDriveUnits "Drive inverter: a137 no capable drive units";
CM_ SG_ 871 DI_a138_frontUnitDisabled "Drive inverter: a138 front unit disabled";
CM_ SG_ 871 DI_a139_rearUnitDisabled "Drive inverter: a139 rear unit disabled";
CM_ SG_ 871 DI_a140_ptcMIA "Drive inverter: a140 ptc MIA";
CM_ SG_ 871 DI_a141_dasMIA "Drive inverter: a141 das MIA";
CM_ SG_ 871 DI_a142_potholeDetected "Drive inverter: a142 pothole detected";
CM_ SG_ 871 DI_a143_mcuLimitActive "Drive inverter: a143 mcu limit active";
CM_ SG_ 871 DI_a144_configMismatch "Drive inverter: a144 config mismatch";
CM_ SG_ 871 DI_a146_pbrkPanicEpbFault "Drive inverter: a146 pbrk panic epb fault";
CM_ SG_ 871 DI_a154_vdcRearSteering "Drive inverter: a154 vdc rear steering";
CM_ SG_ 871 DI_a155_vcfrontMIA "Drive inverter: a155 vcfront MIA";
CM_ SG_ 871 DI_a157_rcmMIA "Drive inverter: a157 rcm MIA";
CM_ SG_ 871 DI_a158_ibstMIA "Drive inverter: a158 ibst MIA";
CM_ SG_ 871 DI_a159_cruiseSelfCheck "Drive inverter: a159 cruise self check";
CM_ SG_ 871 DI_a160_fastLearnComplete "Drive inverter: a160 fast learn complete";
CM_ SG_ 871 DI_a161_epas3pMIA "Drive inverter: a161 epas3p MIA";
CM_ SG_ 871 DI_a162_shiftDenied "Drive inverter: a162 shift denied";
CM_ SG_ 871 DI_a163_shiftMotorSpeed "Drive inverter: a163 shift motor speed";
CM_ SG_ 871 DI_a164_brakeOverride "Drive inverter: a164 brake override";
CM_ SG_ 871 DI_a165_cruiseCancelled "Drive inverter: a165 cruise cancelled";
CM_ SG_ 871 DI_a166_driverLeft "Drive inverter: a166 driver left";
CM_ SG_ 871 DI_a167_keyNotAuthenticated "Drive inverter: a167 key not authenticated";
CM_ SG_ 871 DI_a168_proximityDriveDenial "Drive inverter: a168 proximity drive denial";
CM_ SG_ 871 DI_a169_regenOffOverride "Drive inverter: a169 regen off override";
CM_ SG_ 871 DI_a170_tireConfigUpdated "Drive inverter: a170 tire config updated";
CM_ SG_ 871 DI_a171_driveRailNotRequested "Drive inverter: a171 drive rail not requested";
CM_ SG_ 871 DI_a172_accelPressedInNP "Drive inverter: a172 accel pressed in NP";
CM_ SG_ 871 DI_a173_bothPedalsPressed "Drive inverter: a173 both pedals pressed";
CM_ SG_ 871 DI_a174_notOkToStartDrive "Drive inverter: a174 not ok to start drive";
CM_ SG_ 871 DI_a175_crsNotAvailable "Drive inverter: a175 crs not available";
CM_ SG_ 871 DI_a176_EBRreleased "Drive inverter: a176 EB rreleased";
CM_ SG_ 871 DI_a177_tireFitmentChanged "Drive inverter: a177 tire fitment changed";
CM_ SG_ 871 DI_a178_steeringAngleOffsetFault "Drive inverter: a178 steering angle offset fault";
CM_ SG_ 871 DI_a179_steeringAngleOffsetWarni "Drive inverter: a179 steering angle offset warning";
CM_ SG_ 871 DI_a180_crsSeatbeltUnbuckled "Drive inverter: a180 crs seatbelt unbuckled";
CM_ SG_ 871 DI_a181_rearMotorMode "Drive inverter: a181 rear motor mode";
CM_ SG_ 871 DI_a182_frontMotorMode "Drive inverter: a182 front motor mode";
CM_ SG_ 871 DI_a183_holdReleaseRqrd "Drive inverter: a183 hold release rqrd";
CM_ SG_ 871 DI_a184_autoparkCanceled "Drive inverter: a184 autopark canceled";
CM_ SG_ 871 DI_a185_autoparkAborted "Drive inverter: a185 autopark aborted";
CM_ SG_ 871 DI_a186_brakeStand "Drive inverter: a186 brake stand";
CM_ SG_ 871 DI_a187_pedalMisapplication "Drive inverter: a187 pedal misapplication";
CM_ SG_ 871 DI_a188_tireRotationRecommendedG "Drive inverter: a188 tire rotation recommended ghosted";
CM_ SG_ 871 DI_a189_garageShiftWithPedal "Drive inverter: a189 garage shift with pedal";
CM_ SG_ 871 DI_a190_tireRotationRecommended "Drive inverter: a190 tire rotation recommended";
CM_ SG_ 871 DI_a191_brakeShiftReq "Drive inverter: a191 brake shift req";
CM_ SG_ 871 DI_a192_invalidOdometer "Drive inverter: a192 invalid odometer";
CM_ SG_ 871 DI_a193_vdcBrakeTorqueFr "Drive inverter: a193 vdc brake torque fr";
CM_ SG_ 871 DI_a194_vdcBrakeTorqueRe "Drive inverter: a194 vdc brake torque re";
CM_ SG_ 871 DI_a195_vdcEspSlipFr "Drive inverter: a195 vdc esp slip fr";
CM_ SG_ 871 DI_a196_vdcEspSlipRe "Drive inverter: a196 vdc esp slip re";
CM_ SG_ 871 DI_a197_vdcEspWheelSaturations "Drive inverter: a197 vdc esp wheel saturations";
CM_ SG_ 871 DI_a198_vdcEspMCPressAndSteering "Drive inverter: a198 vdc esp MC press and steering";
CM_ SG_ 871 DI_a199_vdcFaulted "Drive inverter: a199 vdc faulted";
CM_ SG_ 871 DI_a200_vdcModelBasedPlausibilit "Drive inverter: a200 vdc model based plausibility";
CM_ SG_ 871 DI_a201_decelTorqueLimited "Drive inverter: a201 decel torque limited";
CM_ SG_ 871 DI_a202_excessHeatUnavailable "Drive inverter: a202 excess heat unavailable";
CM_ SG_ 871 DI_a203_TCReducedByADD "Drive inverter: a203 TC reduced by ADD";
CM_ SG_ 871 DI_a204_vdcRcmLongitudinal "Drive inverter: a204 vdc rcm longitudinal";
CM_ SG_ 871 DI_a205_vdcRcmLateral "Drive inverter: a205 vdc rcm lateral";
CM_ SG_ 871 DI_a206_vdcRcmVertical "Drive inverter: a206 vdc rcm vertical";
CM_ SG_ 871 DI_a207_vdcPowertrainTorque_dif "Drive inverter: a207 vdc powertrain torque dif";
CM_ SG_ 871 DI_a208_vdcPowertrainTorque_dir "Drive inverter: a208 vdc powertrain torque dir";
CM_ SG_ 871 DI_a210_vdcOtherControllerStates "Drive inverter: a210 vdc other controller states";
CM_ SG_ 871 DI_a211_vdcMotorSpeed_dif "Drive inverter: a211 vdc motor speed dif";
CM_ SG_ 871 DI_a212_vdcWheelRotations "Drive inverter: a212 vdc wheel rotations";
CM_ SG_ 871 DI_a213_lowMuProbabilityChange "Drive inverter: a213 low mu probability change";
CM_ SG_ 871 DI_a214_vdcWheelSpeedFr "Drive inverter: a214 vdc wheel speed fr";
CM_ SG_ 871 DI_a215_vdcWheelSpeedRe "Drive inverter: a215 vdc wheel speed re";
CM_ SG_ 871 DI_a216_vdcMBPAlmostTripped "Drive inverter: a216 vdc MBP almost tripped";
CM_ SG_ 871 DI_a217_vdcOutputIrrational "Drive inverter: a217 vdc output irrational";
CM_ SG_ 871 DI_a218_vdcOSPreControlActive "Drive inverter: a218 vdc OS pre control active";
CM_ SG_ 871 DI_a219_vdcOversteerdMzActive "Drive inverter: a219 vdc oversteerd mz active";
CM_ SG_ 871 DI_a220_vdcUndersteerDecelActive "Drive inverter: a220 vdc understeer decel active";
CM_ SG_ 871 DI_a221_vdcUndersteerdMzActive "Drive inverter: a221 vdc understeerd mz active";
CM_ SG_ 871 DI_a222_vdcDisabled "Drive inverter: a222 vdc disabled";
CM_ SG_ 871 DI_a223_tractionControlDisabled "Drive inverter: a223 traction control disabled";
CM_ SG_ 871 DI_a224_brakeOverTemp "Drive inverter: a224 brake over temp";
CM_ SG_ 871 DI_a225_vyEstimatorDegradedDebug "Drive inverter: a225 vy estimator degraded debug";
CM_ SG_ 871 DI_a226_sysStartConditionNotMet "Drive inverter: a226 sys start condition not met";
CM_ SG_ 871 DI_a227_contactorsNotClosed "Drive inverter: a227 contactors not closed";
CM_ SG_ 871 DI_a228_brakeTempEstUnavailable "Drive inverter: a228 brake temp est unavailable";
CM_ SG_ 871 DI_a230_cmpMIA "Drive inverter: a230 cmp MIA";
CM_ SG_ 871 DI_a231_softSystemLimpMode "Drive inverter: a231 soft system limp mode";
CM_ SG_ 871 DI_a232_velocityEstimatorDegrade "Drive inverter: a232 velocity estimator degraded";
CM_ SG_ 871 DI_a233_frontWheelImpactDetected "Drive inverter: a233 front wheel impact detected";
CM_ SG_ 871 DI_a235_trackModeActive "Drive inverter: a235 track mode active";
CM_ SG_ 871 DI_a236_tasMIA "Drive inverter: a236 tas MIA";
CM_ SG_ 871 DI_a237_undersideAbuse "Drive inverter: a237 underside abuse";
CM_ SG_ 871 DI_a238_secondaryCollisionMitiga "Drive inverter: a238 secondary collision mitigation active";
CM_ SG_ 871 DI_a239_neutralRequestByPM "Drive inverter: a239 neutral request by PM";
CM_ SG_ 871 DI_a240_torqueSplitStuck "Drive inverter: a240 torque split stuck";
CM_ SG_ 871 DI_a241_vdcMotorSpeed_dir "Drive inverter: a241 vdc motor speed dir";
CM_ SG_ 871 DI_a242_vdcTrailerSwayDetected "Drive inverter: a242 vdc trailer sway detected";
CM_ SG_ 871 DI_a243_rcuMIA "Drive inverter: a243 rcu MIA";
CM_ SG_ 871 DI_a244_vseRLSMassMismatch "Drive inverter: a244 vse RLS mass mismatch";
CM_ SG_ 871 DI_a245_opdReducedWithoutEbr "Drive inverter: a245 opd reduced without ebr";
CM_ SG_ 871 DI_a246_opdUnavailable "Drive inverter: a246 opd unavailable";
CM_ SG_ 871 DI_a248_vdcPreControlHighDynamic "Drive inverter: a248 vdc pre control high dynamic active";
CM_ SG_ 871 DI_a249_spinDownLearningInProgre "Drive inverter: a249 spin down learning in progress";
CM_ SG_ 871 DI_a250_tasSpeedLimitActive "Drive inverter: a250 tas speed limit active";
CM_ SG_ 871 DI_a251_diPowerOnStateMismatch "Drive inverter: a251 di power on state mismatch";
CM_ SG_ 871 DI_a253_accelSynchWarn "Drive inverter: a253 accel synch warn";
CM_ SG_ 871 DI_a254_vehicleStuckDetected "Drive inverter: a254 vehicle stuck detected";
CM_ SG_ 871 DI_a255_manualRecoveryMode "Drive inverter: a255 manual recovery mode";
CM_ BO_ 84 "Drive inverter message: autonomy health";
CM_ SG_ 84 DI_ah_vehicleSpeedLimit "Drive inverter: ah vehicle speed limit";
CM_ SG_ 84 DI_ah_vehicleReverseSpeedLimit "Drive inverter: ah vehicle reverse speed limit";
CM_ SG_ 84 DI_autonomyBehavior "Drive inverter: autonomy behavior";
CM_ SG_ 84 DI_ah_vehicleNoGradeAccelMax "Drive inverter: ah vehicle no grade accel max";
CM_ SG_ 84 DI_ah_vehicleNoGradeDecelMax "Drive inverter: ah vehicle no grade decel max";
CM_ SG_ 84 DI_ah_timeToNoPropulsion "Drive inverter: ah time to no propulsion";
CM_ SG_ 84 DI_ah_dGearAvailable "Drive inverter: ah d gear available";
CM_ SG_ 84 DI_ah_rGearAvailable "Drive inverter: ah r gear available";
CM_ SG_ 84 DI_ah_pGearAvailable "Drive inverter: ah p gear available";
CM_ SG_ 84 DI_loncDegradedAvailable "Drive inverter: lonc degraded available";
CM_ SG_ 84 DI_loncSuppressCancelModeAvailab "Drive inverter: lonc suppress cancel mode available";
CM_ SG_ 84 DI_loncDegradedReason "Drive inverter: lonc degraded reason";
CM_ SG_ 84 DI_opdAvailableForPedalInterface "Drive inverter: opd available for pedal interface";
CM_ SG_ 84 DI_epbUnavailable "Drive inverter: epb unavailable";
CM_ SG_ 84 DI_loncInPreFaultStopping "Drive inverter: lonc in pre fault stopping";
CM_ BO_ 328 "Drive inverter message: chassis control";
CM_ SG_ 328 DI_chassisControlChecksum "Drive inverter: chassis control checksum";
CM_ SG_ 328 DI_chassisControlCounter "Drive inverter: chassis control counter";
CM_ SG_ 328 DI_imuOffsetLearnRequest "Drive inverter: imu offset learn request";
CM_ SG_ 328 DI_brakeCommandType "Drive inverter: brake command type";
CM_ SG_ 328 DI_brakeTorqueRequestActive "Drive inverter: brake torque request active";
CM_ SG_ 328 DI_brakeTorqueCommand "Brake torque command to ESP";
CM_ SG_ 328 DI_ptcStateGlobal "Indicates state of Tesla traction control system";
CM_ SG_ 328 DI_ptcActive "TRUE when pedal-positive (drive) traction control is active";
CM_ SG_ 328 DI_vdcState "Status of VDC";
CM_ SG_ 328 DI_isAnyVdcControlActive "Drive inverter: is any vdc control active";
CM_ SG_ 328 DI_vdcMode "Indicates mode of VDC";
CM_ SG_ 328 DI_pedalAssistCurveSelect "Drive inverter: pedal assist curve select";
CM_ SG_ 328 DI_isAnyTcActive "TRUE when either drive or regen traction control is active";
CM_ SG_ 328 DI_VehicleMuConfidence "Confidence in surface mu estimate for development use only";
CM_ SG_ 328 DI_VehicleMu "Learn-up estimate of surface mu for development use only";
CM_ SG_ 328 DI_trailerSwayIndex "VDC trailer sway index";
CM_ SG_ 328 DI_vdcControlActive "Type of VDC control while VDC is actuating";
CM_ SG_ 328 DI_treadDepthAlertSet "Drive inverter: tread depth alert set";
CM_ BO_ 1861 "Drive inverter message: chassis control2";
CM_ SG_ 1861 DI_gradeAngle "Reports the grade angle.";
CM_ SG_ 1861 DI_bankAngle "Reports the bank angle.";
CM_ SG_ 1861 DI_chassisControlVideoRequest "Drive inverter: chassis control video request";
CM_ SG_ 1861 DI_eepDeliveryBitStatus "Drive inverter: eep delivery bit status";
CM_ SG_ 1861 DI_tireUtilizationRatioFrL "Drive inverter: tire utilization ratio fr l";
CM_ SG_ 1861 DI_tireUtilizationRatioFrR "Drive inverter: tire utilization ratio fr r";
CM_ SG_ 1861 DI_tireUtilizationRatioReL "Drive inverter: tire utilization ratio re l";
CM_ SG_ 1861 DI_tireUtilizationRatioReR "Drive inverter: tire utilization ratio re r";
CM_ SG_ 1861 DI_counterSteerTarget "Drive inverter: counter steer target";
CM_ SG_ 1861 DI_splitMuProbability "Drive inverter: split mu probability";
CM_ SG_ 1861 DI_mzError "Drive inverter: mz error";
CM_ SG_ 1861 DI_slipDifferenceFrontRear "Drive inverter: slip difference front rear";
CM_ SG_ 1861 DI_highFreqYawRate "Drive inverter: high freq yaw rate";
CM_ SG_ 1861 DI_turnDirection "Drive inverter: turn direction";
CM_ SG_ 1861 DI_absolutePreControlRequest "Drive inverter: absolute pre control request";
CM_ SG_ 1861 DI_oppositeBuildDirFrontAxle "Drive inverter: opposite build dir front axle";
CM_ SG_ 1861 DI_oppositeBuildDirRearAxle "Drive inverter: opposite build dir rear axle";
CM_ SG_ 1861 DI_saturatedEffectiveness "Drive inverter: saturated effectiveness";
CM_ SG_ 1861 DI_driverPanicIndex "Drive inverter: driver panic index";
CM_ SG_ 1861 DI_learnDownMu "Drive inverter: learn down mu";
CM_ SG_ 1861 DI_preControlOpposingTurnDir "Drive inverter: pre control opposing turn dir";
CM_ SG_ 1861 DI_driverFxError "Drive inverter: driver fx error";
CM_ SG_ 1861 DI_targetSaturation "Drive inverter: target saturation";
CM_ BO_ 1869 "Drive inverter message: chassis control3";
CM_ SG_ 1869 DI_tireWearFactor_FrL "Drive inverter: tire wear factor fr l";
CM_ SG_ 1869 DI_tireWearFactor_FrR "Drive inverter: tire wear factor fr r";
CM_ SG_ 1869 DI_tireWearFactor_ReL "Drive inverter: tire wear factor re l";
CM_ SG_ 1869 DI_tireWearFactor_ReR "Drive inverter: tire wear factor re r";
CM_ SG_ 1869 DI_kTireEstReUnSat "Drive inverter: k tire est re un sat";
CM_ SG_ 1869 DI_tireConfigSaved "Drive inverter: tire config saved";
CM_ SG_ 1869 DI_distanceSinceLastTireConfig "distance since odometer reading when Tire Configuration was last run";
CM_ SG_ 1869 DI_hydroplaningRisk "Drive inverter: hydroplaning risk";
CM_ SG_ 1869 DI_hydroplaningPuddlesWet "Drive inverter: hydroplaning puddles wet";
CM_ SG_ 1869 DI_hydroplaningPuddlesDry "Drive inverter: hydroplaning puddles dry";
CM_ SG_ 1869 DI_vehicleStuck "Drive inverter: vehicle stuck";
CM_ SG_ 1869 DI_kTireEstRe "Drive inverter: k tire est re";
CM_ SG_ 1869 DI_stickyMu "Drive inverter: sticky mu";
CM_ SG_ 1869 DI_stickyMuConfidence "Drive inverter: sticky mu confidence";
CM_ BO_ 694 "Drive inverter message: chassis control status";
CM_ SG_ 694 DI_vdcTelltaleFlash "Request to flash telltale in UI when VDC is active";
CM_ SG_ 694 DI_vdcTelltaleOn "Request to turn telltale ON in UI when VDC is faulted";
CM_ SG_ 694 DI_tcTelltaleFlash "Request to flash telltale in UI when TC is active";
CM_ SG_ 694 DI_tcTelltaleOn "Request to turn telltale ON in UI when TC is faulted";
CM_ SG_ 694 DI_tractionControlModeUI "Drive inverter: traction control mode UI";
CM_ SG_ 694 DI_ptcStateGlobalUI "Drive inverter: ptc state global UI";
CM_ SG_ 694 DI_btcStateUI "Drive inverter: btc state UI";
CM_ SG_ 694 DI_vehicleHoldTelltaleOn "Drive inverter: vehicle hold telltale on";
CM_ SG_ 694 DI_opdFeedbackReset "Drive inverter: opd feedback reset";
CM_ SG_ 694 DI_opdFeedbackResetPositiveSpeed "Drive inverter: opd feedback reset positive speeds";
CM_ SG_ 694 DI_slipperySurfaceOnUI "Drive inverter: slippery surface on UI";
CM_ SG_ 694 DI_yellowBrakeTelltaleOn "Request to turn yellow BRAKE telltale ON in UI";
CM_ SG_ 694 DI_greenABSTelltaleOn "Drive inverter: green ABS telltale on";
CM_ SG_ 694 DI_stabilityModeState "Current stability mode setting being honored by the DI";
CM_ BO_ 2007 "Drive inverter message: debug";
CM_ SG_ 2007 DI_debugSelector "Drive inverter: debug selector";
CM_ SG_ 2007 DI_regenBackfillCmd "Drive inverter: regen backfill cmd";
CM_ SG_ 2007 DI_regenBackfillUnavailableReaso "Drive inverter: regen backfill unavailable reason";
CM_ SG_ 2007 DI_regenBackfillAbsSatState "Drive inverter: regen backfill abs sat state";
CM_ SG_ 2007 DI_sysHeatPowerOptimal "Drive inverter: sys heat power optimal";
CM_ SG_ 2007 DI_sysPostPedalMinTorque "Drive inverter: sys post pedal min torque";
CM_ SG_ 2007 DI_sysPostPedalMaxTorque "Drive inverter: sys post pedal max torque";
CM_ SG_ 2007 DI_systemTorqueCommand "Drive inverter: system torque command";
CM_ BO_ 1866 "Drive inverter message: estimated brake temp";
CM_ SG_ 1866 DI_estimatedBrakeTempChecksum "Drive inverter: estimated brake temp checksum";
CM_ SG_ 1866 DI_estimatedBrakeTempCounter "Drive inverter: estimated brake temp counter";
CM_ SG_ 1866 DI_brakeFLTemp "Drive inverter: brake FL temp";
CM_ SG_ 1866 DI_brakeFRTemp "Drive inverter: brake FR temp";
CM_ SG_ 1866 DI_brakeRLTemp "Drive inverter: brake RL temp";
CM_ SG_ 1866 DI_brakeRRTemp "Drive inverter: brake RR temp";
CM_ SG_ 1866 DI_mcpIndex "Brake master cylinder pressure index";
CM_ SG_ 1866 DI_mcpIndexPrimeFilt "Filtered brake master cylinder pressure index prime";
CM_ BO_ 1623 "Drive inverter message: info";
CM_ SG_ 1623 DI_infoIndex "Drive inverter: info index";
CM_ SG_ 1623 DI_buildType "Drive inverter: build type";
CM_ SG_ 1623 DI_buildConfigurationId "Drive inverter: build configuration id";
CM_ SG_ 1623 DI_hardwareId "Drive inverter: hardware id";
CM_ SG_ 1623 DI_componentId "Drive inverter: component id";
CM_ SG_ 1623 DI_pcbaId "Drive inverter: pcba id";
CM_ SG_ 1623 DI_assemblyId "Drive inverter: assembly id";
CM_ SG_ 1623 DI_usageId "Drive inverter: usage id";
CM_ SG_ 1623 DI_subUsageId "Drive inverter: sub usage id";
CM_ SG_ 1623 DI_applicationCrc "Drive inverter: application crc";
CM_ SG_ 1623 DI_appGitHash "Drive inverter: app git hash";
CM_ SG_ 1623 DI_bootGitHash "Drive inverter: boot git hash";
CM_ BO_ 646 "Drive inverter message: loc status";
CM_ SG_ 646 DI_locStatusChecksum "Drive inverter: loc status checksum";
CM_ SG_ 646 DI_locStatusCounter "Drive inverter: loc status counter";
CM_ SG_ 646 DI_cruiseState "Cruise control state.";
CM_ SG_ 646 DI_cruiseSetSpeed "Cruise control set point.";
CM_ SG_ 646 DI_cruiseSetSpeedUnits "Drive inverter: cruise set speed units";
CM_ SG_ 646 DI_autoparkState "Drive inverter: autopark state";
CM_ SG_ 646 DI_parkBrakeState "DI Park Brake control and EPB interface state.";
CM_ SG_ 646 DI_aebState "Reports the Automatic Emergency Braking (AEB) state.";
CM_ SG_ 646 DI_loncDeactivationReason "Drive inverter: lonc deactivation reason";
CM_ SG_ 646 DI_vehicleHoldState "Vehicle hold state.";
CM_ SG_ 646 DI_summonInPanic "Drive inverter: summon in panic";
CM_ SG_ 646 DI_onePedalDrivingState "One Pedal Driving State machine state";
CM_ SG_ 646 DI_brakeStandActive "Detects active brake stand.";
CM_ SG_ 646 DI_regenBackfillState "Regen backfill state";
CM_ SG_ 646 DI_cruiseNotAvailableReason "Drive inverter: cruise not available reason";
CM_ SG_ 646 DI_cruiseFaultReason "Cruise control fault reason";
CM_ SG_ 646 DI_cruiseCancelReason "Cruise control cancel reason";
CM_ BO_ 1270 "Drive inverter message: loc status2";
CM_ SG_ 1270 DI_locStatus2Checksum "Drive inverter: loc status2 checksum";
CM_ SG_ 1270 DI_locStatus2Counter "Drive inverter: loc status2 counter";
CM_ SG_ 1270 DI_doublePedalState "Drive inverter: double pedal state";
CM_ SG_ 1270 DI_autopilotRequest "Drive inverter: autopilot request";
CM_ SG_ 1270 DI_rollPreventionState "Drive inverter: roll prevention state";
CM_ SG_ 1270 DI_locIntegratorSaturated "Drive inverter: loc integrator saturated";
CM_ SG_ 1270 DI_temporaryOpdActiveAfterLoncCa "Drive inverter: temporary opd active after lonc cancel";
CM_ SG_ 1270 DI_reapplyOnParkRequest "Drive inverter: reapply on park request";
CM_ SG_ 1270 DI_veDegradedAtStandstill "Drive inverter: ve degraded at standstill";
CM_ SG_ 1270 DI_brakeCpScale "Drive inverter: brake cp scale";
CM_ SG_ 1270 DI_rollbackDistance "Maximum vehicle rollback distance in current stopping event when OPD/Cruise is active";
CM_ SG_ 1270 DI_lowMuProbabilityConfidence "Drive inverter: low mu probability confidence";
CM_ SG_ 1270 DI_pedalAssistCurveSelectForSX "Drive inverter: pedal assist curve select for SX";
CM_ SG_ 1270 DI_longitudinalControlStack "Drive inverter: longitudinal control stack";
CM_ SG_ 1270 DI_useDasFallbackBrakeCommands "Drive inverter: use das fallback brake commands";
CM_ SG_ 1270 DI_regenBlendingState "Drive inverter: regen blending state";
CM_ SG_ 1270 DI_executeBatLocStatus2 "Drive inverter: execute bat loc status2";
CM_ BO_ 822 "Drive inverter message: max rated power";
CM_ SG_ 822 DI_sysDrivePowerRated "Drive inverter: sys drive power rated";
CM_ SG_ 822 DI_performancePackage "Drive inverter: performance package";
CM_ SG_ 822 DI_sysRegenPowerRated "Drive inverter: sys regen power rated";
CM_ BO_ 950 "Drive inverter message: odometer status";
CM_ SG_ 950 DI_odometer "Total traveled distance";
CM_ SG_ 950 DI_obdDriveCycleStatus "OBD qualified drive cycle status";
CM_ SG_ 950 DI_odometerStatusCounter "Drive inverter: odometer status counter";
CM_ SG_ 950 DI_odometerStatusChecksum "Drive inverter: odometer status checksum";
CM_ BO_ 599 "Drive inverter message: speed";
CM_ SG_ 599 DI_speedChecksum "Drive inverter: speed checksum";
CM_ SG_ 599 DI_speedCounter "Drive inverter: speed counter";
CM_ SG_ 599 DI_locSpeedEst "Drive inverter: loc speed est";
CM_ SG_ 599 DI_uiSpeed "Drive inverter: ui speed";
CM_ SG_ 599 DI_uiSpeedUnits "Drive inverter: ui speed units";
CM_ SG_ 599 DI_accelPedalPressed "TRUE when the calibrated accel pedal position > 0.0";
CM_ SG_ 599 DI_sideslipEstimate "Drive inverter: sideslip estimate";
CM_ SG_ 599 DI_vehicleSpeed "Reports vehicle speed.";
CM_ SG_ 599 DI_velocityEstimatorState "Drive inverter: velocity estimator state";
CM_ SG_ 599 DI_autoEnableHazards "Drive inverter: auto enable hazards";
CM_ SG_ 599 DI_longControlCommandActive "Drive inverter: long control command active";
CM_ BO_ 2006 "Drive inverter message: stalkless interfaces";
CM_ SG_ 2006 DI_stalklessInterfacesChecksum "Drive inverter: stalkless interfaces checksum";
CM_ SG_ 2006 DI_stalklessInterfacesCounter "Drive inverter: stalkless interfaces counter";
CM_ SG_ 2006 DI_smartShiftClosureOpen "Drive inverter: smart shift closure open";
CM_ SG_ 2006 DI_smartShiftSeatbeltUnbuckled "Drive inverter: smart shift seatbelt unbuckled";
CM_ SG_ 2006 DI_smartShiftAvailable "Drive inverter: smart shift available";
CM_ SG_ 2006 DI_smartShiftPrimed "Drive inverter: smart shift primed";
CM_ SG_ 2006 DI_smartShiftBrakePressed "Drive inverter: smart shift brake pressed";
CM_ SG_ 2006 DI_smartShiftBrakeReapplyRequire "Drive inverter: smart shift brake reapply required";
CM_ BO_ 597 "Drive inverter message: suggested gear";
CM_ SG_ 597 DI_lastQualifiedGear "Drive inverter: last qualified gear";
CM_ SG_ 597 DI_lastDrivingGear "Drive inverter: last driving gear";
CM_ SG_ 597 DI_distDrivenInGear "Drive inverter: dist driven in gear";
CM_ SG_ 597 DI_frontBlocked "Drive inverter: front blocked";
CM_ SG_ 597 DI_rearBlocked "Drive inverter: rear blocked";
CM_ SG_ 597 DI_firstShiftOccurred "Drive inverter: first shift occurred";
CM_ SG_ 597 DI_suggestedGearReason "Reason for the suggested gear";
CM_ SG_ 597 DI_parallelParked "Drive inverter: parallel parked";
CM_ SG_ 597 DI_smartShiftGear "Gear vehicle will shift into if smart shift occurs";
CM_ SG_ 597 DI_smartShiftUnavailableReason "Reports the reason why Smart Shift is unavailable.";
CM_ BO_ 296 "Drive inverter message: system limits";
CM_ SG_ 296 DI_limitRegenPower "TRUE when torque is limited due to regen power limit.";
CM_ SG_ 296 DI_limitIBat "TRUE when torque is limited due to battery current.";
CM_ SG_ 296 DI_limitVBatLow "Drive inverter: limit v bat low";
CM_ SG_ 296 DI_limitVBatHigh "Drive inverter: limit v bat high";
CM_ SG_ 296 DI_limitObstacleDetection "TRUE when torque is limited due to obstacle detected in vehicle path.";
CM_ SG_ 296 DI_limitSystemLimp "Drive inverter: limit system limp";
CM_ SG_ 296 DI_limitSystemGPO "Drive inverter: limit system GPO";
CM_ SG_ 296 DI_limitShift "Drive inverter: limit shift";
CM_ SG_ 296 DI_limitDriveTorque "TRUE when drive torque is limited due to driver torque limit command";
CM_ SG_ 296 DI_limitRegenTorque "TRUE when regen torque is limited due to driver torque limit command";
CM_ SG_ 296 DI_limitVehicleSpeed "Drive inverter: limit vehicle speed";
CM_ SG_ 296 DI_limitBmsMiaFreeze "Drive inverter: limit bms mia freeze";
CM_ SG_ 296 DI_limitSystemSpinDownLearning "Drive inverter: limit system spin down learning";
CM_ SG_ 296 DI_limitCdp "Drive inverter: limit cdp";
CM_ SG_ 296 DI_vehicleSpeedLimitType "Speed limit source/type of DI_vehicleSpeedLimit.";
CM_ SG_ 296 DI_vehicleSpeedLimit "Vehicle speed limit (including powertrain limits) being enforced by the DI and published to the UI.";
CM_ SG_ 296 DI_vehicleSpeedLimitReason "Speed limit reason of DI_vehicleSpeedLimit.";
CM_ SG_ 296 DI_proximity "TRUE if the proximity hardware input signal is active.";
CM_ SG_ 296 DI_limitClosureNotClosed "Drive inverter: limit closure not closed";
CM_ SG_ 296 DI_undersideAbuse "Drive inverter: underside abuse";
CM_ SG_ 296 DI_immobilizerAuthLevel "Immobilizer Authentication Level";
CM_ SG_ 296 DI_manualRecoveryDistanceRemaini "Drive inverter: manual recovery distance remaining";
CM_ SG_ 296 DI_restrictedDrivingMode "Drive inverter: restricted driving mode";
CM_ BO_ 616 "Drive inverter message: system power";
CM_ SG_ 616 DI_sysHeatPowerMax "Drive inverter: sys heat power max";
CM_ SG_ 616 DI_sysHeatPowerActual "Drive Inverter system heat power";
CM_ SG_ 616 DI_sysDrivePowerMax "Maximum drive power output total for all motors.";
CM_ SG_ 616 DI_primaryUnitSiliconType "Drive inverter: primary unit silicon type";
CM_ SG_ 616 DI_sysRegenPowerMax "Maximum regen power output total for all motors.";
CM_ BO_ 280 "Drive inverter message: system status";
CM_ SG_ 280 DI_systemStatusChecksum "Drive inverter: system status checksum";
CM_ SG_ 280 DI_systemStatusCounter "Drive inverter: system status counter";
CM_ SG_ 280 DI_secondaryGearControlStatus "Indicates if gear control through PRND is being honored";
CM_ SG_ 280 DI_immobilizerState "Detects state of the Drive Inverter (DI) immobilizer.";
CM_ SG_ 280 DI_systemState "DI system state machine state.";
CM_ SG_ 280 DI_brakePedalState "Brake pedal switch signal sensed at the drive inverter.";
CM_ SG_ 280 DI_gear "Detects the current operating gear reported by the drive inverter.";
CM_ SG_ 280 DI_driveBlocked "Reason drive unit is blocked from entering enable";
CM_ SG_ 280 DI_hvilSystemStatus "Aggregated HVIL system status";
CM_ SG_ 280 DI_driveModeState "System drive mode state";
CM_ SG_ 280 DI_shiftRequestType "Type of most recent shift request";
CM_ SG_ 280 DI_accelPedalPos "Drive Inverter measured accelerator pedal position.";
CM_ SG_ 280 DI_tractionControlMode "Active traction control mode as requested by the driver.";
CM_ SG_ 280 DI_dynoModeAvailable "Reports to the vehicle if the Drive Inverter (DI) will accept a request to enter dyno mode.";
CM_ SG_ 280 DI_epbRequest "Reports Electronic Parking Brake (EPB) requests.";
CM_ SG_ 280 DI_brakeSource "Drive inverter: brake source";
CM_ SG_ 280 DI_keepDrivePowerStateRequest "Reports that the Drive Inverter (DI) expects vehicle power state to remain in drive.";
CM_ SG_ 280 DI_trackModeState "Indicates state of Track mode";
CM_ SG_ 280 DI_autonomyControlActive "Drive inverter: autonomy control active";
CM_ SG_ 280 DI_regenLight "Drive inverter: regen light";
CM_ SG_ 280 DI_vehicleAcceleration "Drive inverter: vehicle acceleration";
CM_ BO_ 2036 "Drive inverter message: vdc right";
CM_ SG_ 2036 DI_vdcRightChecksum "Drive inverter: vdc right checksum";
CM_ SG_ 2036 DI_vdcRightCounter "Drive inverter: vdc right counter";
CM_ SG_ 2036 DI_vdcCommandTypeFrR "Drive inverter: vdc command type fr r";
CM_ SG_ 2036 DI_vdcCommandTypeReR "Drive inverter: vdc command type re r";
CM_ SG_ 2036 DI_vdcCommandABSFrR "Drive inverter: vdc command ABS fr r";
CM_ SG_ 2036 DI_vdcCommandABSReR "Drive inverter: vdc command ABS re r";
CM_ SG_ 2036 DI_brakeTorqueTarFrR "Drive inverter: brake torque tar fr r";
CM_ SG_ 2036 DI_brakeTorqueTarReR "Drive inverter: brake torque tar re r";
CM_ SG_ 2036 DI_wheelSlipLimitFrR "Drive inverter: wheel slip limit fr r";
CM_ SG_ 2036 DI_wheelSlipLimitReR "Drive inverter: wheel slip limit re r";
CM_ SG_ 2036 DI_rawLowMuProbability "Drive inverter: raw low mu probability";
CM_ BO_ 615 "Drive inverter message: vehicle estimates";
CM_ SG_ 615 DI_mass "Detects learned mass.";
CM_ SG_ 615 DI_massRLS "Drive inverter: mass RLS";
CM_ SG_ 615 DI_trailerDetected "Drive inverter: trailer detected";
CM_ SG_ 615 DI_vehicleEstimatesCounter "Drive inverter: vehicle estimates counter";
CM_ SG_ 615 DI_relativeTireTreadDepth "Reports estimate of tire wear ratio, represented in estimated tread depth difference between front and rear tires. A positive value indicates the rear tires are more worn than the front tires.";
CM_ SG_ 615 DI_tireFitment "Drive inverter: tire fitment";
CM_ SG_ 615 DI_rollCoeff "Drive inverter: roll coeff";
CM_ SG_ 615 DI_massConfidence "Drive inverter: mass confidence";
CM_ SG_ 615 DI_gradeEst "Grade estimate reported by the drive inverter.";
CM_ SG_ 615 DI_vehicleEstimatesChecksum "Drive inverter: vehicle estimates checksum";
CM_ SG_ 615 DI_gradeEstInternal "Drive inverter: grade est internal";
CM_ SG_ 615 DI_massConfidenceRLS "Drive inverter: mass confidence RLS";
CM_ SG_ 615 DI_steeringAngleOffset "Steering angle offset learned by vehicle dynamics control (VDC) represented as a hand wheel angle";
CM_ BO_ 1237 "DPB ECU message: alert log";
CM_ SG_ 1237 DPB_alertID "DPB ECU: alert ID";
CM_ SG_ 1237 DPB_alertState "DPB ECU: alert state";
BA_DEF_ BO_ "GenMsgCycleTime" INT 0 3600000;
BA_DEF_ BO_ "GenMsgSendType" ENUM "Cyclic","NotUsed","NotUsed","NotUsed","NotUsed","NotUsed","NotUsed","IfActive","NoMsgSendType","NotUsed";
BA_DEF_ BO_ "VFrameFormat" ENUM "StandardCAN","ExtendedCAN","reserved","J1939PG","reserved","reserved","reserved","reserved","reserved","reserved","reserved","reserved","reserved","reserved","StandardCAN_FD","ExtendedCAN_FD";
BA_DEF_ BO_ "CANFD_BRS" ENUM "0","1";
BA_DEF_ SG_ "SystemSignalLongSymbol" STRING;
BA_DEF_ SG_ "Confidence" ENUM "layout-only","plausible","validated";
BA_DEF_DEF_ "GenMsgCycleTime" 0;
BA_DEF_DEF_ "GenMsgSendType" "NoMsgSendType";
BA_DEF_DEF_ "VFrameFormat" "StandardCAN";
BA_DEF_DEF_ "CANFD_BRS" "1";
BA_DEF_DEF_ "SystemSignalLongSymbol" "";
BA_DEF_DEF_ "Confidence" "layout-only";
BA_ "Confidence" SG_ 789 DIR_inverterTQF 1;
BA_ "Confidence" SG_ 789 DIR_pcbT 1;
BA_ "Confidence" SG_ 789 DIR_inverterT 1;
BA_ "Confidence" SG_ 789 DIR_statorT 1;
BA_ "Confidence" SG_ 789 DIR_dcCapT 1;
BA_ "Confidence" SG_ 789 DIR_heatsinkT 1;
BA_ "Confidence" SG_ 789 DIR_inverterTpct 1;
BA_ "Confidence" SG_ 789 DIR_statorTpct 1;
BA_ "Confidence" SG_ 789 DIR_fluidInTemp 1;
BA_ "Confidence" SG_ 789 DIR_normalFetBurnIn 1;
BA_ "Confidence" SG_ 789 DIR_additionalFetBurnIn 1;
BA_ "Confidence" SG_ 789 DIR_currentWeibullMiles 1;
BA_ "Confidence" SG_ 789 DIR_endOfServiceWeibullMiles 1;
BA_ "Confidence" SG_ 789 DIR_burnInDamageRatio 1;
BA_ "Confidence" SG_ 789 DIR_inverterSensorEst 1;
BA_ "Confidence" SG_ 789 DIR_inverterHS1Est 1;
BA_ "Confidence" SG_ 789 DIR_initialBurnInVehicleOdometer 1;
BA_ "Confidence" SG_ 789 DIR_inverterHS2Est 1;
BA_ "Confidence" SG_ 789 DIR_inverterInletEst 1;
BA_ "Confidence" SG_ 789 DIR_statorHousingTemp 1;
BA_ "Confidence" SG_ 1495 DIR_passiveInletTempReq 1;
BA_ "Confidence" SG_ 1495 DIR_activeInletTempReq 1;
BA_ "Confidence" SG_ 1495 DIR_coolantFlowReq 1;
BA_ "Confidence" SG_ 1495 DIR_oilFlowReq 1;
BA_ "Confidence" SG_ 1495 DIR_criticalFlowReq 1;
BA_ "Confidence" SG_ 1495 DIR_burnInStatus 1;
BA_ "Confidence" SG_ 264 DIR_torqueCommand 1;
BA_ "Confidence" SG_ 264 DIR_axleSpeedQF 1;
BA_ "Confidence" SG_ 264 DIR_torqueActual 1;
BA_ "Confidence" SG_ 264 DIR_axleSpeed 1;
BA_ "Confidence" SG_ 264 DIR_axleTorqueQF 1;
BA_ "Confidence" SG_ 264 DIR_axlePowerCalcQF 1;
BA_ "Confidence" SG_ 264 DIR_gear 1;
BA_ "SystemSignalLongSymbol" SG_ 1319 DI_a086_DPB_redundantBrakingStat "DI_a086_DPB_redundantBrakingStatus";
BA_ "SystemSignalLongSymbol" SG_ 1319 DI_a091_ESP_redundantBrakingStat "DI_a091_ESP_redundantBrakingStatus";
BA_ "SystemSignalLongSymbol" SG_ 1319 DI_a120_blendingUnavailableReaso "DI_a120_blendingUnavailableReason";
BA_ "SystemSignalLongSymbol" SG_ 1319 DI_a141_DAS_longControlTuningPar "DI_a141_DAS_longControlTuningParameters";
BA_ "SystemSignalLongSymbol" SG_ 1319 DI_a141_DAS_redundantBrakingCont "DI_a141_DAS_redundantBrakingControl";
BA_ "SystemSignalLongSymbol" SG_ 1319 DI_a158_IBST_redundantBrakingSta "DI_a158_IBST_redundantBrakingStatus";
BA_ "SystemSignalLongSymbol" SG_ 1319 DI_a160_distanceSinceLastTireCon "DI_a160_distanceSinceLastTireConfig";
BA_ "SystemSignalLongSymbol" SG_ 1319 DI_a170_distanceSinceLastTireCon "DI_a170_distanceSinceLastTireConfig";
BA_ "SystemSignalLongSymbol" SG_ 1319 DI_a190_treadWearFactorAvgConfid "DI_a190_treadWearFactorAvgConfidence";
BA_ "SystemSignalLongSymbol" SG_ 1319 DI_a210_secondaryBrakeActuatorIs "DI_a210_secondaryBrakeActuatorIsMaster";
BA_ "SystemSignalLongSymbol" SG_ 871 DI_a026_parkPressedWithHighAPeda "DI_a026_parkPressedWithHighAPedal";
BA_ "SystemSignalLongSymbol" SG_ 871 DI_a027_steeringAngleOffsetServi "DI_a027_steeringAngleOffsetService";
BA_ "SystemSignalLongSymbol" SG_ 871 DI_a036_sysStandbyUnitLimitedWai "DI_a036_sysStandbyUnitLimitedWait";
BA_ "SystemSignalLongSymbol" SG_ 871 DI_a039_exceptionUndefinedInstru "DI_a039_exceptionUndefinedInstruction";
BA_ "SystemSignalLongSymbol" SG_ 871 DI_d047_interfacePowerSupplyIssu "DI_d047_interfacePowerSupplyIssue";
BA_ "SystemSignalLongSymbol" SG_ 871 DI_d050_interfaceUnitCommunicati "DI_d050_interfaceUnitCommunicationIssue";
BA_ "SystemSignalLongSymbol" SG_ 871 DI_a068_secondaryWheelSpeedIrrat "DI_a068_secondaryWheelSpeedIrrational";
BA_ "SystemSignalLongSymbol" SG_ 871 DI_d073_accelPedalVoltSupplyIssu "DI_d073_accelPedalVoltSupplyIssue";
BA_ "SystemSignalLongSymbol" SG_ 871 DI_a107_idbBrakeCircuitPressureO "DI_a107_idbBrakeCircuitPressureOffsetSuspect";
BA_ "SystemSignalLongSymbol" SG_ 871 DI_a118_diImmobilizedForFactoryF "DI_a118_diImmobilizedForFactoryFailsafe";
BA_ "SystemSignalLongSymbol" SG_ 871 DI_a119_latentFaultCheckFailedOn "DI_a119_latentFaultCheckFailedOnce";
BA_ "SystemSignalLongSymbol" SG_ 871 DI_a121_qualifiedBrakeEventMitig "DI_a121_qualifiedBrakeEventMitigation";
BA_ "SystemSignalLongSymbol" SG_ 871 DI_a179_steeringAngleOffsetWarni "DI_a179_steeringAngleOffsetWarning";
BA_ "SystemSignalLongSymbol" SG_ 871 DI_a188_tireRotationRecommendedG "DI_a188_tireRotationRecommendedGhosted";
BA_ "SystemSignalLongSymbol" SG_ 871 DI_a200_vdcModelBasedPlausibilit "DI_a200_vdcModelBasedPlausibility";
BA_ "SystemSignalLongSymbol" SG_ 871 DI_a232_velocityEstimatorDegrade "DI_a232_velocityEstimatorDegraded";
BA_ "SystemSignalLongSymbol" SG_ 871 DI_a238_secondaryCollisionMitiga "DI_a238_secondaryCollisionMitigationActive";
BA_ "SystemSignalLongSymbol" SG_ 871 DI_a248_vdcPreControlHighDynamic "DI_a248_vdcPreControlHighDynamicActive";
BA_ "SystemSignalLongSymbol" SG_ 871 DI_a249_spinDownLearningInProgre "DI_a249_spinDownLearningInProgress";
BA_ "Confidence" SG_ 84 DI_ah_vehicleSpeedLimit 1;
BA_ "Confidence" SG_ 84 DI_ah_vehicleReverseSpeedLimit 1;
BA_ "Confidence" SG_ 84 DI_autonomyBehavior 1;
BA_ "Confidence" SG_ 84 DI_ah_vehicleNoGradeAccelMax 1;
BA_ "Confidence" SG_ 84 DI_ah_vehicleNoGradeDecelMax 1;
BA_ "Confidence" SG_ 84 DI_ah_timeToNoPropulsion 1;
BA_ "SystemSignalLongSymbol" SG_ 84 DI_loncSuppressCancelModeAvailab "DI_loncSuppressCancelModeAvailable";
BA_ "Confidence" SG_ 84 DI_loncDegradedReason 1;
BA_ "Confidence" SG_ 328 DI_imuOffsetLearnRequest 1;
BA_ "Confidence" SG_ 328 DI_brakeCommandType 1;
BA_ "Confidence" SG_ 328 DI_brakeTorqueRequestActive 1;
BA_ "Confidence" SG_ 328 DI_brakeTorqueCommand 1;
BA_ "Confidence" SG_ 328 DI_ptcStateGlobal 1;
BA_ "Confidence" SG_ 328 DI_ptcActive 1;
BA_ "Confidence" SG_ 328 DI_vdcState 1;
BA_ "Confidence" SG_ 328 DI_isAnyVdcControlActive 1;
BA_ "Confidence" SG_ 328 DI_vdcMode 1;
BA_ "Confidence" SG_ 328 DI_pedalAssistCurveSelect 1;
BA_ "Confidence" SG_ 328 DI_isAnyTcActive 1;
BA_ "Confidence" SG_ 328 DI_VehicleMuConfidence 1;
BA_ "Confidence" SG_ 328 DI_VehicleMu 1;
BA_ "Confidence" SG_ 328 DI_trailerSwayIndex 1;
BA_ "Confidence" SG_ 328 DI_vdcControlActive 1;
BA_ "Confidence" SG_ 328 DI_treadDepthAlertSet 1;
BA_ "Confidence" SG_ 1861 DI_gradeAngle 1;
BA_ "Confidence" SG_ 1861 DI_bankAngle 1;
BA_ "Confidence" SG_ 1861 DI_chassisControlVideoRequest 1;
BA_ "Confidence" SG_ 1861 DI_tireUtilizationRatioFrL 1;
BA_ "Confidence" SG_ 1861 DI_tireUtilizationRatioFrR 1;
BA_ "Confidence" SG_ 1861 DI_tireUtilizationRatioReL 1;
BA_ "Confidence" SG_ 1861 DI_tireUtilizationRatioReR 1;
BA_ "Confidence" SG_ 1861 DI_counterSteerTarget 1;
BA_ "Confidence" SG_ 1861 DI_splitMuProbability 1;
BA_ "Confidence" SG_ 1861 DI_mzError 1;
BA_ "Confidence" SG_ 1861 DI_slipDifferenceFrontRear 1;
BA_ "Confidence" SG_ 1861 DI_highFreqYawRate 1;
BA_ "Confidence" SG_ 1861 DI_turnDirection 1;
BA_ "Confidence" SG_ 1861 DI_absolutePreControlRequest 1;
BA_ "Confidence" SG_ 1861 DI_oppositeBuildDirFrontAxle 1;
BA_ "Confidence" SG_ 1861 DI_oppositeBuildDirRearAxle 1;
BA_ "Confidence" SG_ 1861 DI_saturatedEffectiveness 1;
BA_ "Confidence" SG_ 1861 DI_driverPanicIndex 1;
BA_ "Confidence" SG_ 1861 DI_learnDownMu 1;
BA_ "Confidence" SG_ 1861 DI_preControlOpposingTurnDir 1;
BA_ "Confidence" SG_ 1861 DI_driverFxError 1;
BA_ "Confidence" SG_ 1861 DI_targetSaturation 1;
BA_ "Confidence" SG_ 1869 DI_tireWearFactor_FrL 1;
BA_ "Confidence" SG_ 1869 DI_tireWearFactor_FrR 1;
BA_ "Confidence" SG_ 1869 DI_tireWearFactor_ReL 1;
BA_ "Confidence" SG_ 1869 DI_tireWearFactor_ReR 1;
BA_ "Confidence" SG_ 1869 DI_kTireEstReUnSat 1;
BA_ "Confidence" SG_ 1869 DI_distanceSinceLastTireConfig 1;
BA_ "Confidence" SG_ 1869 DI_hydroplaningRisk 1;
BA_ "Confidence" SG_ 1869 DI_hydroplaningPuddlesWet 1;
BA_ "Confidence" SG_ 1869 DI_hydroplaningPuddlesDry 1;
BA_ "Confidence" SG_ 1869 DI_kTireEstRe 1;
BA_ "Confidence" SG_ 1869 DI_stickyMu 1;
BA_ "Confidence" SG_ 1869 DI_stickyMuConfidence 1;
BA_ "Confidence" SG_ 694 DI_vdcTelltaleFlash 1;
BA_ "Confidence" SG_ 694 DI_vdcTelltaleOn 1;
BA_ "Confidence" SG_ 694 DI_tcTelltaleFlash 1;
BA_ "Confidence" SG_ 694 DI_tcTelltaleOn 1;
BA_ "Confidence" SG_ 694 DI_tractionControlModeUI 1;
BA_ "Confidence" SG_ 694 DI_ptcStateGlobalUI 1;
BA_ "Confidence" SG_ 694 DI_btcStateUI 1;
BA_ "Confidence" SG_ 694 DI_vehicleHoldTelltaleOn 1;
BA_ "SystemSignalLongSymbol" SG_ 694 DI_opdFeedbackResetPositiveSpeed "DI_opdFeedbackResetPositiveSpeeds";
BA_ "Confidence" SG_ 694 DI_slipperySurfaceOnUI 1;
BA_ "Confidence" SG_ 694 DI_yellowBrakeTelltaleOn 1;
BA_ "Confidence" SG_ 694 DI_greenABSTelltaleOn 1;
BA_ "Confidence" SG_ 694 DI_stabilityModeState 1;
BA_ "Confidence" SG_ 2007 DI_regenBackfillCmd 1;
BA_ "Confidence" SG_ 2007 DI_regenBackfillUnavailableReaso 1;
BA_ "SystemSignalLongSymbol" SG_ 2007 DI_regenBackfillUnavailableReaso "DI_regenBackfillUnavailableReason";
BA_ "Confidence" SG_ 2007 DI_regenBackfillAbsSatState 1;
BA_ "Confidence" SG_ 2007 DI_sysHeatPowerOptimal 1;
BA_ "Confidence" SG_ 2007 DI_sysPostPedalMinTorque 1;
BA_ "Confidence" SG_ 2007 DI_sysPostPedalMaxTorque 1;
BA_ "Confidence" SG_ 2007 DI_systemTorqueCommand 1;
BA_ "Confidence" SG_ 1866 DI_brakeFLTemp 1;
BA_ "Confidence" SG_ 1866 DI_brakeFRTemp 1;
BA_ "Confidence" SG_ 1866 DI_brakeRLTemp 1;
BA_ "Confidence" SG_ 1866 DI_brakeRRTemp 1;
BA_ "Confidence" SG_ 1866 DI_mcpIndex 1;
BA_ "Confidence" SG_ 1866 DI_mcpIndexPrimeFilt 1;
BA_ "Confidence" SG_ 1623 DI_buildType 1;
BA_ "Confidence" SG_ 646 DI_cruiseState 1;
BA_ "Confidence" SG_ 646 DI_cruiseSetSpeed 1;
BA_ "Confidence" SG_ 646 DI_cruiseSetSpeedUnits 1;
BA_ "Confidence" SG_ 646 DI_autoparkState 1;
BA_ "Confidence" SG_ 646 DI_parkBrakeState 1;
BA_ "Confidence" SG_ 646 DI_aebState 1;
BA_ "Confidence" SG_ 646 DI_loncDeactivationReason 1;
BA_ "Confidence" SG_ 646 DI_vehicleHoldState 1;
BA_ "Confidence" SG_ 646 DI_onePedalDrivingState 1;
BA_ "Confidence" SG_ 646 DI_brakeStandActive 1;
BA_ "Confidence" SG_ 646 DI_regenBackfillState 1;
BA_ "Confidence" SG_ 646 DI_cruiseNotAvailableReason 1;
BA_ "Confidence" SG_ 646 DI_cruiseFaultReason 1;
BA_ "Confidence" SG_ 646 DI_cruiseCancelReason 1;
BA_ "Confidence" SG_ 1270 DI_doublePedalState 1;
BA_ "Confidence" SG_ 1270 DI_autopilotRequest 1;
BA_ "Confidence" SG_ 1270 DI_rollPreventionState 1;
BA_ "SystemSignalLongSymbol" SG_ 1270 DI_temporaryOpdActiveAfterLoncCa "DI_temporaryOpdActiveAfterLoncCancel";
BA_ "Confidence" SG_ 1270 DI_brakeCpScale 1;
BA_ "Confidence" SG_ 1270 DI_rollbackDistance 1;
BA_ "Confidence" SG_ 1270 DI_lowMuProbabilityConfidence 1;
BA_ "Confidence" SG_ 1270 DI_pedalAssistCurveSelectForSX 1;
BA_ "Confidence" SG_ 1270 DI_longitudinalControlStack 1;
BA_ "Confidence" SG_ 1270 DI_regenBlendingState 1;
BA_ "Confidence" SG_ 822 DI_sysDrivePowerRated 1;
BA_ "Confidence" SG_ 822 DI_performancePackage 1;
BA_ "Confidence" SG_ 822 DI_sysRegenPowerRated 1;
BA_ "Confidence" SG_ 950 DI_odometer 1;
BA_ "Confidence" SG_ 950 DI_obdDriveCycleStatus 1;
BA_ "Confidence" SG_ 599 DI_locSpeedEst 1;
BA_ "Confidence" SG_ 599 DI_uiSpeedUnits 1;
BA_ "Confidence" SG_ 599 DI_accelPedalPressed 1;
BA_ "Confidence" SG_ 599 DI_sideslipEstimate 1;
BA_ "Confidence" SG_ 599 DI_vehicleSpeed 1;
BA_ "Confidence" SG_ 599 DI_velocityEstimatorState 1;
BA_ "SystemSignalLongSymbol" SG_ 2006 DI_smartShiftBrakeReapplyRequire "DI_smartShiftBrakeReapplyRequired";
BA_ "Confidence" SG_ 597 DI_lastQualifiedGear 1;
BA_ "Confidence" SG_ 597 DI_lastDrivingGear 1;
BA_ "Confidence" SG_ 597 DI_distDrivenInGear 1;
BA_ "Confidence" SG_ 597 DI_suggestedGearReason 1;
BA_ "Confidence" SG_ 597 DI_smartShiftGear 1;
BA_ "Confidence" SG_ 597 DI_smartShiftUnavailableReason 1;
BA_ "Confidence" SG_ 296 DI_limitRegenPower 1;
BA_ "Confidence" SG_ 296 DI_limitIBat 1;
BA_ "Confidence" SG_ 296 DI_limitObstacleDetection 1;
BA_ "Confidence" SG_ 296 DI_limitDriveTorque 1;
BA_ "Confidence" SG_ 296 DI_limitRegenTorque 1;
BA_ "Confidence" SG_ 296 DI_vehicleSpeedLimitType 1;
BA_ "Confidence" SG_ 296 DI_vehicleSpeedLimit 1;
BA_ "Confidence" SG_ 296 DI_vehicleSpeedLimitReason 1;
BA_ "Confidence" SG_ 296 DI_proximity 1;
BA_ "Confidence" SG_ 296 DI_immobilizerAuthLevel 1;
BA_ "Confidence" SG_ 296 DI_manualRecoveryDistanceRemaini 1;
BA_ "SystemSignalLongSymbol" SG_ 296 DI_manualRecoveryDistanceRemaini "DI_manualRecoveryDistanceRemaining";
BA_ "Confidence" SG_ 296 DI_restrictedDrivingMode 1;
BA_ "Confidence" SG_ 616 DI_sysHeatPowerMax 1;
BA_ "Confidence" SG_ 616 DI_sysHeatPowerActual 1;
BA_ "Confidence" SG_ 616 DI_sysDrivePowerMax 1;
BA_ "Confidence" SG_ 616 DI_primaryUnitSiliconType 1;
BA_ "Confidence" SG_ 616 DI_sysRegenPowerMax 1;
BA_ "Confidence" SG_ 280 DI_secondaryGearControlStatus 1;
BA_ "Confidence" SG_ 280 DI_immobilizerState 1;
BA_ "Confidence" SG_ 280 DI_systemState 1;
BA_ "Confidence" SG_ 280 DI_brakePedalState 1;
BA_ "Confidence" SG_ 280 DI_gear 1;
BA_ "Confidence" SG_ 280 DI_driveBlocked 1;
BA_ "Confidence" SG_ 280 DI_hvilSystemStatus 1;
BA_ "Confidence" SG_ 280 DI_driveModeState 1;
BA_ "Confidence" SG_ 280 DI_shiftRequestType 1;
BA_ "Confidence" SG_ 280 DI_accelPedalPos 1;
BA_ "Confidence" SG_ 280 DI_tractionControlMode 1;
BA_ "Confidence" SG_ 280 DI_dynoModeAvailable 1;
BA_ "Confidence" SG_ 280 DI_epbRequest 1;
BA_ "Confidence" SG_ 280 DI_brakeSource 1;
BA_ "Confidence" SG_ 280 DI_keepDrivePowerStateRequest 1;
BA_ "Confidence" SG_ 280 DI_trackModeState 1;
BA_ "Confidence" SG_ 280 DI_vehicleAcceleration 1;
BA_ "Confidence" SG_ 2036 DI_vdcCommandTypeFrR 1;
BA_ "Confidence" SG_ 2036 DI_vdcCommandTypeReR 1;
BA_ "Confidence" SG_ 2036 DI_vdcCommandABSFrR 1;
BA_ "Confidence" SG_ 2036 DI_vdcCommandABSReR 1;
BA_ "Confidence" SG_ 2036 DI_brakeTorqueTarFrR 1;
BA_ "Confidence" SG_ 2036 DI_brakeTorqueTarReR 1;
BA_ "Confidence" SG_ 2036 DI_wheelSlipLimitFrR 1;
BA_ "Confidence" SG_ 2036 DI_wheelSlipLimitReR 1;
BA_ "Confidence" SG_ 2036 DI_rawLowMuProbability 1;
BA_ "Confidence" SG_ 615 DI_mass 1;
BA_ "Confidence" SG_ 615 DI_massRLS 1;
BA_ "Confidence" SG_ 615 DI_trailerDetected 1;
BA_ "Confidence" SG_ 615 DI_relativeTireTreadDepth 1;
BA_ "Confidence" SG_ 615 DI_tireFitment 1;
BA_ "Confidence" SG_ 615 DI_rollCoeff 1;
BA_ "Confidence" SG_ 615 DI_massConfidence 1;
BA_ "Confidence" SG_ 615 DI_gradeEst 1;
BA_ "Confidence" SG_ 615 DI_gradeEstInternal 1;
BA_ "Confidence" SG_ 615 DI_massConfidenceRLS 1;
BA_ "Confidence" SG_ 615 DI_steeringAngleOffset 1;
VAL_ 789 DIR_inverterTQF 3 "INVERTERT_UNKNOWN" 2 "INVERTERT_RATIONAL" 1 "INVERTERT_IRRATIONAL" 0 "INVERTERT_INIT" ;
VAL_ 1495 DIR_criticalFlowReq 1 "ACTIVE" 0 "NOT_ACTIVE" ;
VAL_ 1495 DIR_burnInStatus 5 "COMPLETE" 4 "ACTIVE" 3 "INCOMPLETE" 2 "UNAVAILABLE" 1 "NOT_REQUIRED" 0 "INIT" ;
VAL_ 264 DIR_axleSpeedQF 2 "FAULTED" 1 "VALID" 0 "INVALID" ;
VAL_ 264 DIR_axleTorqueQF 2 "FAULTED" 1 "VALID" 0 "INVALID" ;
VAL_ 264 DIR_axlePowerCalcQF 1 "VALID" 0 "INVALID" ;
VAL_ 264 DIR_gear 7 "DI_GEAR_SNA" 4 "DI_GEAR_D" 3 "DI_GEAR_N" 2 "DI_GEAR_R" 1 "DI_GEAR_P" 0 "DI_GEAR_INVALID" ;
VAL_ 84 DI_autonomyBehavior 2 "DRIVERLESS_NO_TAKEOVER" 1 "DRIVERLESS_TAKEOVER" 0 "DRIVER" ;
VAL_ 84 DI_loncDegradedReason 10 "DI_LONC_DEGRADED_REDUNDANT_BRAKES_ACTIVE" 9 "DI_LONC_DEGRADED_ABS_UNAVAILABLE" 8 "DI_LONC_DEGRADED_ESP_MIA" 7 "DI_LONC_DEGRADED_BRAKE_INVALID" 6 "DI_LONC_DEGRADED_VELOCITY_ESTIMATE_NOT_NORMAL" 5 "DI_LONC_DEGRADED_EBR" 4 "DI_LONC_DEGRADED_VDC_FAULT" 3 "DI_LONC_DEGRADED_TC_FAULT" 2 "DI_LONC_DEGRADED_VHLD_UNAVAILABLE" 1 "DI_LONC_DEGRADED_VHLD_FAULTED" 0 "DI_LONC_DEGRADED_NONE" ;
VAL_ 328 DI_imuOffsetLearnRequest 2 "IMU_FAST_LEARNING_TIME" 1 "IMU_SLOW_LEARNING_DISTANCE" 0 "IMU_OFFSET_LEARNING_OFF" ;
VAL_ 328 DI_brakeCommandType 1 "QUIET" 0 "FAST" ;
VAL_ 328 DI_brakeTorqueRequestActive 1 "ACTIVE" 0 "INACTIVE" ;
VAL_ 328 DI_ptcStateGlobal 3 "GLOBAL_PTC_STATE_SNA" 2 "GLOBAL_PTC_STATE_ON" 1 "GLOBAL_PTC_STATE_BACKUP" 0 "GLOBAL_PTC_STATE_FAULTED" ;
VAL_ 328 DI_ptcActive 1 "ACTIVE" 0 "INACTIVE" ;
VAL_ 328 DI_vdcState 3 "VDC_STATE_STARTUP" 2 "VDC_STATE_NORMAL" 1 "VDC_STATE_BACKUP_A" 0 "VDC_STATE_FAULTED" ;
VAL_ 328 DI_isAnyVdcControlActive 2 "UNUSED_VALUE" 1 "VDC_CONTROL_ACTIVE" 0 "VDC_NO_CONTROL_ACTIVE" ;
VAL_ 328 DI_vdcMode 2 "VDC_MODE_TRACK" 1 "VDC_MODE_ON" 0 "VDC_MODE_OFF" ;
VAL_ 328 DI_pedalAssistCurveSelect 15 "PEDAL_ASSIST_CURVE_15" 12 "PEDAL_ASSIST_CURVE_12" 11 "PEDAL_ASSIST_CURVE_11" 8 "PEDAL_ASSIST_CURVE_8" 6 "PEDAL_ASSIST_CURVE_6" 3 "PEDAL_ASSIST_CURVE_3" 0 "PEDAL_ASSIST_CURVE_0" ;
VAL_ 328 DI_isAnyTcActive 1 "ACTIVE" 0 "INACTIVE" ;
VAL_ 328 DI_vdcControlActive 4 "VDC_DECEL_ACTIVE" 3 "VDC_TRAILER_SWAY_ACTIVE" 2 "VDC_UNDERSTEER_ACTIVE" 1 "VDC_OVERSTEER_ACTIVE" 0 "VDC_NOT_ACTIVE" ;
VAL_ 328 DI_treadDepthAlertSet 1 "TRUE" 0 "FALSE" ;
VAL_ 1861 DI_chassisControlVideoRequest 15 "CHASSIS_CONTROL_EVENT_15" 14 "CHASSIS_CONTROL_EVENT_14" 13 "CHASSIS_CONTROL_EVENT_13" 12 "CHASSIS_CONTROL_EVENT_12" 11 "CHASSIS_CONTROL_EVENT_11" 10 "CHASSIS_CONTROL_EVENT_10" 9 "CHASSIS_CONTROL_EVENT_9" 8 "CHASSIS_CONTROL_EVENT_8" 7 "CHASSIS_CONTROL_EVENT_7" 6 "CHASSIS_CONTROL_EVENT_6" 5 "CHASSIS_CONTROL_EVENT_5" 4 "CHASSIS_CONTROL_EVENT_4" 3 "CHASSIS_CONTROL_EVENT_3" 2 "CHASSIS_CONTROL_EVENT_2" 1 "CHASSIS_CONTROL_EVENT_1" 0 "CHASSIS_CONTROL_EVENT_NONE" ;
VAL_ 1861 DI_counterSteerTarget 2 "EXPIRED" 1 "ACTIVE" 0 "INACTIVE" ;
VAL_ 1861 DI_turnDirection 1 "VDC_TURNING_LEFT" 0 "VDC_TURNING_RIGHT" ;
VAL_ 1861 DI_oppositeBuildDirFrontAxle 1 "TRUE" 0 "FALSE" ;
VAL_ 1861 DI_oppositeBuildDirRearAxle 1 "TRUE" 0 "FALSE" ;
VAL_ 1861 DI_saturatedEffectiveness 1 "TRUE" 0 "FALSE" ;
VAL_ 1861 DI_preControlOpposingTurnDir 1 "TRUE" 0 "FALSE" ;
VAL_ 694 DI_vdcTelltaleFlash 1 "TELLTALE_ON" 0 "TELLTALE_OFF" ;
VAL_ 694 DI_vdcTelltaleOn 1 "TELLTALE_ON" 0 "TELLTALE_OFF" ;
VAL_ 694 DI_tcTelltaleFlash 1 "TELLTALE_ON" 0 "TELLTALE_OFF" ;
VAL_ 694 DI_tcTelltaleOn 1 "TELLTALE_ON" 0 "TELLTALE_OFF" ;
VAL_ 694 DI_tractionControlModeUI 7 "TC_SLIPPERY_SURFACE" 6 "TC_OFFROAD_ASSIST" 5 "TC_DYNO_MODE" 4 "TC_ROLLS_MODE" 3 "TC_DEV_MODE_2" 2 "TC_DEV_MODE_1" 1 "TC_SLIP_START" 0 "TC_NORMAL" ;
VAL_ 694 DI_ptcStateGlobalUI 3 "GLOBAL_PTC_STATE_SNA" 2 "GLOBAL_PTC_STATE_ON" 1 "GLOBAL_PTC_STATE_BACKUP" 0 "GLOBAL_PTC_STATE_FAULTED" ;
VAL_ 694 DI_btcStateUI 1 "ON" 0 "OFF" ;
VAL_ 694 DI_vehicleHoldTelltaleOn 1 "TELLTALE_ON" 0 "TELLTALE_OFF" ;
VAL_ 694 DI_slipperySurfaceOnUI 1 "SLIPPERY_SURFACE_ON" 0 "SLIPPERY_SURFACE_OFF" ;
VAL_ 694 DI_yellowBrakeTelltaleOn 1 "TELLTALE_ON" 0 "TELLTALE_OFF" ;
VAL_ 694 DI_greenABSTelltaleOn 1 "TELLTALE_ON" 0 "TELLTALE_OFF" ;
VAL_ 694 DI_stabilityModeState 2 "REDUCED" 1 "NORMAL" 0 "UNAVAILABLE" ;
VAL_ 2007 DI_regenBackfillUnavailableReaso 18 "DI_LATENT_FAULT_TRIP" 17 "EBR_FULL_FAULT" 16 "PM_DISABLE_REQUEST_BPED" 15 "PM_DISABLE_REQUEST_BLEND" 14 "CARBON_CERAMIC_BRAKES" 13 "BRAKE_TEMP" 12 "EBR_FAULT" 11 "PM_DISABLE_REQUEST" 10 "TRACK_MODE_ACTIVE" 9 "VELOCITY_ESTIMATOR_UNAVAILABLE" 8 "TRACTION_CONTROL_UNAVAILABLE" 7 "ACTIVE_DAMPING_UNAVAILABLE" 6 "UI_COASTDOWN_MODE" 5 "SYSTEM_STATE" 4 "NON_DRIVE_GEAR" 3 "EBR_UNAVAILABLE" 2 "UI_DISABLE" 1 "GTW_DISABLE" 0 "NONE" ;
VAL_ 2007 DI_regenBackfillAbsSatState 2 "RAMP_IN" 1 "RAMP_OUT" 0 "IDLE" ;
VAL_ 1623 DI_buildType 4 "INFO_MFG_BUILD" 3 "INFO_TRACEABLE_CI_BUILD" 2 "INFO_LOCAL_BUILD" 1 "INFO_PLATFORM_BUILD" 0 "INFO_UNKNOWN_BUILD" ;
VAL_ 646 DI_cruiseState 7 "CRS_STATE_PRE_CANCEL" 6 "CRS_STATE_PRE_FAULT" 5 "CRS_STATE_FAULT" 4 "CRS_STATE_OVERRIDE" 3 "CRS_STATE_STANDSTILL" 2 "CRS_STATE_ENABLED" 1 "CRS_STATE_STANDBY" 0 "CRS_STATE_UNAVAILABLE" ;
VAL_ 646 DI_cruiseSetSpeedUnits 1 "DI_SPEED_KPH" 0 "DI_SPEED_MPH" ;
VAL_ 646 DI_autoparkState 15 "DI_APC_SNA" 9 "DI_APC_SELFPARK_STARTED" 8 "DI_APC_UNPARK_COMPLETE" 7 "DI_APC_RESUMED" 6 "DI_APC_ABORTED" 5 "DI_APC_PAUSED" 4 "DI_APC_COMPLETE" 3 "DI_APC_ACTIVE" 2 "DI_APC_STARTED" 1 "DI_APC_STANDBY" 0 "DI_APC_UNAVAILABLE" ;
VAL_ 646 DI_parkBrakeState 15 "DI_PBRK_SNA" 7 "DI_PBRK_RELEASING" 6 "DI_PBRK_PANIC_SKID" 5 "DI_PBRK_PANIC_EPB" 4 "DI_PBRK_FAULTED" 3 "DI_PBRK_APPLIED" 2 "DI_PBRK_REQUESTED" 1 "DI_PBRK_RELEASED" 0 "DI_PBRK_UNAVAILABLE" ;
VAL_ 646 DI_aebState 7 "AEB_CAN_STATE_SNA" 5 "AEB_CAN_STATE_UNAVAILABLE_ALERT" 4 "AEB_CAN_STATE_FAULT" 3 "AEB_CAN_STATE_STANDSTILL" 2 "AEB_CAN_STATE_ENABLED" 1 "AEB_CAN_STATE_STANDBY" 0 "AEB_CAN_STATE_UNAVAILABLE" ;
VAL_ 646 DI_loncDeactivationReason 3 "ABORT" 2 "DAS_CANCEL" 1 "USER_CANCEL" 0 "NO_CANCEL" ;
VAL_ 646 DI_vehicleHoldState 7 "DI_VHLD_STATE_INIT" 6 "DI_VHLD_STATE_FAULT" 5 "DI_VHLD_STATE_PARK" 4 "DI_VHLD_STATE_BLEND_OUT" 3 "DI_VHLD_STATE_STANDSTILL" 2 "DI_VHLD_STATE_BLEND_IN" 1 "DI_VHLD_STATE_STANDBY" 0 "DI_VHLD_STATE_UNAVAILABLE" ;
VAL_ 646 DI_onePedalDrivingState 8 "DI_OPD_NUM_STATES" 7 "DI_OPD_MOTOR_BLEND_IN" 6 "DI_OPD_NO_MOTOR" 5 "DI_OPD_MOTOR_BLEND_OUT_ACTIVE" 4 "DI_OPD_MOTOR_BLEND_OUT_PENDING" 3 "DI_OPD_NOMINAL" 2 "DI_OPD_STANDBY" 1 "DI_OPD_QUICK_BRAKE_RAMP" 0 "DI_OPD_UNAVAILABLE" ;
VAL_ 646 DI_regenBackfillState 2 "BFILL_ACTIVE" 1 "BFILL_STANDBY" 0 "BFILL_UNAVAILABLE" ;
VAL_ 646 DI_cruiseNotAvailableReason 50 "DI_CRUISE_NOT_AVAILABLE_AIR_COMPRESSOR_FAULT" 49 "DI_CRUISE_NOT_AVAILABLE_ABS_FAULT" 48 "DI_CRUISE_NOT_AVAILABLE_DRIVERLESS_AUTONOMY_BEHAVIOR" 47 "DI_CRUISE_NOT_AVAILABLE_EPB_DYNAMIC_APPLY" 46 "DI_CRUISE_NOT_AVAILABLE_SGS_REQUEST" 45 "DI_CRUISE_NOT_AVAILABLE_VDC_FAULT" 44 "DI_CRUISE_NOT_AVAILABLE_ACCEL_JERK_OUT_OF_ISO_BOUNDS" 43 "DI_CRUISE_NOT_AVAILABLE_REDUNDANT_BRAKES_ACTIVE" 42 "DI_CRUISE_NOT_AVAILABLE_ABS_UNAVAILABLE" 41 "DI_CRUISE_NOT_AVAILABLE_LONC_DEGRADED" 40 "DI_CRUISE_NOT_AVAILABLE_FACTORY_MODE" 39 "DI_CRUISE_NOT_AVAILABLE_EPB_FAULT" 38 "DI_CRUISE_NOT_AVAILABLE_AEB_STACK_UNAVAILABLE" 37 "DI_CRUISE_NOT_AVAILABLE_AEB_STACK_EVENT_INACTIVE" 36 "DI_CRUISE_NOT_AVAILABLE_DFLK_ENGAGED" 35 "DI_CRUISE_NOT_AVAILABLE_INTERFACE_NOT_SUPPORTED" 34 "DI_CRUISE_NOT_AVAILABLE_CANCEL_ACTIVE" 33 "DI_CRUISE_NOT_AVAILABLE_CONTROL_STACK_SWITCH" 32 "DI_CRUISE_NOT_AVAILABLE_SHIFT_OUTSIDE_SPEED_THRESHOLD" 31 "DI_CRUISE_NOT_AVAILABLE_SHIFT_TIMEOUT" 30 "DI_CRUISE_NOT_AVAILABLE_OFFROAD_MODE_ACTIVE" 29 "DI_CRUISE_NOT_AVAILABLE_DAS_CONTROL_MIA" 28 "DI_CRUISE_NOT_AVAILABLE_UNIT0_FAULT" 27 "DI_CRUISE_NOT_AVAILABLE_BRAKE_TEMPERATURE" 26 "DI_CRUISE_NOT_AVAILABLE_ACC_BACKWARD_AT_HIGH_FORWARD_SPEED" 25 "DI_CRUISE_NOT_AVAILABLE_DAS_SET_SPEED_TOO_HIGH_IN_REVERSE" 24 "DI_CRUISE_NOT_AVAILABLE_MOTOR_SPEED_TOO_HIGH_IN_REVERSE" 23 "DI_CRUISE_NOT_AVAILABLE_VHLD_UNAVAILABLE" 22 "DI_CRUISE_NOT_AVAILABLE_CRUISE_FAULTED" 21 "DI_CRUISE_NOT_AVAILABLE_TRACK_MODE_ACTIVE" 20 "DI_CRUISE_NOT_AVAILABLE_DAS_SNA" 19 "DI_CRUISE_NOT_AVAILABLE_UI_MIA" 18 "DI_CRUISE_NOT_AVAILABLE_WAIT_INIT" 17 "DI_CRUISE_NOT_AVAILABLE_VEL_EST" 16 "DI_CRUISE_NOT_AVAILABLE_MAX_SPEED" 15 "DI_CRUISE_NOT_AVAILABLE_MIN_SPEED" 14 "DI_CRUISE_NOT_AVAILABLE_AEB" 13 "DI_CRUISE_NOT_AVAILABLE_CONFIG" 12 "DI_CRUISE_NOT_AVAILABLE_DI_STATE" 11 "DI_CRUISE_NOT_AVAILABLE_MOTOR_SPEED" 10 "DI_CRUISE_NOT_AVAILABLE_EBR" 9 "DI_CRUISE_NOT_AVAILABLE_VALET_MODE" 8 "DI_CRUISE_NOT_AVAILABLE_SEAT_BELT_UNBUCKLED" 7 "DI_CRUISE_NOT_AVAILABLE_CLOSURE_OPEN" 6 "DI_CRUISE_NOT_AVAILABLE_ACC_CANCEL" 5 "DI_CRUISE_NOT_AVAILABLE_ABS_ACTIVE" 4 "DI_CRUISE_NOT_AVAILABLE_TC_ACTIVE" 3 "DI_CRUISE_NOT_AVAILABLE_VDC_ACTIVE_OR_DEGRADED" 2 "DI_CRUISE_NOT_AVAILABLE_VDC_OR_TC_OFF" 1 "DI_CRUISE_NOT_AVAILABLE_NO_ALERT" 0 "DI_CRUISE_NOT_AVAILABLE_NONE" ;
VAL_ 646 DI_cruiseFaultReason 22 "DI_CRUISE_FAULT_VHLD_FAULTED" 21 "DI_CRUISE_FAULT_CONFIG_MISMATCH" 20 "DI_CRUISE_FAULT_EPB_MIA" 19 "DI_CRUISE_FAULT_ACCEL_JERK_OUT_OF_ISO_BOUNDS" 17 "DI_CRUISE_FAULT_DAS_SNA" 16 "DI_CRUISE_FAULT_VELOCITY_ESTIMATE_NOT_NORMAL" 15 "DI_CRUISE_FAULT_ACCEL_OUT_OF_BOUNDS" 14 "DI_CRUISE_FAULT_EBR_FAULT" 13 "DI_CRUISE_FAULT_TC_FAULT" 12 "DI_CRUISE_FAULT_ESP_MIA" 11 "DI_CRUISE_FAULT_VDC_FAULT" 10 "DI_CRUISE_FAULT_EPB_FAULT" 9 "DI_CRUISE_FAULT_BRAKE_MIA" 8 "DI_CRUISE_FAULT_CRS_STATE_MISM" 7 "DI_CRUISE_FAULT_ABS_MIA" 6 "DI_CRUISE_FAULT_CRUISE_SCCM_MIA" 5 "DI_CRUISE_FAULT_BRAKE_INVALID" 4 "DI_CRUISE_FAULT_STALK" 3 "DI_CRUISE_FAULT_PM_REQUEST" 2 "DI_CRUISE_FAULT_PM_MIA" 1 "DI_CRUISE_FAULT_MOTOR_SPEED_MISMATCH" 0 "DI_CRUISE_FAULT_NONE" ;
VAL_ 646 DI_cruiseCancelReason 11 "DI_CRUISE_CANCEL_DAS_MIA_PEDAL_APPLY" 10 "DI_CRUISE_CANCEL_ACC_FSD_EXIT" 9 "DI_CRUISE_CANCEL_SHIFT_REQUEST" 8 "DI_CRUISE_CANCEL_ACCEL_OVERRIDE_IN_REVERSE" 7 "DI_CRUISE_CANCEL_DAS" 6 "DI_CRUISE_CANCEL_PARK" 5 "DI_CRUISE_CANCEL_GEAR" 4 "DI_CRUISE_CANCEL_STALK" 3 "DI_CRUISE_CANCEL_BRAKE" 2 "DI_CRUISE_CANCEL_SKID" 1 "DI_CRUISE_CANCEL_APC_REQUEST" 0 "DI_CRUISE_CANCEL_NONE" ;
VAL_ 1270 DI_doublePedalState 12 "DBL_BRKSTAND_TRQ_RAMPUP_DONE" 11 "DBL_BRKSTAND_LAUNCH" 10 "DBL_BRKSTAND_TRQ_HOLD" 9 "DBL_BRKSTAND_INIT_TRQ_RAMPUP" 8 "DBL_BRKSTAND_ARMED2" 7 "DBL_BRKSTAND_ARMED1" 6 "DBL_BRKOVR_RAMPUP" 5 "DBL_BRKOVR_RAMPDOWN" 4 "DBL_BRKPRESS_PREOVR" 3 "DBL_BRKPRESS_RAMPUP" 2 "DBL_BRKPRESS_RAMPDOWN" 1 "DBL_DRIVING" 0 "DBL_IDLE" ;
VAL_ 1270 DI_autopilotRequest 1 "DI_AP_RQST_ACTIVATE" 0 "DI_AP_RQST_IDLE" ;
VAL_ 1270 DI_rollPreventionState 7 "DI_RP_STATE_INIT" 6 "DI_RP_STATE_FAULT" 5 "DI_RP_STATE_MAX_BRAKE_TORQUE" 4 "DI_RP_STATE_HOLD" 3 "DI_RP_STATE_BUILD" 2 "DI_RP_STATE_READY" 1 "DI_RP_STATE_STANDBY" 0 "DI_RP_STATE_UNAVAILABLE" ;
VAL_ 1270 DI_pedalAssistCurveSelectForSX 15 "PEDAL_ASSIST_CURVE_15" 12 "PEDAL_ASSIST_CURVE_12" 11 "PEDAL_ASSIST_CURVE_11" 8 "PEDAL_ASSIST_CURVE_8" 6 "PEDAL_ASSIST_CURVE_6" 3 "PEDAL_ASSIST_CURVE_3" 0 "PEDAL_ASSIST_CURVE_0" ;
VAL_ 1270 DI_longitudinalControlStack 7 "VELOCITY_PROFILE_CONTROL_SUPPRESS_CANCEL" 6 "DIRECT_TORQUE_CONTROL" 5 "DIRECT_PEDAL_CONTROL" 4 "AEB_CONTROL" 3 "VELOCITY_PROFILE_CONTROL" 2 "LONC_TORQUE_PROFILER" 1 "LEGACY_CRUISE" 0 "REQUEST_SNA" ;
VAL_ 1270 DI_regenBlendingState 3 "BLEND_FRICTION_ONLY" 2 "BLEND_ACTIVE" 1 "BLEND_STANDBY" 0 "BLEND_UNAVAILABLE" ;
VAL_ 822 DI_performancePackage 6 "PERFORMANCE_2022" 5 "BASE_PLUS_2022" 4 "BASE_2022" 3 "BASE_PLUS" 2 "BASE_2024" 1 "PERFORMANCE" 0 "BASE" ;
VAL_ 599 DI_uiSpeedUnits 1 "DI_SPEED_KPH" 0 "DI_SPEED_MPH" ;
VAL_ 599 DI_velocityEstimatorState 5 "VE_STATE_BACKUP_MOTOR" 4 "VE_STATE_BACKUP_WHEELS_B" 3 "VE_STATE_BACKUP_WHEELS_A" 2 "VE_STATE_WHEELS_REDUCED" 1 "VE_STATE_WHEELS_NORMAL" 0 "VE_STATE_NOT_INITIALIZED" ;
VAL_ 597 DI_lastQualifiedGear 7 "DI_GEAR_SNA" 4 "DI_GEAR_D" 3 "DI_GEAR_N" 2 "DI_GEAR_R" 1 "DI_GEAR_P" 0 "DI_GEAR_INVALID" ;
VAL_ 597 DI_lastDrivingGear 7 "DI_GEAR_SNA" 4 "DI_GEAR_D" 3 "DI_GEAR_N" 2 "DI_GEAR_R" 1 "DI_GEAR_P" 0 "DI_GEAR_INVALID" ;
VAL_ 597 DI_suggestedGearReason 14 "REASON_1ST_SHFT_PAR_PARK_NO_USS" 13 "REASON_AP_NOT_READY" 12 "REASON_EEPROM" 11 "REASON_AP_MIA" 10 "REASON_AP_NOT_CONFIDENT" 9 "REASON_AP" 8 "REASON_SUB_SHFT" 7 "REASON_SUB_SHFT_PAR_PARK" 6 "REASON_SUB_SHFT_RE_BLCK_PAR_PARK" 5 "REASON_SUB_SHFT_RE_BLCK" 4 "REASON_1ST_SHFT_FR_BLCK_PAR_PARK" 3 "REASON_1ST_SHFT_RE_BLCK" 2 "REASON_1ST_SHFT_FR_BLCK" 1 "REASON_1ST_SHFT_PAR_PARK" 0 "REASON_RETRACE" ;
VAL_ 597 DI_smartShiftGear 2 "REVERSE" 1 "DRIVE" 0 "NONE" ;
VAL_ 597 DI_smartShiftUnavailableReason 18 "SMART_SHIFT_UNAVAILABLE_DAS_MIA" 17 "SMART_SHIFT_UNAVAILABLE_DAS_NOT_CONFIDENT" 16 "SMART_SHIFT_UNAVAILABLE_DISPLAY_ERROR" 15 "SMART_SHIFT_UNAVAILABLE_VDC_UNAVAILABLE" 14 "SMART_SHIFT_UNAVAILABLE_VHLD_UNAVAILABLE" 13 "SMART_SHIFT_UNAVAILABLE_OPD_UNAVAILABLE" 12 "SMART_SHIFT_UNAVAILABLE_BLS_UNKNOWN" 11 "SMART_SHIFT_UNAVAILABLE_IBST_MIA" 10 "SMART_SHIFT_SILENT_UNAVAILABLE_AEB_ACTIVE" 9 "SMART_SHIFT_SILENT_UNAVAILABLE_CRUISE_REGULATING" 8 "SMART_SHIFT_SILENT_UNAVAILABLE_GTW_NOT_QUALIFIED" 7 "SMART_SHIFT_SILENT_UNAVAILABLE_SGS_ACTIVE" 6 "SMART_SHIFT_SILENT_UNAVAILABLE_CLOSURE_OPEN" 5 "SMART_SHIFT_SILENT_UNAVAILABLE_CHARGE_CABLE_CONNECTED" 4 "SMART_SHIFT_SILENT_UNAVAILABLE_DRIVER_BUCKLED_QF" 3 "SMART_SHIFT_SILENT_UNAVAILABLE_NON_STANDARD_MODE" 2 "SMART_SHIFT_SILENT_UNAVAILABLE_UI_DISABLE" 1 "SMART_SHIFT_UNAVAILABLE_NONE" 0 "SMART_SHIFT_UNAVAILABLE_SNA" ;
VAL_ 296 DI_vehicleSpeedLimitType 2 "POWERTRAIN" 1 "USER" 0 "NONE" ;
VAL_ 296 DI_vehicleSpeedLimitReason 16 "MANUAL_RECOVERY_MODE" 15 "FACTORY_BRAKE_BURNISHING" 14 "TAS_OFFROAD" 13 "SLIP_START_LIMIT" 12 "LV_DEGRADED" 11 "MAX_TIRE_TYPE" 10 "USER" 9 "FRUNK_OPEN" 8 "DAS_PEDAL_CONTROL" 7 "TAS" 6 "TRAILER_MODE" 5 "MAX_CAR_CONFIG" 4 "SERVICE_MODE" 3 "FACTORY_MODE" 2 "FACTORY_LOW_BRAKE_FLUID" 1 "DRIVE_UNIT_LIMIT" 0 "NONE" ;
VAL_ 296 DI_immobilizerAuthLevel 3 "IMMOBILIZER_AUTH_LEVEL_MANUAL_RECOVERY" 2 "IMMOBILIZER_AUTH_LEVEL_AUTONOMY" 1 "IMMOBILIZER_AUTH_LEVEL_USER_DRIVE" 0 "IMMOBILIZER_AUTH_LEVEL_NONE" ;
VAL_ 296 DI_restrictedDrivingMode 1 "RESTRICTED_DRIVING_MANUAL_RECOVERY" 0 "RESTRICTED_DRIVING_MODE_NONE" ;
VAL_ 616 DI_primaryUnitSiliconType 1 "IGBT" 0 "MOSFET" ;
VAL_ 280 DI_secondaryGearControlStatus 1 "ACTIVE" 0 "NOT_ACTIVE" ;
VAL_ 280 DI_immobilizerState 6 "DI_IMM_STATE_FAULT" 5 "DI_IMM_STATE_RESET" 4 "DI_IMM_STATE_IDLE" 3 "DI_IMM_STATE_DISARMED" 2 "DI_IMM_STATE_AUTHENTICATING" 1 "DI_IMM_STATE_REQUEST" 0 "DI_IMM_STATE_INIT_SNA" ;
VAL_ 280 DI_systemState 5 "DI_SYS_ENABLE" 4 "DI_SYS_ABORT" 3 "DI_SYS_FAULT" 2 "DI_SYS_STANDBY" 1 "DI_SYS_IDLE" 0 "DI_SYS_UNAVAILABLE" ;
VAL_ 280 DI_brakePedalState 2 "INVALID" 1 "ON" 0 "OFF" ;
VAL_ 280 DI_gear 7 "DI_GEAR_SNA" 4 "DI_GEAR_D" 3 "DI_GEAR_N" 2 "DI_GEAR_R" 1 "DI_GEAR_P" 0 "DI_GEAR_INVALID" ;
VAL_ 280 DI_driveBlocked 4 "DRIVE_BLOCKED_TRUNK" 3 "DRIVE_BLOCKED_FALCON" 2 "DRIVE_BLOCKED_PROX" 1 "DRIVE_BLOCKED_FRUNK" 0 "DRIVE_BLOCKED_NONE" ;
VAL_ 280 DI_hvilSystemStatus 2 "CLOSED" 1 "OPEN" 0 "DISABLED" ;
VAL_ 280 DI_driveModeState 1 "DM_STATE_DRIVE" 0 "DM_STATE_NONDRIVE" ;
VAL_ 280 DI_shiftRequestType 3 "SMART_SHIFT" 2 "CCCM_SHIFT" 1 "GTW_SHIFT" 0 "NONE" ;
VAL_ 280 DI_tractionControlMode 7 "TC_SLIPPERY_SURFACE" 6 "TC_OFFROAD_ASSIST" 5 "TC_DYNO_MODE" 4 "TC_ROLLS_MODE" 3 "TC_DEV_MODE_2" 2 "TC_DEV_MODE_1" 1 "TC_SLIP_START" 0 "TC_NORMAL" ;
VAL_ 280 DI_epbRequest 2 "DI_EPBREQUEST_UNPARK" 1 "DI_EPBREQUEST_PARK" 0 "DI_EPBREQUEST_NO_REQUEST" ;
VAL_ 280 DI_brakeSource 1 "DI" 0 "DAS" ;
VAL_ 280 DI_keepDrivePowerStateRequest 1 "KEEP_ALIVE" 0 "NO_REQUEST" ;
VAL_ 280 DI_trackModeState 2 "TRACK_MODE_ON" 1 "TRACK_MODE_AVAILABLE" 0 "TRACK_MODE_UNAVAILABLE" ;
VAL_ 2036 DI_vdcCommandTypeFrR 3 "VDC_SLIP_COMMAND" 2 "VDC_TORQUE_COMMAND" 1 "BTC_TORQUE_COMMAND" 0 "NO_TORQUE_COMMAND" ;
VAL_ 2036 DI_vdcCommandTypeReR 3 "VDC_SLIP_COMMAND" 2 "VDC_TORQUE_COMMAND" 1 "BTC_TORQUE_COMMAND" 0 "NO_TORQUE_COMMAND" ;
VAL_ 2036 DI_vdcCommandABSFrR 4 "MODIFY_BY_ABS_NO_GMA_NO_EBD" 3 "MODIFY_BY_ABS_NO_GMA" 2 "MODIFY_BY_ABS_ALL" 1 "FEED_THROUGH" 0 "NO_COMMAND" ;
VAL_ 2036 DI_vdcCommandABSReR 4 "MODIFY_BY_ABS_NO_GMA_NO_EBD" 3 "MODIFY_BY_ABS_NO_GMA" 2 "MODIFY_BY_ABS_ALL" 1 "FEED_THROUGH" 0 "NO_COMMAND" ;
VAL_ 615 DI_trailerDetected 1 "TRAILER_DETECTED" 0 "TRAILER_NOT_DETECTED" ;
VAL_ 615 DI_tireFitment 3 "FITMENT_SNA" 1 "FITMENT_STAGGERED" 0 "FITMENT_SQUARE" ;
VAL_ 615 DI_massConfidence 1 "MASS_CONFIDED" 0 "MASS_NOT_CONFIDED" ;
VAL_ 615 DI_massConfidenceRLS 1 "MASS_CONFIDED" 0 "MASS_NOT_CONFIDED" ;
